VERSION ""

NS_ :

BS_:

BU_: ILC4 ILC3 ILC2 ILC1 C1 C0 ACU ECAS2 CCU TPMS ACC AEBS Door4 Door3 Door2 Door1 WWCU HVAC HVAC_HMI EPHS LDWS SCSM EVCC ECAS1 BMS SWS EBS VCU2 PCi_ECM DCU EPH VFC VCU1 Tachograph EPIC

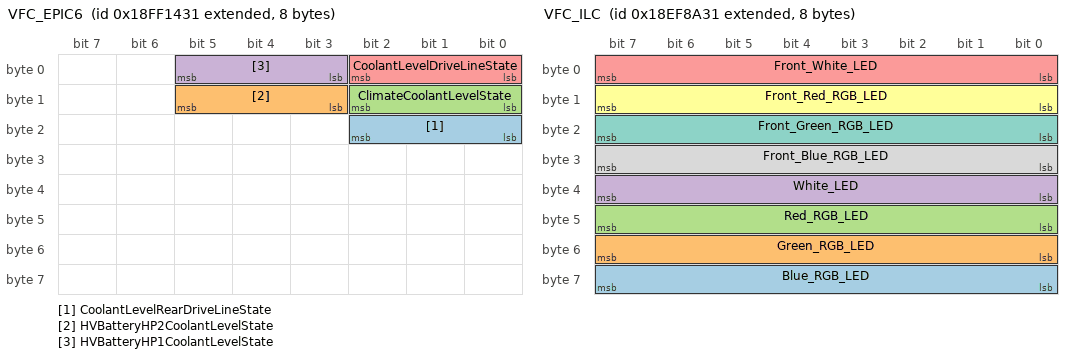
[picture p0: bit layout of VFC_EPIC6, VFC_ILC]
BO_ 2566853681 VFC_EPIC6: 8 VFC
 SG_ CoolantLevelRearDriveLineState : 16|3@1+ (1,0) [0|0] "" Vector__XXX
 SG_ HVBatteryHP2CoolantLevelState : 11|3@1+ (1,0) [0|0] "" Vector__XXX
 SG_ ClimateCoolantLevelState : 8|3@1+ (1,0) [0|0] "" Vector__XXX
 SG_ HVBatteryHP1CoolantLevelState : 3|3@1+ (1,0) [0|0] "" Vector__XXX
 SG_ CoolantLevelDriveLineState : 0|3@1+ (1,0) [0|0] "" Vector__XXX

BO_ 2147548812 DM1_ILC3_0000: 22 ILC3
 SG_ FailureModeIdentifier5 : 160|5@1+ (1,0) [0|0] "" Vector__XXX
 SG_ FailureModeIdentifier4 : 128|5@1+ (1,0) [0|0] "" Vector__XXX
 SG_ FailureModeIdentifier3 : 96|5@1+ (1,0) [0|0] "" Vector__XXX
 SG_ FailureModeIdentifier2 : 64|5@1+ (1,0) [0|0] "" Vector__XXX
 SG_ OccurenceCount5 : 168|7@1+ (1,0) [0|126] "" Vector__XXX
 SG_ OccurenceCount4 : 136|7@1+ (1,0) [0|126] "" Vector__XXX
 SG_ OccurenceCount3 : 104|7@1+ (1,0) [0|126] "" Vector__XXX
 SG_ OccurenceCount2 : 72|7@1+ (1,0) [0|126] "" Vector__XXX
 SG_ SPNConversionMethod5 : 175|1@1+ (1,0) [0|1] "" Vector__XXX
 SG_ SPNConversionMethod4 : 143|1@1+ (1,0) [0|1] "" Vector__XXX
 SG_ SPNConversionMethod3 : 111|1@1+ (1,0) [0|1] "" Vector__XXX
 SG_ SPNConversionMethod2 : 79|1@1+ (1,0) [0|1] "" Vector__XXX
 SG_ SPN5High : 165|3@1+ (1,0) [0|7] "" Vector__XXX
 SG_ SPN5 : 144|16@1+ (1,0) [0|65536] "" Vector__XXX
 SG_ SPN4High : 133|3@1+ (1,0) [0|7] "" Vector__XXX
 SG_ SPN4 : 112|16@1+ (1,0) [0|65536] "" Vector__XXX
 SG_ SPN3High : 101|3@1+ (1,0) [0|7] "" Vector__XXX
 SG_ SPN3 : 80|16@1+ (1,0) [0|65536] "" Vector__XXX
 SG_ SPN2High : 69|3@1+ (1,0) [0|7] "" Vector__XXX
 SG_ SPN2 : 48|16@1+ (1,0) [0|65536] "" Vector__XXX
 SG_ SPN1 : 16|16@1+ (1,0) [0|65536] "" Vector__XXX
 SG_ SPNConversionMethod1 : 47|1@1+ (1,0) [0|1] "" Vector__XXX
 SG_ OccurenceCount1 : 40|7@1+ (1,0) [0|126] "" Vector__XXX
 SG_ SPN1High : 37|3@1+ (1,0) [0|7] "" Vector__XXX
 SG_ FailureModeIdentifier1 : 32|5@1+ (1,0) [0|0] "" Vector__XXX
 SG_ FlashMalfuncIndicatorLamp : 14|2@1+ (1,0) [0|3] "" Vector__XXX
 SG_ FlashRedStopLamp : 12|2@1+ (1,0) [0|3] "" Vector__XXX
 SG_ FlashAmberWarningLamp : 10|2@1+ (1,0) [0|3] "" Vector__XXX
 SG_ FlashProtectLamp : 8|2@1+ (1,0) [0|3] "" Vector__XXX
 SG_ MalfunctionIndicatorLampStatus : 6|2@1+ (1,0) [0|3] "" Vector__XXX
 SG_ RedStopLampState : 4|2@1+ (1,0) [0|3] "" Vector__XXX
 SG_ AmberWarningLampStatus : 2|2@1+ (1,0) [0|3] "" Vector__XXX
 SG_ ProtectLampStatus : 0|2@1+ (1,0) [0|3] "" Vector__XXX

BO_ 2566834829 DM1_ILC4: 22 ILC4
 SG_ FailureModeIdentifier5 : 160|5@1+ (1,0) [0|0] "" Vector__XXX
 SG_ FailureModeIdentifier4 : 128|5@1+ (1,0) [0|0] "" Vector__XXX
 SG_ FailureModeIdentifier3 : 96|5@1+ (1,0) [0|0] "" Vector__XXX
 SG_ FailureModeIdentifier2 : 64|5@1+ (1,0) [0|0] "" Vector__XXX
 SG_ OccurenceCount5 : 168|7@1+ (1,0) [0|126] "" Vector__XXX
 SG_ OccurenceCount4 : 136|7@1+ (1,0) [0|126] "" Vector__XXX
 SG_ OccurenceCount3 : 104|7@1+ (1,0) [0|126] "" Vector__XXX
 SG_ OccurenceCount2 : 72|7@1+ (1,0) [0|126] "" Vector__XXX
 SG_ SPNConversionMethod5 : 175|1@1+ (1,0) [0|1] "" Vector__XXX
 SG_ SPNConversionMethod4 : 143|1@1+ (1,0) [0|1] "" Vector__XXX
 SG_ SPNConversionMethod3 : 111|1@1+ (1,0) [0|1] "" Vector__XXX
 SG_ SPNConversionMethod2 : 79|1@1+ (1,0) [0|1] "" Vector__XXX
 SG_ SPN5High : 165|3@1+ (1,0) [0|7] "" Vector__XXX
 SG_ SPN5 : 144|16@1+ (1,0) [0|65536] "" Vector__XXX
 SG_ SPN4High : 133|3@1+ (1,0) [0|7] "" Vector__XXX
 SG_ SPN4 : 112|16@1+ (1,0) [0|65536] "" Vector__XXX
 SG_ SPN3High : 101|3@1+ (1,0) [0|7] "" Vector__XXX
 SG_ SPN3 : 80|16@1+ (1,0) [0|65536] "" Vector__XXX
 SG_ SPN2High : 69|3@1+ (1,0) [0|7] "" Vector__XXX
 SG_ SPN2 : 48|16@1+ (1,0) [0|65536] "" Vector__XXX
 SG_ SPN1 : 16|16@1+ (1,0) [0|65536] "" Vector__XXX
 SG_ SPNConversionMethod1 : 47|1@1+ (1,0) [0|1] "" Vector__XXX
 SG_ OccurenceCount1 : 40|7@1+ (1,0) [0|126] "" Vector__XXX
 SG_ SPN1High : 37|3@1+ (1,0) [0|7] "" Vector__XXX
 SG_ FailureModeIdentifier1 : 32|5@1+ (1,0) [0|0] "" Vector__XXX
 SG_ FlashMalfuncIndicatorLamp : 14|2@1+ (1,0) [0|3] "" Vector__XXX
 SG_ FlashRedStopLamp : 12|2@1+ (1,0) [0|3] "" Vector__XXX
 SG_ FlashAmberWarningLamp : 10|2@1+ (1,0) [0|3] "" Vector__XXX
 SG_ FlashProtectLamp : 8|2@1+ (1,0) [0|3] "" Vector__XXX
 SG_ MalfunctionIndicatorLampStatus : 6|2@1+ (1,0) [0|3] "" Vector__XXX
 SG_ RedStopLampState : 4|2@1+ (1,0) [0|3] "" Vector__XXX
 SG_ AmberWarningLampStatus : 2|2@1+ (1,0) [0|3] "" Vector__XXX
 SG_ ProtectLampStatus : 0|2@1+ (1,0) [0|3] "" Vector__XXX

BO_ 2147483648 DM1_ILC3: 22 Vector__XXX
 SG_ FailureModeIdentifier5 : 160|5@1+ (1,0) [0|0] "" Vector__XXX
 SG_ FailureModeIdentifier4 : 128|5@1+ (1,0) [0|0] "" Vector__XXX
 SG_ FailureModeIdentifier3 : 96|5@1+ (1,0) [0|0] "" Vector__XXX
 SG_ FailureModeIdentifier2 : 64|5@1+ (1,0) [0|0] "" Vector__XXX
 SG_ OccurenceCount5 : 168|7@1+ (1,0) [0|126] "" Vector__XXX
 SG_ OccurenceCount4 : 136|7@1+ (1,0) [0|126] "" Vector__XXX
 SG_ OccurenceCount3 : 104|7@1+ (1,0) [0|126] "" Vector__XXX
 SG_ OccurenceCount2 : 72|7@1+ (1,0) [0|126] "" Vector__XXX
 SG_ SPNConversionMethod5 : 175|1@1+ (1,0) [0|1] "" Vector__XXX
 SG_ SPNConversionMethod4 : 143|1@1+ (1,0) [0|1] "" Vector__XXX
 SG_ SPNConversionMethod3 : 111|1@1+ (1,0) [0|1] "" Vector__XXX
 SG_ SPNConversionMethod2 : 79|1@1+ (1,0) [0|1] "" Vector__XXX
 SG_ SPN5High : 165|3@1+ (1,0) [0|7] "" Vector__XXX
 SG_ SPN5 : 144|16@1+ (1,0) [0|65536] "" Vector__XXX
 SG_ SPN4High : 133|3@1+ (1,0) [0|7] "" Vector__XXX
 SG_ SPN4 : 112|16@1+ (1,0) [0|65536] "" Vector__XXX
 SG_ SPN3High : 101|3@1+ (1,0) [0|7] "" Vector__XXX
 SG_ SPN3 : 80|16@1+ (1,0) [0|65536] "" Vector__XXX
 SG_ SPN2High : 69|3@1+ (1,0) [0|7] "" Vector__XXX
 SG_ SPN2 : 48|16@1+ (1,0) [0|65536] "" Vector__XXX
 SG_ SPN1 : 16|16@1+ (1,0) [0|65536] "" Vector__XXX
 SG_ SPNConversionMethod1 : 47|1@1+ (1,0) [0|1] "" Vector__XXX
 SG_ OccurenceCount1 : 40|7@1+ (1,0) [0|126] "" Vector__XXX
 SG_ SPN1High : 37|3@1+ (1,0) [0|7] "" Vector__XXX
 SG_ FailureModeIdentifier1 : 32|5@1+ (1,0) [0|0] "" Vector__XXX
 SG_ FlashMalfuncIndicatorLamp : 14|2@1+ (1,0) [0|3] "" Vector__XXX
 SG_ FlashRedStopLamp : 12|2@1+ (1,0) [0|3] "" Vector__XXX
 SG_ FlashAmberWarningLamp : 10|2@1+ (1,0) [0|3] "" Vector__XXX
 SG_ FlashProtectLamp : 8|2@1+ (1,0) [0|3] "" Vector__XXX
 SG_ MalfunctionIndicatorLampStatus : 6|2@1+ (1,0) [0|3] "" Vector__XXX
 SG_ RedStopLampState : 4|2@1+ (1,0) [0|3] "" Vector__XXX
 SG_ AmberWarningLampStatus : 2|2@1+ (1,0) [0|3] "" Vector__XXX
 SG_ ProtectLampStatus : 0|2@1+ (1,0) [0|3] "" Vector__XXX

BO_ 2566834827 DM1_ILC2: 22 ILC2
 SG_ FailureModeIdentifier5 : 160|5@1+ (1,0) [0|0] "" Vector__XXX
 SG_ FailureModeIdentifier4 : 128|5@1+ (1,0) [0|0] "" Vector__XXX
 SG_ FailureModeIdentifier3 : 96|5@1+ (1,0) [0|0] "" Vector__XXX
 SG_ FailureModeIdentifier2 : 64|5@1+ (1,0) [0|0] "" Vector__XXX
 SG_ OccurenceCount5 : 168|7@1+ (1,0) [0|126] "" Vector__XXX
 SG_ OccurenceCount4 : 136|7@1+ (1,0) [0|126] "" Vector__XXX
 SG_ OccurenceCount3 : 104|7@1+ (1,0) [0|126] "" Vector__XXX
 SG_ OccurenceCount2 : 72|7@1+ (1,0) [0|126] "" Vector__XXX
 SG_ SPNConversionMethod5 : 175|1@1+ (1,0) [0|1] "" Vector__XXX
 SG_ SPNConversionMethod4 : 143|1@1+ (1,0) [0|1] "" Vector__XXX
 SG_ SPNConversionMethod3 : 111|1@1+ (1,0) [0|1] "" Vector__XXX
 SG_ SPNConversionMethod2 : 79|1@1+ (1,0) [0|1] "" Vector__XXX
 SG_ SPN5High : 165|3@1+ (1,0) [0|7] "" Vector__XXX
 SG_ SPN5 : 144|16@1+ (1,0) [0|65536] "" Vector__XXX
 SG_ SPN4High : 133|3@1+ (1,0) [0|7] "" Vector__XXX
 SG_ SPN4 : 112|16@1+ (1,0) [0|65536] "" Vector__XXX
 SG_ SPN3High : 101|3@1+ (1,0) [0|7] "" Vector__XXX
 SG_ SPN3 : 80|16@1+ (1,0) [0|65536] "" Vector__XXX
 SG_ SPN2High : 69|3@1+ (1,0) [0|7] "" Vector__XXX
 SG_ SPN2 : 48|16@1+ (1,0) [0|65536] "" Vector__XXX
 SG_ SPN1 : 16|16@1+ (1,0) [0|65536] "" Vector__XXX
 SG_ SPNConversionMethod1 : 47|1@1+ (1,0) [0|1] "" Vector__XXX
 SG_ OccurenceCount1 : 40|7@1+ (1,0) [0|126] "" Vector__XXX
 SG_ SPN1High : 37|3@1+ (1,0) [0|7] "" Vector__XXX
 SG_ FailureModeIdentifier1 : 32|5@1+ (1,0) [0|0] "" Vector__XXX
 SG_ FlashMalfuncIndicatorLamp : 14|2@1+ (1,0) [0|3] "" Vector__XXX
 SG_ FlashRedStopLamp : 12|2@1+ (1,0) [0|3] "" Vector__XXX
 SG_ FlashAmberWarningLamp : 10|2@1+ (1,0) [0|3] "" Vector__XXX
 SG_ FlashProtectLamp : 8|2@1+ (1,0) [0|3] "" Vector__XXX
 SG_ MalfunctionIndicatorLampStatus : 6|2@1+ (1,0) [0|3] "" Vector__XXX
 SG_ RedStopLampState : 4|2@1+ (1,0) [0|3] "" Vector__XXX
 SG_ AmberWarningLampStatus : 2|2@1+ (1,0) [0|3] "" Vector__XXX
 SG_ ProtectLampStatus : 0|2@1+ (1,0) [0|3] "" Vector__XXX

BO_ 2566834826 DM1_ILC1: 22 ILC1
 SG_ FailureModeIdentifier5 : 160|5@1+ (1,0) [0|0] "" Vector__XXX
 SG_ FailureModeIdentifier4 : 128|5@1+ (1,0) [0|0] "" Vector__XXX
 SG_ FailureModeIdentifier3 : 96|5@1+ (1,0) [0|0] "" Vector__XXX
 SG_ FailureModeIdentifier2 : 64|5@1+ (1,0) [0|0] "" Vector__XXX
 SG_ OccurenceCount5 : 168|7@1+ (1,0) [0|126] "" Vector__XXX
 SG_ OccurenceCount4 : 136|7@1+ (1,0) [0|126] "" Vector__XXX
 SG_ OccurenceCount3 : 104|7@1+ (1,0) [0|126] "" Vector__XXX
 SG_ OccurenceCount2 : 72|7@1+ (1,0) [0|126] "" Vector__XXX
 SG_ SPNConversionMethod5 : 175|1@1+ (1,0) [0|1] "" Vector__XXX
 SG_ SPNConversionMethod4 : 143|1@1+ (1,0) [0|1] "" Vector__XXX
 SG_ SPNConversionMethod3 : 111|1@1+ (1,0) [0|1] "" Vector__XXX
 SG_ SPNConversionMethod2 : 79|1@1+ (1,0) [0|1] "" Vector__XXX
 SG_ SPN5High : 165|3@1+ (1,0) [0|7] "" Vector__XXX
 SG_ SPN5 : 144|16@1+ (1,0) [0|65536] "" Vector__XXX
 SG_ SPN4High : 133|3@1+ (1,0) [0|7] "" Vector__XXX
 SG_ SPN4 : 112|16@1+ (1,0) [0|65536] "" Vector__XXX
 SG_ SPN3High : 101|3@1+ (1,0) [0|7] "" Vector__XXX
 SG_ SPN3 : 80|16@1+ (1,0) [0|65536] "" Vector__XXX
 SG_ SPN2High : 69|3@1+ (1,0) [0|7] "" Vector__XXX
 SG_ SPN2 : 48|16@1+ (1,0) [0|65536] "" Vector__XXX
 SG_ SPN1 : 16|16@1+ (1,0) [0|65536] "" Vector__XXX
 SG_ SPNConversionMethod1 : 47|1@1+ (1,0) [0|1] "" Vector__XXX
 SG_ OccurenceCount1 : 40|7@1+ (1,0) [0|126] "" Vector__XXX
 SG_ SPN1High : 37|3@1+ (1,0) [0|7] "" Vector__XXX
 SG_ FailureModeIdentifier1 : 32|5@1+ (1,0) [0|0] "" Vector__XXX
 SG_ FlashMalfuncIndicatorLamp : 14|2@1+ (1,0) [0|3] "" Vector__XXX
 SG_ FlashRedStopLamp : 12|2@1+ (1,0) [0|3] "" Vector__XXX
 SG_ FlashAmberWarningLamp : 10|2@1+ (1,0) [0|3] "" Vector__XXX
 SG_ FlashProtectLamp : 8|2@1+ (1,0) [0|3] "" Vector__XXX
 SG_ MalfunctionIndicatorLampStatus : 6|2@1+ (1,0) [0|3] "" Vector__XXX
 SG_ RedStopLampState : 4|2@1+ (1,0) [0|3] "" Vector__XXX
 SG_ AmberWarningLampStatus : 2|2@1+ (1,0) [0|3] "" Vector__XXX
 SG_ ProtectLampStatus : 0|2@1+ (1,0) [0|3] "" Vector__XXX

BO_ 2565835313 VFC_ILC: 8 VFC
 SG_ Blue_RGB_LED : 56|8@1+ (0.4,0) [0|250] "%" Vector__XXX
 SG_ Green_RGB_LED : 48|8@1+ (0.4,0) [0|250] "%" Vector__XXX
 SG_ Red_RGB_LED : 40|8@1+ (0.4,0) [0|250] "%" Vector__XXX
 SG_ White_LED : 32|8@1+ (0.4,0) [0|250] "%" Vector__XXX
 SG_ Front_White_LED : 0|8@1+ (0.4,0) [0|250] "%" Vector__XXX
 SG_ Front_Red_RGB_LED : 8|8@1+ (0.4,0) [0|250] "%" Vector__XXX
 SG_ Front_Green_RGB_LED : 16|8@1+ (0.4,0) [0|250] "%" Vector__XXX
 SG_ Front_Blue_RGB_LED : 24|8@1+ (0.4,0) [0|250] "%" Vector__XXX

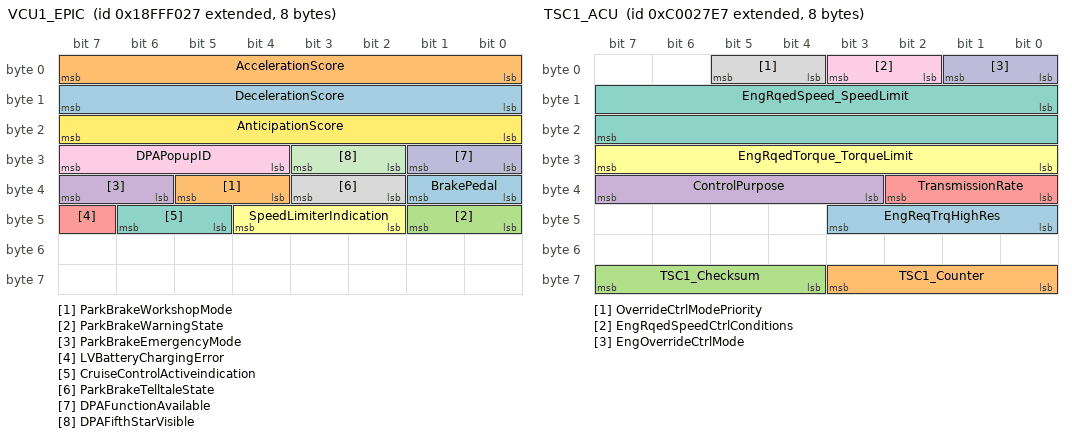
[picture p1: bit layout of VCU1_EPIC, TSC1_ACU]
BO_ 2566909991 VCU1_EPIC: 8 VCU1
 SG_ BrakePedal : 32|2@1+ (1,0) [0|0] "" Vector__XXX
 SG_ ParkBrakeWorkshopMode : 36|2@1+ (1,0) [0|0] "" Vector__XXX
 SG_ ParkBrakeWarningState : 40|2@1+ (1,0) [0|0] "" Vector__XXX
 SG_ ParkBrakeEmergencyMode : 38|2@1+ (1,0) [0|0] "" Vector__XXX
 SG_ LVBatteryChargingError : 47|1@1+ (1,0) [0|0] "" Vector__XXX
 SG_ SpeedLimiterIndication : 42|3@1+ (1,0) [0|0] "" Vector__XXX
 SG_ CruiseControlActiveindication : 45|2@1+ (1,0) [0|0] "" Vector__XXX
 SG_ ParkBrakeTelltaleState : 34|2@1+ (1,0) [0|0] "" Vector__XXX
 SG_ DPAPopupID : 28|4@1+ (1,0) [0|15] "PopupID" Vector__XXX
 SG_ DPAFunctionAvailable : 24|2@1+ (1,0) [0|3] "flag" Vector__XXX
 SG_ DPAFifthStarVisible : 26|2@1+ (1,0) [0|3] "flag" Vector__XXX
 SG_ AnticipationScore : 16|8@1+ (0.5,0) [0|250] "%" Vector__XXX
 SG_ DecelerationScore : 8|8@1+ (0.5,0) [0|250] "%" Vector__XXX
 SG_ AccelerationScore : 0|8@1+ (0.5,0) [0|250] "%" Vector__XXX

BO_ 2566834920 DM1_LDWS: 22 LDWS
 SG_ FailureModeIdentifier5 : 160|5@1+ (1,0) [0|0] "" Vector__XXX
 SG_ FailureModeIdentifier4 : 128|5@1+ (1,0) [0|0] "" Vector__XXX
 SG_ FailureModeIdentifier3 : 96|5@1+ (1,0) [0|0] "" Vector__XXX
 SG_ FailureModeIdentifier2 : 64|5@1+ (1,0) [0|0] "" Vector__XXX
 SG_ OccurenceCount5 : 168|7@1+ (1,0) [0|126] "" Vector__XXX
 SG_ OccurenceCount4 : 136|7@1+ (1,0) [0|126] "" Vector__XXX
 SG_ OccurenceCount3 : 104|7@1+ (1,0) [0|126] "" Vector__XXX
 SG_ OccurenceCount2 : 72|7@1+ (1,0) [0|126] "" Vector__XXX
 SG_ SPNConversionMethod5 : 175|1@1+ (1,0) [0|1] "" Vector__XXX
 SG_ SPNConversionMethod4 : 143|1@1+ (1,0) [0|1] "" Vector__XXX
 SG_ SPNConversionMethod3 : 111|1@1+ (1,0) [0|1] "" Vector__XXX
 SG_ SPNConversionMethod2 : 79|1@1+ (1,0) [0|1] "" Vector__XXX
 SG_ SPN5High : 165|3@1+ (1,0) [0|7] "" Vector__XXX
 SG_ SPN5 : 144|16@1+ (1,0) [0|65536] "" Vector__XXX
 SG_ SPN4High : 133|3@1+ (1,0) [0|7] "" Vector__XXX
 SG_ SPN4 : 112|16@1+ (1,0) [0|65536] "" Vector__XXX
 SG_ SPN3High : 101|3@1+ (1,0) [0|7] "" Vector__XXX
 SG_ SPN3 : 80|16@1+ (1,0) [0|65536] "" Vector__XXX
 SG_ SPN2High : 69|3@1+ (1,0) [0|7] "" Vector__XXX
 SG_ SPN2 : 48|16@1+ (1,0) [0|65536] "" Vector__XXX
 SG_ SPN1 : 16|16@1+ (1,0) [0|65536] "" Vector__XXX
 SG_ SPNConversionMethod1 : 47|1@1+ (1,0) [0|1] "" Vector__XXX
 SG_ OccurenceCount1 : 40|7@1+ (1,0) [0|126] "" Vector__XXX
 SG_ SPN1High : 37|3@1+ (1,0) [0|7] "" Vector__XXX
 SG_ FailureModeIdentifier1 : 32|5@1+ (1,0) [0|0] "" Vector__XXX
 SG_ FlashMalfuncIndicatorLamp : 14|2@1+ (1,0) [0|3] "" Vector__XXX
 SG_ FlashRedStopLamp : 12|2@1+ (1,0) [0|3] "" Vector__XXX
 SG_ FlashAmberWarningLamp : 10|2@1+ (1,0) [0|3] "" Vector__XXX
 SG_ FlashProtectLamp : 8|2@1+ (1,0) [0|3] "" Vector__XXX
 SG_ MalfunctionIndicatorLampStatus : 6|2@1+ (1,0) [0|3] "" Vector__XXX
 SG_ RedStopLampState : 4|2@1+ (1,0) [0|3] "" Vector__XXX
 SG_ AmberWarningLampStatus : 2|2@1+ (1,0) [0|3] "" Vector__XXX
 SG_ ProtectLampStatus : 0|2@1+ (1,0) [0|3] "" Vector__XXX

BO_ 2566834752 DM1_ECAS2: 22 ECAS2
 SG_ FailureModeIdentifier5 : 160|5@1+ (1,0) [0|0] "" Vector__XXX
 SG_ FailureModeIdentifier4 : 128|5@1+ (1,0) [0|0] "" Vector__XXX
 SG_ FailureModeIdentifier3 : 96|5@1+ (1,0) [0|0] "" Vector__XXX
 SG_ FailureModeIdentifier2 : 64|5@1+ (1,0) [0|0] "" Vector__XXX
 SG_ OccurenceCount5 : 168|7@1+ (1,0) [0|126] "" Vector__XXX
 SG_ OccurenceCount4 : 136|7@1+ (1,0) [0|126] "" Vector__XXX
 SG_ OccurenceCount3 : 104|7@1+ (1,0) [0|126] "" Vector__XXX
 SG_ OccurenceCount2 : 72|7@1+ (1,0) [0|126] "" Vector__XXX
 SG_ SPNConversionMethod5 : 175|1@1+ (1,0) [0|1] "" Vector__XXX
 SG_ SPNConversionMethod4 : 143|1@1+ (1,0) [0|1] "" Vector__XXX
 SG_ SPNConversionMethod3 : 111|1@1+ (1,0) [0|1] "" Vector__XXX
 SG_ SPNConversionMethod2 : 79|1@1+ (1,0) [0|1] "" Vector__XXX
 SG_ SPN5High : 165|3@1+ (1,0) [0|7] "" Vector__XXX
 SG_ SPN5 : 144|16@1+ (1,0) [0|65536] "" Vector__XXX
 SG_ SPN4High : 133|3@1+ (1,0) [0|7] "" Vector__XXX
 SG_ SPN4 : 112|16@1+ (1,0) [0|65536] "" Vector__XXX
 SG_ SPN3High : 101|3@1+ (1,0) [0|7] "" Vector__XXX
 SG_ SPN3 : 80|16@1+ (1,0) [0|65536] "" Vector__XXX
 SG_ SPN2High : 69|3@1+ (1,0) [0|7] "" Vector__XXX
 SG_ SPN2 : 48|16@1+ (1,0) [0|65536] "" Vector__XXX
 SG_ SPN1 : 16|16@1+ (1,0) [0|65536] "" Vector__XXX
 SG_ SPNConversionMethod1 : 47|1@1+ (1,0) [0|1] "" Vector__XXX
 SG_ OccurenceCount1 : 40|7@1+ (1,0) [0|126] "" Vector__XXX
 SG_ SPN1High : 37|3@1+ (1,0) [0|7] "" Vector__XXX
 SG_ FailureModeIdentifier1 : 32|5@1+ (1,0) [0|0] "" Vector__XXX
 SG_ FlashMalfuncIndicatorLamp : 14|2@1+ (1,0) [0|3] "" Vector__XXX
 SG_ FlashRedStopLamp : 12|2@1+ (1,0) [0|3] "" Vector__XXX
 SG_ FlashAmberWarningLamp : 10|2@1+ (1,0) [0|3] "" Vector__XXX
 SG_ FlashProtectLamp : 8|2@1+ (1,0) [0|3] "" Vector__XXX
 SG_ MalfunctionIndicatorLampStatus : 6|2@1+ (1,0) [0|3] "" Vector__XXX
 SG_ RedStopLampState : 4|2@1+ (1,0) [0|3] "" Vector__XXX
 SG_ AmberWarningLampStatus : 2|2@1+ (1,0) [0|3] "" Vector__XXX
 SG_ ProtectLampStatus : 0|2@1+ (1,0) [0|3] "" Vector__XXX

BO_ 2566834881 DM1_C1: 22 C1
 SG_ FailureModeIdentifier5 : 160|5@1+ (1,0) [0|0] "" Vector__XXX
 SG_ FailureModeIdentifier4 : 128|5@1+ (1,0) [0|0] "" Vector__XXX
 SG_ FailureModeIdentifier3 : 96|5@1+ (1,0) [0|0] "" Vector__XXX
 SG_ FailureModeIdentifier2 : 64|5@1+ (1,0) [0|0] "" Vector__XXX
 SG_ OccurenceCount5 : 168|7@1+ (1,0) [0|126] "" Vector__XXX
 SG_ OccurenceCount4 : 136|7@1+ (1,0) [0|126] "" Vector__XXX
 SG_ OccurenceCount3 : 104|7@1+ (1,0) [0|126] "" Vector__XXX
 SG_ OccurenceCount2 : 72|7@1+ (1,0) [0|126] "" Vector__XXX
 SG_ SPNConversionMethod5 : 175|1@1+ (1,0) [0|1] "" Vector__XXX
 SG_ SPNConversionMethod4 : 143|1@1+ (1,0) [0|1] "" Vector__XXX
 SG_ SPNConversionMethod3 : 111|1@1+ (1,0) [0|1] "" Vector__XXX
 SG_ SPNConversionMethod2 : 79|1@1+ (1,0) [0|1] "" Vector__XXX
 SG_ SPN5High : 165|3@1+ (1,0) [0|7] "" Vector__XXX
 SG_ SPN5 : 144|16@1+ (1,0) [0|65536] "" Vector__XXX
 SG_ SPN4High : 133|3@1+ (1,0) [0|7] "" Vector__XXX
 SG_ SPN4 : 112|16@1+ (1,0) [0|65536] "" Vector__XXX
 SG_ SPN3High : 101|3@1+ (1,0) [0|7] "" Vector__XXX
 SG_ SPN3 : 80|16@1+ (1,0) [0|65536] "" Vector__XXX
 SG_ SPN2High : 69|3@1+ (1,0) [0|7] "" Vector__XXX
 SG_ SPN2 : 48|16@1+ (1,0) [0|65536] "" Vector__XXX
 SG_ SPN1 : 16|16@1+ (1,0) [0|65536] "" Vector__XXX
 SG_ SPNConversionMethod1 : 47|1@1+ (1,0) [0|1] "" Vector__XXX
 SG_ OccurenceCount1 : 40|7@1+ (1,0) [0|126] "" Vector__XXX
 SG_ SPN1High : 37|3@1+ (1,0) [0|7] "" Vector__XXX
 SG_ FailureModeIdentifier1 : 32|5@1+ (1,0) [0|0] "" Vector__XXX
 SG_ FlashMalfuncIndicatorLamp : 14|2@1+ (1,0) [0|3] "" Vector__XXX
 SG_ FlashRedStopLamp : 12|2@1+ (1,0) [0|3] "" Vector__XXX
 SG_ FlashAmberWarningLamp : 10|2@1+ (1,0) [0|3] "" Vector__XXX
 SG_ FlashProtectLamp : 8|2@1+ (1,0) [0|3] "" Vector__XXX
 SG_ MalfunctionIndicatorLampStatus : 6|2@1+ (1,0) [0|3] "" Vector__XXX
 SG_ RedStopLampState : 4|2@1+ (1,0) [0|3] "" Vector__XXX
 SG_ AmberWarningLampStatus : 2|2@1+ (1,0) [0|3] "" Vector__XXX
 SG_ ProtectLampStatus : 0|2@1+ (1,0) [0|3] "" Vector__XXX

BO_ 2566834880 DM1_C0: 22 C0
 SG_ FailureModeIdentifier5 : 160|5@1+ (1,0) [0|0] "" Vector__XXX
 SG_ FailureModeIdentifier4 : 128|5@1+ (1,0) [0|0] "" Vector__XXX
 SG_ FailureModeIdentifier3 : 96|5@1+ (1,0) [0|0] "" Vector__XXX
 SG_ FailureModeIdentifier2 : 64|5@1+ (1,0) [0|0] "" Vector__XXX
 SG_ OccurenceCount5 : 168|7@1+ (1,0) [0|126] "" Vector__XXX
 SG_ OccurenceCount4 : 136|7@1+ (1,0) [0|126] "" Vector__XXX
 SG_ OccurenceCount3 : 104|7@1+ (1,0) [0|126] "" Vector__XXX
 SG_ OccurenceCount2 : 72|7@1+ (1,0) [0|126] "" Vector__XXX
 SG_ SPNConversionMethod5 : 175|1@1+ (1,0) [0|1] "" Vector__XXX
 SG_ SPNConversionMethod4 : 143|1@1+ (1,0) [0|1] "" Vector__XXX
 SG_ SPNConversionMethod3 : 111|1@1+ (1,0) [0|1] "" Vector__XXX
 SG_ SPNConversionMethod2 : 79|1@1+ (1,0) [0|1] "" Vector__XXX
 SG_ SPN5High : 165|3@1+ (1,0) [0|7] "" Vector__XXX
 SG_ SPN5 : 144|16@1+ (1,0) [0|65536] "" Vector__XXX
 SG_ SPN4High : 133|3@1+ (1,0) [0|7] "" Vector__XXX
 SG_ SPN4 : 112|16@1+ (1,0) [0|65536] "" Vector__XXX
 SG_ SPN3High : 101|3@1+ (1,0) [0|7] "" Vector__XXX
 SG_ SPN3 : 80|16@1+ (1,0) [0|65536] "" Vector__XXX
 SG_ SPN2High : 69|3@1+ (1,0) [0|7] "" Vector__XXX
 SG_ SPN2 : 48|16@1+ (1,0) [0|65536] "" Vector__XXX
 SG_ SPN1 : 16|16@1+ (1,0) [0|65536] "" Vector__XXX
 SG_ SPNConversionMethod1 : 47|1@1+ (1,0) [0|1] "" Vector__XXX
 SG_ OccurenceCount1 : 40|7@1+ (1,0) [0|126] "" Vector__XXX
 SG_ SPN1High : 37|3@1+ (1,0) [0|7] "" Vector__XXX
 SG_ FailureModeIdentifier1 : 32|5@1+ (1,0) [0|0] "" Vector__XXX
 SG_ FlashMalfuncIndicatorLamp : 14|2@1+ (1,0) [0|3] "" Vector__XXX
 SG_ FlashRedStopLamp : 12|2@1+ (1,0) [0|3] "" Vector__XXX
 SG_ FlashAmberWarningLamp : 10|2@1+ (1,0) [0|3] "" Vector__XXX
 SG_ FlashProtectLamp : 8|2@1+ (1,0) [0|3] "" Vector__XXX
 SG_ MalfunctionIndicatorLampStatus : 6|2@1+ (1,0) [0|3] "" Vector__XXX
 SG_ RedStopLampState : 4|2@1+ (1,0) [0|3] "" Vector__XXX
 SG_ AmberWarningLampStatus : 2|2@1+ (1,0) [0|3] "" Vector__XXX
 SG_ ProtectLampStatus : 0|2@1+ (1,0) [0|3] "" Vector__XXX

BO_ 2566834848 DM1_AEBS: 22 AEBS
 SG_ FailureModeIdentifier5 : 160|5@1+ (1,0) [0|0] "" Vector__XXX
 SG_ FailureModeIdentifier4 : 128|5@1+ (1,0) [0|0] "" Vector__XXX
 SG_ FailureModeIdentifier3 : 96|5@1+ (1,0) [0|0] "" Vector__XXX
 SG_ FailureModeIdentifier2 : 64|5@1+ (1,0) [0|0] "" Vector__XXX
 SG_ OccurenceCount5 : 168|7@1+ (1,0) [0|126] "" Vector__XXX
 SG_ OccurenceCount4 : 136|7@1+ (1,0) [0|126] "" Vector__XXX
 SG_ OccurenceCount3 : 104|7@1+ (1,0) [0|126] "" Vector__XXX
 SG_ OccurenceCount2 : 72|7@1+ (1,0) [0|126] "" Vector__XXX
 SG_ SPNConversionMethod5 : 175|1@1+ (1,0) [0|1] "" Vector__XXX
 SG_ SPNConversionMethod4 : 143|1@1+ (1,0) [0|1] "" Vector__XXX
 SG_ SPNConversionMethod3 : 111|1@1+ (1,0) [0|1] "" Vector__XXX
 SG_ SPNConversionMethod2 : 79|1@1+ (1,0) [0|1] "" Vector__XXX
 SG_ SPN5High : 165|3@1+ (1,0) [0|7] "" Vector__XXX
 SG_ SPN5 : 144|16@1+ (1,0) [0|65536] "" Vector__XXX
 SG_ SPN4High : 133|3@1+ (1,0) [0|7] "" Vector__XXX
 SG_ SPN4 : 112|16@1+ (1,0) [0|65536] "" Vector__XXX
 SG_ SPN3High : 101|3@1+ (1,0) [0|7] "" Vector__XXX
 SG_ SPN3 : 80|16@1+ (1,0) [0|65536] "" Vector__XXX
 SG_ SPN2High : 69|3@1+ (1,0) [0|7] "" Vector__XXX
 SG_ SPN2 : 48|16@1+ (1,0) [0|65536] "" Vector__XXX
 SG_ SPN1 : 16|16@1+ (1,0) [0|65536] "" Vector__XXX
 SG_ SPNConversionMethod1 : 47|1@1+ (1,0) [0|1] "" Vector__XXX
 SG_ OccurenceCount1 : 40|7@1+ (1,0) [0|126] "" Vector__XXX
 SG_ SPN1High : 37|3@1+ (1,0) [0|7] "" Vector__XXX
 SG_ FailureModeIdentifier1 : 32|5@1+ (1,0) [0|0] "" Vector__XXX
 SG_ FlashMalfuncIndicatorLamp : 14|2@1+ (1,0) [0|3] "" Vector__XXX
 SG_ FlashRedStopLamp : 12|2@1+ (1,0) [0|3] "" Vector__XXX
 SG_ FlashAmberWarningLamp : 10|2@1+ (1,0) [0|3] "" Vector__XXX
 SG_ FlashProtectLamp : 8|2@1+ (1,0) [0|3] "" Vector__XXX
 SG_ MalfunctionIndicatorLampStatus : 6|2@1+ (1,0) [0|3] "" Vector__XXX
 SG_ RedStopLampState : 4|2@1+ (1,0) [0|3] "" Vector__XXX
 SG_ AmberWarningLampStatus : 2|2@1+ (1,0) [0|3] "" Vector__XXX
 SG_ ProtectLampStatus : 0|2@1+ (1,0) [0|3] "" Vector__XXX

BO_ 2566826033 ACTL_CPP: 8 VFC
 SG_ ArticulationAngle : 0|8@1+ (1,-125) [-125|125] "Deg" Vector__XXX

BO_ 2566907697 PropB_ACUTx: 8 VFC
 SG_ ArticulationProtectionOverrule : 0|2@1+ (1,0) [0|0] "" Vector__XXX

BO_ 2348820455 TSC1_ACU: 8 ACU
 SG_ EngReqTrqHighRes : 40|4@1+ (0.125,0) [0|1.875] ""  VCU1
 SG_ TSC1_Counter : 56|4@1+ (1,0) [0|0] ""  VCU1
 SG_ TSC1_Checksum : 60|4@1+ (1,0) [0|0] ""  VCU1
 SG_ ControlPurpose : 35|5@1+ (1,0) [0|31] ""  VCU1
 SG_ TransmissionRate : 32|3@1+ (1,0) [0|7] ""  VCU1
 SG_ EngRqedTorque_TorqueLimit : 24|8@1+ (1,-125) [-125|125] "%"  VCU1
 SG_ EngRqedSpeed_SpeedLimit : 8|16@1+ (0.125,0) [0|8031.875] "rpm"  VCU1
 SG_ OverrideCtrlModePriority : 4|2@1+ (1,0) [0|3] ""  VCU1
 SG_ EngRqedSpeedCtrlConditions : 2|2@1+ (1,0) [0|3] ""  VCU1
 SG_ EngOverrideCtrlMode : 0|2@1+ (1,0) [0|3] ""  VCU1

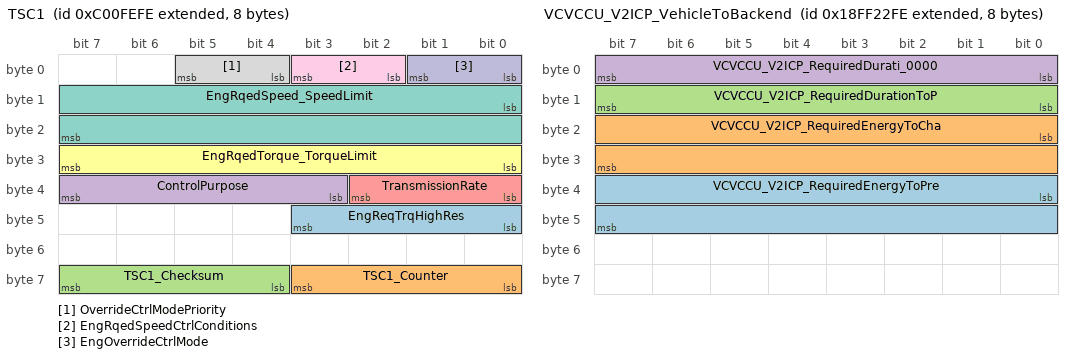
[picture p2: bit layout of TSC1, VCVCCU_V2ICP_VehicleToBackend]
BO_ 2348875518 TSC1: 8 Vector__XXX
 SG_ EngReqTrqHighRes : 40|4@1+ (0.125,0) [0|1.875] "" Vector__XXX
 SG_ TSC1_Counter : 56|4@1+ (1,0) [0|0] "" Vector__XXX
 SG_ TSC1_Checksum : 60|4@1+ (1,0) [0|0] "" Vector__XXX
 SG_ ControlPurpose : 35|5@1+ (1,0) [0|31] "" Vector__XXX
 SG_ TransmissionRate : 32|3@1+ (1,0) [0|7] "" Vector__XXX
 SG_ EngRqedTorque_TorqueLimit : 24|8@1+ (1,-125) [-125|125] "%" Vector__XXX
 SG_ EngRqedSpeed_SpeedLimit : 8|16@1+ (0.125,0) [0|8031.875] "rpm" Vector__XXX
 SG_ OverrideCtrlModePriority : 4|2@1+ (1,0) [0|3] "" Vector__XXX
 SG_ EngRqedSpeedCtrlConditions : 2|2@1+ (1,0) [0|3] "" Vector__XXX
 SG_ EngOverrideCtrlMode : 0|2@1+ (1,0) [0|3] "" Vector__XXX

BO_ 2566844711 CCVS_VCU1: 8 VCU1
 SG_ ParkBrakeReleaseInhibitRq : 6|2@1+ (1,0) [0|3] "" Vector__XXX
 SG_ EngShutdownOverrideSwitch : 62|2@1+ (1,0) [0|3] "" Vector__XXX
 SG_ EngTestModeSwitch : 60|2@1+ (1,0) [0|3] "" Vector__XXX
 SG_ EngIdleDecrementSwitch : 58|2@1+ (1,0) [0|3] "" Vector__XXX
 SG_ EngIdleIncrementSwitch : 56|2@1+ (1,0) [0|3] "" Vector__XXX
 SG_ CruiseCtrlStates : 53|3@1+ (1,0) [0|7] "" Vector__XXX
 SG_ PTOState : 48|5@1+ (1,0) [0|31] "" Vector__XXX
 SG_ CruiseCtrlSetSpeed : 40|8@1+ (1,0) [0|250] "km/h" Vector__XXX
 SG_ CruiseCtrlAccelerateSwitch : 38|2@1+ (1,0) [0|3] "" Vector__XXX
 SG_ CruiseCtrlResumeSwitch : 36|2@1+ (1,0) [0|3] "" Vector__XXX
 SG_ CruiseCtrlCoastSwitch : 34|2@1+ (1,0) [0|3] "" Vector__XXX
 SG_ CruiseCtrlSetSwitch : 32|2@1+ (1,0) [0|3] "" Vector__XXX
 SG_ ClutchSwitch : 30|2@1+ (1,0) [0|3] "" Vector__XXX
 SG_ BrakeSwitch : 28|2@1+ (1,0) [0|3] "" Vector__XXX
 SG_ CruiseCtrlEnableSwitch : 26|2@1+ (1,0) [0|3] "" Vector__XXX
 SG_ CruiseCtrlActive : 24|2@1+ (1,0) [0|3] "" Vector__XXX
 SG_ WheelBasedVehicleSpeed : 8|16@1+ (0.00390625,0) [0|250.996] "km/h" Vector__XXX
 SG_ CruiseCtrlPauseSwitch : 4|2@1+ (1,0) [0|3] "" Vector__XXX
 SG_ ParkingBrakeSwitch : 2|2@1+ (1,0) [0|3] "" Vector__XXX
 SG_ TwoSpeedAxleSwitch : 0|2@1+ (1,0) [0|3] "" Vector__XXX

BO_ 2566844926 CCVS: 8 Vector__XXX
 SG_ ParkBrakeReleaseInhibitRq : 6|2@1+ (1,0) [0|3] "" Vector__XXX
 SG_ EngShutdownOverrideSwitch : 62|2@1+ (1,0) [0|3] "" Vector__XXX
 SG_ EngTestModeSwitch : 60|2@1+ (1,0) [0|3] "" Vector__XXX
 SG_ EngIdleDecrementSwitch : 58|2@1+ (1,0) [0|3] "" Vector__XXX
 SG_ EngIdleIncrementSwitch : 56|2@1+ (1,0) [0|3] "" Vector__XXX
 SG_ CruiseCtrlStates : 53|3@1+ (1,0) [0|7] "" Vector__XXX
 SG_ PTOState : 48|5@1+ (1,0) [0|31] "" Vector__XXX
 SG_ CruiseCtrlSetSpeed : 40|8@1+ (1,0) [0|250] "km/h" Vector__XXX
 SG_ CruiseCtrlAccelerateSwitch : 38|2@1+ (1,0) [0|3] "" Vector__XXX
 SG_ CruiseCtrlResumeSwitch : 36|2@1+ (1,0) [0|3] "" Vector__XXX
 SG_ CruiseCtrlCoastSwitch : 34|2@1+ (1,0) [0|3] "" Vector__XXX
 SG_ CruiseCtrlSetSwitch : 32|2@1+ (1,0) [0|3] "" Vector__XXX
 SG_ ClutchSwitch : 30|2@1+ (1,0) [0|3] "" Vector__XXX
 SG_ BrakeSwitch : 28|2@1+ (1,0) [0|3] "" Vector__XXX
 SG_ CruiseCtrlEnableSwitch : 26|2@1+ (1,0) [0|3] "" Vector__XXX
 SG_ CruiseCtrlActive : 24|2@1+ (1,0) [0|3] "" Vector__XXX
 SG_ WheelBasedVehicleSpeed : 8|16@1+ (0.00390625,0) [0|250.996] "km/h" Vector__XXX
 SG_ CruiseCtrlPauseSwitch : 4|2@1+ (1,0) [0|3] "" Vector__XXX
 SG_ ParkingBrakeSwitch : 2|2@1+ (1,0) [0|3] "" Vector__XXX
 SG_ TwoSpeedAxleSwitch : 0|2@1+ (1,0) [0|3] "" Vector__XXX

BO_ 2566857470 VCVCCU_V2ICP_VehicleToBackend: 8 VFC
 SG_ VCVCCU_V2ICP_RequiredEnergyToPre : 32|16@1+ (1,0) [0|1000] "kWh" Vector__XXX
 SG_ VCVCCU_V2ICP_RequiredEnergyToCha : 16|16@1+ (1,0) [0|1000] "kWh" Vector__XXX
 SG_ VCVCCU_V2ICP_RequiredDurationToP : 8|8@1+ (1,0) [0|250] "min" Vector__XXX
 SG_ VCVCCU_V2ICP_RequiredDurati_0000 : 0|8@1+ (1,0) [0|250] "min" Vector__XXX

BO_ 2563788849 CL_EPH: 8 VFC
 SG_ Illumination : 0|8@1+ (0.4,0) [0|100] "%"  EPH

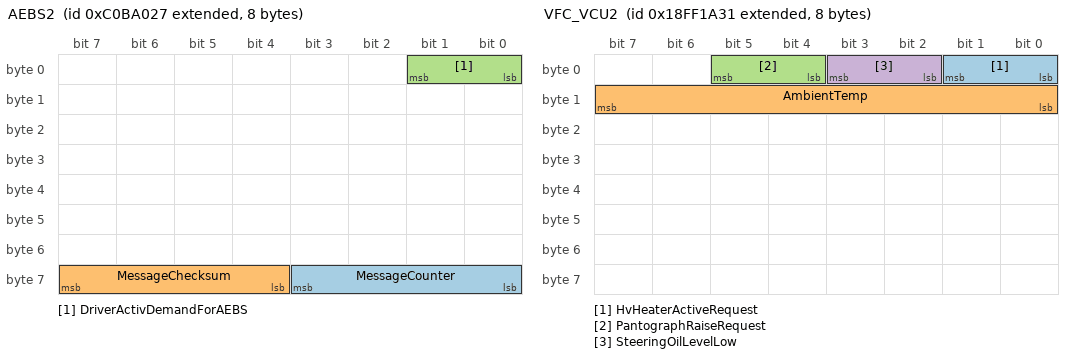
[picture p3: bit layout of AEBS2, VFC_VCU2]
BO_ 2349572135 AEBS2: 8 VFC
 SG_ MessageCounter : 56|4@1+ (1,0) [0|15] "" Vector__XXX
 SG_ MessageChecksum : 60|4@1+ (1,0) [0|15] "" Vector__XXX
 SG_ DriverActivDemandForAEBS : 0|2@1+ (1,0) [0|0] "" Vector__XXX

BO_ 2566855217 VFC_VCU2: 8 VFC
 SG_ HvHeaterActiveRequest : 0|2@1+ (1,0) [0|1] "" Vector__XXX
 SG_ AmbientTemp : 8|8@1+ (0.4,-40) [-40|215] "" Vector__XXX
 SG_ PantographRaiseRequest : 4|2@1+ (1,0) [0|1] "" Vector__XXX
 SG_ SteeringOilLevelLow : 2|2@1+ (1,0) [0|1] "" Vector__XXX

BO_ 2565475121 Req_EBC4: 8 VFC

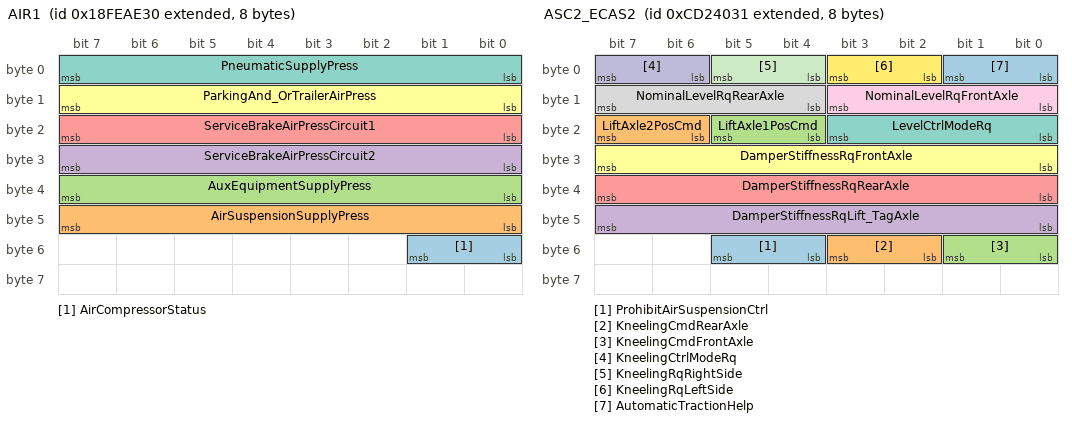
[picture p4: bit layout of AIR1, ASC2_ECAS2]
BO_ 2566827568 AIR1: 8 VFC
 SG_ AirCompressorStatus : 48|2@1+ (1,0) [0|3] "" Vector__XXX
 SG_ AirSuspensionSupplyPress : 40|8@1+ (8,0) [0|2000] "kPa" Vector__XXX
 SG_ AuxEquipmentSupplyPress : 32|8@1+ (8,0) [0|2000] "kPa" Vector__XXX
 SG_ ServiceBrakeAirPressCircuit2 : 24|8@1+ (8,0) [0|2000] "kPa" Vector__XXX
 SG_ ServiceBrakeAirPressCircuit1 : 16|8@1+ (8,0) [0|2000] "kPa" Vector__XXX
 SG_ ParkingAnd_OrTrailerAirPress : 8|8@1+ (8,0) [0|2000] "kPa" Vector__XXX
 SG_ PneumaticSupplyPress : 0|8@1+ (8,0) [0|2000] "kPa" Vector__XXX

BO_ 2362589233 ASC2_ECAS2: 8 VFC
 SG_ ProhibitAirSuspensionCtrl : 52|2@1+ (1,0) [0|3] ""  ECAS2
 SG_ KneelingCmdRearAxle : 50|2@1+ (1,0) [0|3] ""  ECAS2
 SG_ KneelingCmdFrontAxle : 48|2@1+ (1,0) [0|3] ""  ECAS2
 SG_ DamperStiffnessRqLift_TagAxle : 40|8@1+ (0.4,0) [0|100] "%"  ECAS2
 SG_ DamperStiffnessRqRearAxle : 32|8@1+ (0.4,0) [0|100] "%"  ECAS2
 SG_ DamperStiffnessRqFrontAxle : 24|8@1+ (0.4,0) [0|100] "%"  ECAS2
 SG_ LevelCtrlModeRq : 16|4@1+ (1,0) [0|15] ""  ECAS2
 SG_ NominalLevelRqRearAxle : 12|4@1+ (1,0) [0|15] ""  ECAS2
 SG_ NominalLevelRqFrontAxle : 8|4@1+ (1,0) [0|15] ""  ECAS2
 SG_ KneelingCtrlModeRq : 6|2@1+ (1,0) [0|3] ""  ECAS2
 SG_ KneelingRqRightSide : 4|2@1+ (1,0) [0|3] ""  ECAS2
 SG_ KneelingRqLeftSide : 2|2@1+ (1,0) [0|3] ""  ECAS2
 SG_ AutomaticTractionHelp : 0|2@1+ (1,0) [0|3] ""  ECAS2
 SG_ LiftAxle2PosCmd : 22|2@1+ (1,0) [0|3] ""  ECAS2
 SG_ LiftAxle1PosCmd : 20|2@1+ (1,0) [0|3] ""  ECAS2

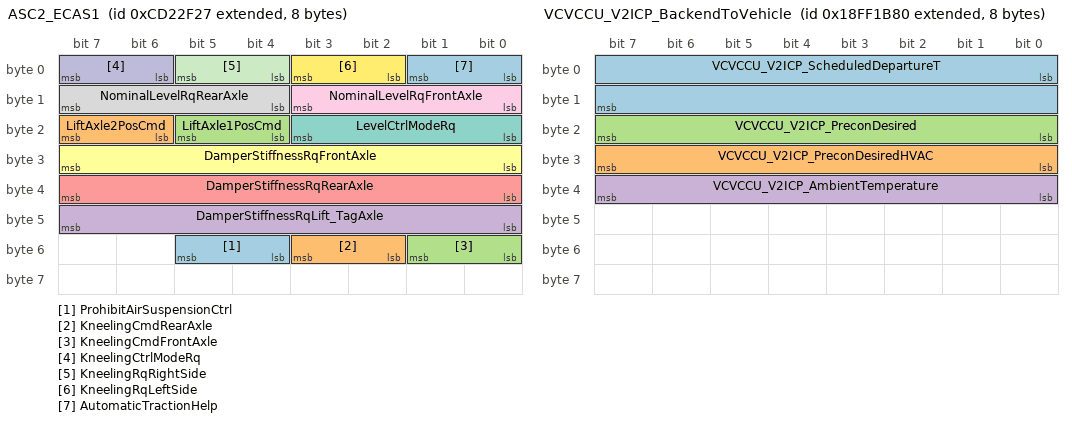
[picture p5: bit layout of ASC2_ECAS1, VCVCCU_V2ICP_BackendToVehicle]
BO_ 2362584871 ASC2_ECAS1: 8 VFC
 SG_ ProhibitAirSuspensionCtrl : 52|2@1+ (1,0) [0|3] ""  ECAS1
 SG_ KneelingCmdRearAxle : 50|2@1+ (1,0) [0|3] ""  ECAS1
 SG_ KneelingCmdFrontAxle : 48|2@1+ (1,0) [0|3] ""  ECAS1
 SG_ DamperStiffnessRqLift_TagAxle : 40|8@1+ (0.4,0) [0|100] "%"  ECAS1
 SG_ DamperStiffnessRqRearAxle : 32|8@1+ (0.4,0) [0|100] "%"  ECAS1
 SG_ DamperStiffnessRqFrontAxle : 24|8@1+ (0.4,0) [0|100] "%"  ECAS1
 SG_ LevelCtrlModeRq : 16|4@1+ (1,0) [0|15] ""  ECAS1
 SG_ NominalLevelRqRearAxle : 12|4@1+ (1,0) [0|15] ""  ECAS1
 SG_ NominalLevelRqFrontAxle : 8|4@1+ (1,0) [0|15] ""  ECAS1
 SG_ KneelingCtrlModeRq : 6|2@1+ (1,0) [0|3] ""  ECAS1
 SG_ KneelingRqRightSide : 4|2@1+ (1,0) [0|3] ""  ECAS1
 SG_ KneelingRqLeftSide : 2|2@1+ (1,0) [0|3] ""  ECAS1
 SG_ AutomaticTractionHelp : 0|2@1+ (1,0) [0|3] ""  ECAS1
 SG_ LiftAxle2PosCmd : 22|2@1+ (1,0) [0|3] ""  ECAS1
 SG_ LiftAxle1PosCmd : 20|2@1+ (1,0) [0|3] ""  ECAS1

BO_ 2566854961 VFC_VCU1: 8 VFC
 SG_ TractionHelpRequest : 42|2@1+ (1,0) [0|0] "" Vector__XXX
 SG_ AVBS_LIN_SwitchState : 44|2@1+ (1,0) [0|0] "" Vector__XXX
 SG_ CityModeSPeedLimit : 40|2@1+ (1,0) [0|0] "" Vector__XXX
 SG_ ParkBrakeRequest : 36|2@1+ (1,0) [0|0] "" Vector__XXX
 SG_ ParkBrakeInhibitRequest : 38|2@1+ (1,0) [0|0] "" Vector__XXX
 SG_ HaltBrakeOverruleRequest : 34|2@1+ (1,0) [0|0] "" Vector__XXX
 SG_ ArticulateEmergencyReleaseReq : 32|2@1+ (1,0) [0|0] "" Vector__XXX
 SG_ DriverLowVoltageOverrule : 22|2@1+ (1,0) [0|0] "" Vector__XXX
 SG_ WakeUpVFCDoor2Button : 1|1@1+ (1,0) [0|0] "" Vector__XXX
 SG_ WakeUpVFCPreHeaterClock : 9|1@1+ (1,0) [0|0] "" Vector__XXX
 SG_ WakeUpVFCCleaningButton : 2|1@1+ (1,0) [0|0] "" Vector__XXX
 SG_ WakeUpVFCDoor1Button : 0|1@1+ (1,0) [0|0] "" Vector__XXX
 SG_ CreepingDisableRequest : 30|2@1+ (1,0) [0|0] "" Vector__XXX
 SG_ VehicleMotionInhibit : 28|2@1+ (1,0) [0|0] "" Vector__XXX
 SG_ DriveLineDisengageReq : 26|2@1+ (1,0) [0|0] "" Vector__XXX
 SG_ ECASSpeedLimiterReq : 24|2@1+ (1,0) [0|0] "" Vector__XXX
 SG_ StartInhibitRequest : 20|2@1+ (1,0) [0|0] "" Vector__XXX
 SG_ StopStartActive : 18|2@1+ (1,0) [0|0] "" Vector__XXX
 SG_ PowerHoldVFC : 16|2@1+ (1,0) [0|0] "" Vector__XXX

BO_ 2566855552 VCVCCU_V2ICP_BackendToVehicle: 8 EVCC
 SG_ VCVCCU_V2ICP_ScheduledDepartureT : 0|16@1+ (5,0) [0|1440] "min" Vector__XXX
 SG_ VCVCCU_V2ICP_PreconDesiredHVAC : 24|8@1+ (1,0) [0|3] "" Vector__XXX
 SG_ VCVCCU_V2ICP_PreconDesired : 16|8@1+ (1,0) [0|255] "" Vector__XXX
 SG_ VCVCCU_V2ICP_AmbientTemperature : 32|8@1- (1,0) [-50|70] "°C" Vector__XXX

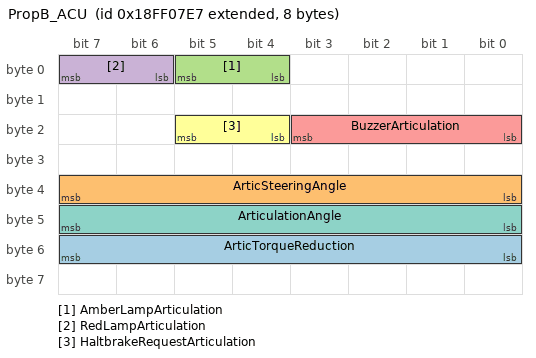
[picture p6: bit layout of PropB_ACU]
BO_ 2566850535 PropB_ACU: 8 ACU
 SG_ ArticTorqueReduction : 48|8@1+ (0.4,0) [0|100] "%" Vector__XXX
 SG_ ArticSteeringAngle : 32|8@1+ (0.5,-62.5) [-62.5|62.5] "Deg" Vector__XXX
 SG_ AmberLampArticulation : 4|2@1+ (1,0) [0|0] "" Vector__XXX
 SG_ RedLampArticulation : 6|2@1+ (1,0) [0|0] "" Vector__XXX
 SG_ BuzzerArticulation : 16|4@1+ (1,0) [0|0] "" Vector__XXX
 SG_ HaltbrakeRequestArticulation : 20|2@1+ (1,0) [0|0] "" Vector__XXX
 SG_ ArticulationAngle : 40|8@1+ (0.5,-62.5) [-62.5|62.5] "Deg" Vector__XXX

BO_ 2365479488 ASC1_ECAS2: 8 ECAS2
 SG_ SspensionCtrlRefusalInformation : 56|4@1+ (1,0) [0|15] "" Vector__XXX
 SG_ SuspensionRemoteCtrl2 : 50|2@1+ (1,0) [0|3] "" Vector__XXX
 SG_ SuspensionRemoteCtrl1 : 48|2@1+ (1,0) [0|3] "" Vector__XXX
 SG_ RearAxleInBumperRange : 42|2@1+ (1,0) [0|3] "" Vector__XXX
 SG_ FrontAxleInBumperRange : 40|2@1+ (1,0) [0|3] "" Vector__XXX
 SG_ DoorRelease : 36|2@1+ (1,0) [0|3] "" Vector__XXX
 SG_ VehicleMotionInhibit : 34|2@1+ (1,0) [0|3] "" Vector__XXX
 SG_ SecurityDevice : 32|2@1+ (1,0) [0|3] "" Vector__XXX
 SG_ LevelCtrlMode : 28|4@1+ (1,0) [0|15] "" Vector__XXX
 SG_ KneelingInformation : 24|4@1+ (1,0) [0|15] "" Vector__XXX
 SG_ LiftingCtrlModeRearAxle : 22|2@1+ (1,0) [0|3] "" Vector__XXX
 SG_ LiftingCtrlModeFrontAxle : 20|2@1+ (1,0) [0|3] "" Vector__XXX
 SG_ LoweringCtrlModeRearAxle : 18|2@1+ (1,0) [0|3] "" Vector__XXX
 SG_ LoweringCtrlModeFrontAxle : 16|2@1+ (1,0) [0|3] "" Vector__XXX
 SG_ AboveNominalLevelRearAxle : 14|2@1+ (1,0) [0|3] "" Vector__XXX
 SG_ AboveNominalLevelFrontAxle : 12|2@1+ (1,0) [0|3] "" Vector__XXX
 SG_ BelowNominalLevelRearAxle : 10|2@1+ (1,0) [0|3] "" Vector__XXX
 SG_ BelowNominalLevelFrontAxle : 8|2@1+ (1,0) [0|3] "" Vector__XXX
 SG_ NominalLevelRearAxle : 4|4@1+ (1,0) [0|15] "" Vector__XXX
 SG_ NominalLevelFrontAxle : 0|4@1+ (1,0) [0|15] "" Vector__XXX
 SG_ LiftAxle2Pos : 46|2@1+ (1,0) [0|3] "" Vector__XXX
 SG_ LiftAxle1Pos : 38|2@1+ (1,0) [0|3] "" Vector__XXX

BO_ 2565865967 EBC1_DCU: 8 DCU
 SG_ SrcAddrssOfCtrllngDvcFrBrkCntrl : 48|8@1+ (1,0) [0|255] "" Vector__XXX
 SG_ BrakePedalPos : 8|8@1+ (0.4,0) [0|100] "%" Vector__XXX
 SG_ TrctrMntdTrilerABSWarningSignal : 62|2@1+ (1,0) [0|3] "" Vector__XXX
 SG_ TrailerABSStatus : 60|2@1+ (1,0) [0|3] "" Vector__XXX
 SG_ HaltBrakeSwitch : 58|2@1+ (1,0) [0|3] "" Vector__XXX
 SG_ ATC_ASRInformationSignal : 46|2@1+ (1,0) [0|3] "" Vector__XXX
 SG_ ABS_EBSAmberWarningSignal : 44|2@1+ (1,0) [0|3] "" Vector__XXX
 SG_ EBSRedWarningSignal : 42|2@1+ (1,0) [0|3] "" Vector__XXX
 SG_ ABSFullyOperational : 40|2@1+ (1,0) [0|3] "" Vector__XXX
 SG_ EngRetarderSelection : 32|8@1+ (0.4,0) [0|100] "%" Vector__XXX
 SG_ RemoteAccelEnableSwitch : 30|2@1+ (1,0) [0|3] "" Vector__XXX
 SG_ EngAuxEngShutdownSwitch : 28|2@1+ (1,0) [0|3] "" Vector__XXX
 SG_ EngDerateSwitch : 26|2@1+ (1,0) [0|3] "" Vector__XXX
 SG_ AccelInterlockSwitch : 24|2@1+ (1,0) [0|3] "" Vector__XXX
 SG_ TractionCtrlOverrideSwitch : 22|2@1+ (1,0) [0|3] "" Vector__XXX
 SG_ ASRHillHolderSwitch : 20|2@1+ (1,0) [0|3] "" Vector__XXX
 SG_ ASROffroadSwitch : 18|2@1+ (1,0) [0|3] "" Vector__XXX
 SG_ ABSOffroadSwitch : 16|2@1+ (1,0) [0|3] "" Vector__XXX
 SG_ EBSBrakeSwitch : 6|2@1+ (1,0) [0|3] "" Vector__XXX
 SG_ AntiLockBrakingActive : 4|2@1+ (1,0) [0|3] "" Vector__XXX
 SG_ ASRBrakeCtrlActive : 2|2@1+ (1,0) [0|3] "" Vector__XXX
 SG_ ASREngCtrlActive : 0|2@1+ (1,0) [0|3] "" Vector__XXX

BO_ 2566874442 PropB_CCU_Req: 8 CCU
 SG_ GeofenceZeroEmission : 1|1@1+ (1,0) [0|0] "" Vector__XXX

CM_ BO_ 2147548812 "Active diagnostic trouble codes";
CM_ SG_ 2147548812 FailureModeIdentifier5 "The FMI defines the type of failure detected in the subsystem identified by an SPN.";
CM_ SG_ 2147548812 FailureModeIdentifier4 "The FMI defines the type of failure detected in the subsystem identified by an SPN.";
CM_ SG_ 2147548812 FailureModeIdentifier3 "The FMI defines the type of failure detected in the subsystem identified by an SPN.";
CM_ SG_ 2147548812 FailureModeIdentifier2 "The FMI defines the type of failure detected in the subsystem identified by an SPN.";
CM_ SG_ 2147548812 OccurenceCount5 "The 7 bit occurence count field contains the number of times a fault has gone from active to previously active.";
CM_ SG_ 2147548812 OccurenceCount4 "The 7 bit occurence count field contains the number of times a fault has gone from active to previously active.";
CM_ SG_ 2147548812 OccurenceCount3 "The 7 bit occurence count field contains the number of times a fault has gone from active to previously active.";
CM_ SG_ 2147548812 OccurenceCount2 "The 7 bit occurence count field contains the number of times a fault has gone from active to previously active.";
CM_ SG_ 2147548812 SPN5High "SPN #5 (Conversion Version 4)";
CM_ SG_ 2147548812 SPN5 "SPN #5 (Conversion Version 4)";
CM_ SG_ 2147548812 SPN4High "SPN #4 (Conversion Version 4)";
CM_ SG_ 2147548812 SPN4 "SPN #4 (Conversion Version 4)";
CM_ SG_ 2147548812 SPN3High "SPN #3 (Conversion Version 4)";
CM_ SG_ 2147548812 SPN3 "SPN #3 (Conversion Version 4)";
CM_ SG_ 2147548812 SPN2High "SPN #2 (Conversion Version 4)";
CM_ SG_ 2147548812 SPN2 "SPN #2 (Conversion Version 4)";
CM_ SG_ 2147548812 SPN1 "SPN #1 (Conversion Version 4)";
CM_ SG_ 2147548812 OccurenceCount1 "The 7 bit occurence count field contains the number of times a fault has gone from active to previously active.";
CM_ SG_ 2147548812 SPN1High "SPN #1 (Conversion Version 4)";
CM_ SG_ 2147548812 FailureModeIdentifier1 "The FMI defines the type of failure detected in the subsystem identified by an SPN.";
CM_ SG_ 2147548812 FlashMalfuncIndicatorLamp "This parameter provides the capability to flash the MIL (SPN 3038).";
CM_ SG_ 2147548812 FlashRedStopLamp "This parameter provides the capability to flash the RSL (SPN 3039).";
CM_ SG_ 2147548812 FlashAmberWarningLamp "This parameter provides the capability to flash the AWL (SPN 3040). ";
CM_ SG_ 2147548812 FlashProtectLamp "This parameter provides the capability to flash the engine protect lamp (SPN 3041).";
CM_ SG_ 2147548812 MalfunctionIndicatorLampStatus "A lamp used to relay only emissions-related trouble code information.";
CM_ SG_ 2147548812 RedStopLampState "This lamp is uesed to relay trouble code information that is of a severe enought condition that it warrants stopping the vehicle.";
CM_ SG_ 2147548812 AmberWarningLampStatus "This lamp is used to relay trouble code information that is reporting a problem with the vehicle system but the vehicle need
not be immediately stopped.";
CM_ SG_ 2147548812 ProtectLampStatus "This lamp is used to relay trouble code informatio that is reporting a problem with a vehicle system that is most
probably not electronic subsystem related.";
CM_ BO_ 2566834829 "Active diagnostic trouble codes";
CM_ SG_ 2566834829 FailureModeIdentifier5 "The FMI defines the type of failure detected in the subsystem identified by an SPN.";
CM_ SG_ 2566834829 FailureModeIdentifier4 "The FMI defines the type of failure detected in the subsystem identified by an SPN.";
CM_ SG_ 2566834829 FailureModeIdentifier3 "The FMI defines the type of failure detected in the subsystem identified by an SPN.";
CM_ SG_ 2566834829 FailureModeIdentifier2 "The FMI defines the type of failure detected in the subsystem identified by an SPN.";
CM_ SG_ 2566834829 OccurenceCount5 "The 7 bit occurence count field contains the number of times a fault has gone from active to previously active.";
CM_ SG_ 2566834829 OccurenceCount4 "The 7 bit occurence count field contains the number of times a fault has gone from active to previously active.";
CM_ SG_ 2566834829 OccurenceCount3 "The 7 bit occurence count field contains the number of times a fault has gone from active to previously active.";
CM_ SG_ 2566834829 OccurenceCount2 "The 7 bit occurence count field contains the number of times a fault has gone from active to previously active.";
CM_ SG_ 2566834829 SPN5High "SPN #5 (Conversion Version 4)";
CM_ SG_ 2566834829 SPN5 "SPN #5 (Conversion Version 4)";
CM_ SG_ 2566834829 SPN4High "SPN #4 (Conversion Version 4)";
CM_ SG_ 2566834829 SPN4 "SPN #4 (Conversion Version 4)";
CM_ SG_ 2566834829 SPN3High "SPN #3 (Conversion Version 4)";
CM_ SG_ 2566834829 SPN3 "SPN #3 (Conversion Version 4)";
CM_ SG_ 2566834829 SPN2High "SPN #2 (Conversion Version 4)";
CM_ SG_ 2566834829 SPN2 "SPN #2 (Conversion Version 4)";
CM_ SG_ 2566834829 SPN1 "SPN #1 (Conversion Version 4)";
CM_ SG_ 2566834829 OccurenceCount1 "The 7 bit occurence count field contains the number of times a fault has gone from active to previously active.";
CM_ SG_ 2566834829 SPN1High "SPN #1 (Conversion Version 4)";
CM_ SG_ 2566834829 FailureModeIdentifier1 "The FMI defines the type of failure detected in the subsystem identified by an SPN.";
CM_ SG_ 2566834829 FlashMalfuncIndicatorLamp "This parameter provides the capability to flash the MIL (SPN 3038).";
CM_ SG_ 2566834829 FlashRedStopLamp "This parameter provides the capability to flash the RSL (SPN 3039).";
CM_ SG_ 2566834829 FlashAmberWarningLamp "This parameter provides the capability to flash the AWL (SPN 3040). ";
CM_ SG_ 2566834829 FlashProtectLamp "This parameter provides the capability to flash the engine protect lamp (SPN 3041).";
CM_ SG_ 2566834829 MalfunctionIndicatorLampStatus "A lamp used to relay only emissions-related trouble code information.";
CM_ SG_ 2566834829 RedStopLampState "This lamp is uesed to relay trouble code information that is of a severe enought condition that it warrants stopping the vehicle.";
CM_ SG_ 2566834829 AmberWarningLampStatus "This lamp is used to relay trouble code information that is reporting a problem with the vehicle system but the vehicle need
not be immediately stopped.";
CM_ SG_ 2566834829 ProtectLampStatus "This lamp is used to relay trouble code informatio that is reporting a problem with a vehicle system that is most
probably not electronic subsystem related.";
CM_ BO_ 2147483648 "Active diagnostic trouble codes";
CM_ SG_ 2147483648 FailureModeIdentifier5 "The FMI defines the type of failure detected in the subsystem identified by an SPN.";
CM_ SG_ 2147483648 FailureModeIdentifier4 "The FMI defines the type of failure detected in the subsystem identified by an SPN.";
CM_ SG_ 2147483648 FailureModeIdentifier3 "The FMI defines the type of failure detected in the subsystem identified by an SPN.";
CM_ SG_ 2147483648 FailureModeIdentifier2 "The FMI defines the type of failure detected in the subsystem identified by an SPN.";
CM_ SG_ 2147483648 OccurenceCount5 "The 7 bit occurence count field contains the number of times a fault has gone from active to previously active.";
CM_ SG_ 2147483648 OccurenceCount4 "The 7 bit occurence count field contains the number of times a fault has gone from active to previously active.";
CM_ SG_ 2147483648 OccurenceCount3 "The 7 bit occurence count field contains the number of times a fault has gone from active to previously active.";
CM_ SG_ 2147483648 OccurenceCount2 "The 7 bit occurence count field contains the number of times a fault has gone from active to previously active.";
CM_ SG_ 2147483648 SPN5High "SPN #5 (Conversion Version 4)";
CM_ SG_ 2147483648 SPN5 "SPN #5 (Conversion Version 4)";
CM_ SG_ 2147483648 SPN4High "SPN #4 (Conversion Version 4)";
CM_ SG_ 2147483648 SPN4 "SPN #4 (Conversion Version 4)";
CM_ SG_ 2147483648 SPN3High "SPN #3 (Conversion Version 4)";
CM_ SG_ 2147483648 SPN3 "SPN #3 (Conversion Version 4)";
CM_ SG_ 2147483648 SPN2High "SPN #2 (Conversion Version 4)";
CM_ SG_ 2147483648 SPN2 "SPN #2 (Conversion Version 4)";
CM_ SG_ 2147483648 SPN1 "SPN #1 (Conversion Version 4)";
CM_ SG_ 2147483648 OccurenceCount1 "The 7 bit occurence count field contains the number of times a fault has gone from active to previously active.";
CM_ SG_ 2147483648 SPN1High "SPN #1 (Conversion Version 4)";
CM_ SG_ 2147483648 FailureModeIdentifier1 "The FMI defines the type of failure detected in the subsystem identified by an SPN.";
CM_ SG_ 2147483648 FlashMalfuncIndicatorLamp "This parameter provides the capability to flash the MIL (SPN 3038).";
CM_ SG_ 2147483648 FlashRedStopLamp "This parameter provides the capability to flash the RSL (SPN 3039).";
CM_ SG_ 2147483648 FlashAmberWarningLamp "This parameter provides the capability to flash the AWL (SPN 3040). ";
CM_ SG_ 2147483648 FlashProtectLamp "This parameter provides the capability to flash the engine protect lamp (SPN 3041).";
CM_ SG_ 2147483648 MalfunctionIndicatorLampStatus "A lamp used to relay only emissions-related trouble code information.";
CM_ SG_ 2147483648 RedStopLampState "This lamp is uesed to relay trouble code information that is of a severe enought condition that it warrants stopping the vehicle.";
CM_ SG_ 2147483648 AmberWarningLampStatus "This lamp is used to relay trouble code information that is reporting a problem with the vehicle system but the vehicle need
not be immediately stopped.";
CM_ SG_ 2147483648 ProtectLampStatus "This lamp is used to relay trouble code informatio that is reporting a problem with a vehicle system that is most
probably not electronic subsystem related.";
CM_ BO_ 2566834827 "Active diagnostic trouble codes";
CM_ SG_ 2566834827 FailureModeIdentifier5 "The FMI defines the type of failure detected in the subsystem identified by an SPN.";
CM_ SG_ 2566834827 FailureModeIdentifier4 "The FMI defines the type of failure detected in the subsystem identified by an SPN.";
CM_ SG_ 2566834827 FailureModeIdentifier3 "The FMI defines the type of failure detected in the subsystem identified by an SPN.";
CM_ SG_ 2566834827 FailureModeIdentifier2 "The FMI defines the type of failure detected in the subsystem identified by an SPN.";
CM_ SG_ 2566834827 OccurenceCount5 "The 7 bit occurence count field contains the number of times a fault has gone from active to previously active.";
CM_ SG_ 2566834827 OccurenceCount4 "The 7 bit occurence count field contains the number of times a fault has gone from active to previously active.";
CM_ SG_ 2566834827 OccurenceCount3 "The 7 bit occurence count field contains the number of times a fault has gone from active to previously active.";
CM_ SG_ 2566834827 OccurenceCount2 "The 7 bit occurence count field contains the number of times a fault has gone from active to previously active.";
CM_ SG_ 2566834827 SPN5High "SPN #5 (Conversion Version 4)";
CM_ SG_ 2566834827 SPN5 "SPN #5 (Conversion Version 4)";
CM_ SG_ 2566834827 SPN4High "SPN #4 (Conversion Version 4)";
CM_ SG_ 2566834827 SPN4 "SPN #4 (Conversion Version 4)";
CM_ SG_ 2566834827 SPN3High "SPN #3 (Conversion Version 4)";
CM_ SG_ 2566834827 SPN3 "SPN #3 (Conversion Version 4)";
CM_ SG_ 2566834827 SPN2High "SPN #2 (Conversion Version 4)";
CM_ SG_ 2566834827 SPN2 "SPN #2 (Conversion Version 4)";
CM_ SG_ 2566834827 SPN1 "SPN #1 (Conversion Version 4)";
CM_ SG_ 2566834827 OccurenceCount1 "The 7 bit occurence count field contains the number of times a fault has gone from active to previously active.";
CM_ SG_ 2566834827 SPN1High "SPN #1 (Conversion Version 4)";
CM_ SG_ 2566834827 FailureModeIdentifier1 "The FMI defines the type of failure detected in the subsystem identified by an SPN.";
CM_ SG_ 2566834827 FlashMalfuncIndicatorLamp "This parameter provides the capability to flash the MIL (SPN 3038).";
CM_ SG_ 2566834827 FlashRedStopLamp "This parameter provides the capability to flash the RSL (SPN 3039).";
CM_ SG_ 2566834827 FlashAmberWarningLamp "This parameter provides the capability to flash the AWL (SPN 3040). ";
CM_ SG_ 2566834827 FlashProtectLamp "This parameter provides the capability to flash the engine protect lamp (SPN 3041).";
CM_ SG_ 2566834827 MalfunctionIndicatorLampStatus "A lamp used to relay only emissions-related trouble code information.";
CM_ SG_ 2566834827 RedStopLampState "This lamp is uesed to relay trouble code information that is of a severe enought condition that it warrants stopping the vehicle.";
CM_ SG_ 2566834827 AmberWarningLampStatus "This lamp is used to relay trouble code information that is reporting a problem with the vehicle system but the vehicle need
not be immediately stopped.";
CM_ SG_ 2566834827 ProtectLampStatus "This lamp is used to relay trouble code informatio that is reporting a problem with a vehicle system that is most
probably not electronic subsystem related.";
CM_ BO_ 2566834826 "Active diagnostic trouble codes";
CM_ SG_ 2566834826 FailureModeIdentifier5 "The FMI defines the type of failure detected in the subsystem identified by an SPN.";
CM_ SG_ 2566834826 FailureModeIdentifier4 "The FMI defines the type of failure detected in the subsystem identified by an SPN.";
CM_ SG_ 2566834826 FailureModeIdentifier3 "The FMI defines the type of failure detected in the subsystem identified by an SPN.";
CM_ SG_ 2566834826 FailureModeIdentifier2 "The FMI defines the type of failure detected in the subsystem identified by an SPN.";
CM_ SG_ 2566834826 OccurenceCount5 "The 7 bit occurence count field contains the number of times a fault has gone from active to previously active.";
CM_ SG_ 2566834826 OccurenceCount4 "The 7 bit occurence count field contains the number of times a fault has gone from active to previously active.";
CM_ SG_ 2566834826 OccurenceCount3 "The 7 bit occurence count field contains the number of times a fault has gone from active to previously active.";
CM_ SG_ 2566834826 OccurenceCount2 "The 7 bit occurence count field contains the number of times a fault has gone from active to previously active.";
CM_ SG_ 2566834826 SPN5High "SPN #5 (Conversion Version 4)";
CM_ SG_ 2566834826 SPN5 "SPN #5 (Conversion Version 4)";
CM_ SG_ 2566834826 SPN4High "SPN #4 (Conversion Version 4)";
CM_ SG_ 2566834826 SPN4 "SPN #4 (Conversion Version 4)";
CM_ SG_ 2566834826 SPN3High "SPN #3 (Conversion Version 4)";
CM_ SG_ 2566834826 SPN3 "SPN #3 (Conversion Version 4)";
CM_ SG_ 2566834826 SPN2High "SPN #2 (Conversion Version 4)";
CM_ SG_ 2566834826 SPN2 "SPN #2 (Conversion Version 4)";
CM_ SG_ 2566834826 SPN1 "SPN #1 (Conversion Version 4)";
CM_ SG_ 2566834826 OccurenceCount1 "The 7 bit occurence count field contains the number of times a fault has gone from active to previously active.";
CM_ SG_ 2566834826 SPN1High "SPN #1 (Conversion Version 4)";
CM_ SG_ 2566834826 FailureModeIdentifier1 "The FMI defines the type of failure detected in the subsystem identified by an SPN.";
CM_ SG_ 2566834826 FlashMalfuncIndicatorLamp "This parameter provides the capability to flash the MIL (SPN 3038).";
CM_ SG_ 2566834826 FlashRedStopLamp "This parameter provides the capability to flash the RSL (SPN 3039).";
CM_ SG_ 2566834826 FlashAmberWarningLamp "This parameter provides the capability to flash the AWL (SPN 3040). ";
CM_ SG_ 2566834826 FlashProtectLamp "This parameter provides the capability to flash the engine protect lamp (SPN 3041).";
CM_ SG_ 2566834826 MalfunctionIndicatorLampStatus "A lamp used to relay only emissions-related trouble code information.";
CM_ SG_ 2566834826 RedStopLampState "This lamp is uesed to relay trouble code information that is of a severe enought condition that it warrants stopping the vehicle.";
CM_ SG_ 2566834826 AmberWarningLampStatus "This lamp is used to relay trouble code information that is reporting a problem with the vehicle system but the vehicle need
not be immediately stopped.";
CM_ SG_ 2566834826 ProtectLampStatus "This lamp is used to relay trouble code informatio that is reporting a problem with a vehicle system that is most
probably not electronic subsystem related.";
CM_ BO_ 2566834920 "Active diagnostic trouble codes";
CM_ SG_ 2566834920 FailureModeIdentifier5 "The FMI defines the type of failure detected in the subsystem identified by an SPN.";
CM_ SG_ 2566834920 FailureModeIdentifier4 "The FMI defines the type of failure detected in the subsystem identified by an SPN.";
CM_ SG_ 2566834920 FailureModeIdentifier3 "The FMI defines the type of failure detected in the subsystem identified by an SPN.";
CM_ SG_ 2566834920 FailureModeIdentifier2 "The FMI defines the type of failure detected in the subsystem identified by an SPN.";
CM_ SG_ 2566834920 OccurenceCount5 "The 7 bit occurence count field contains the number of times a fault has gone from active to previously active.";
CM_ SG_ 2566834920 OccurenceCount4 "The 7 bit occurence count field contains the number of times a fault has gone from active to previously active.";
CM_ SG_ 2566834920 OccurenceCount3 "The 7 bit occurence count field contains the number of times a fault has gone from active to previously active.";
CM_ SG_ 2566834920 OccurenceCount2 "The 7 bit occurence count field contains the number of times a fault has gone from active to previously active.";
CM_ SG_ 2566834920 SPN5High "SPN #5 (Conversion Version 4)";
CM_ SG_ 2566834920 SPN5 "SPN #5 (Conversion Version 4)";
CM_ SG_ 2566834920 SPN4High "SPN #4 (Conversion Version 4)";
CM_ SG_ 2566834920 SPN4 "SPN #4 (Conversion Version 4)";
CM_ SG_ 2566834920 SPN3High "SPN #3 (Conversion Version 4)";
CM_ SG_ 2566834920 SPN3 "SPN #3 (Conversion Version 4)";
CM_ SG_ 2566834920 SPN2High "SPN #2 (Conversion Version 4)";
CM_ SG_ 2566834920 SPN2 "SPN #2 (Conversion Version 4)";
CM_ SG_ 2566834920 SPN1 "SPN #1 (Conversion Version 4)";
CM_ SG_ 2566834920 OccurenceCount1 "The 7 bit occurence count field contains the number of times a fault has gone from active to previously active.";
CM_ SG_ 2566834920 SPN1High "SPN #1 (Conversion Version 4)";
CM_ SG_ 2566834920 FailureModeIdentifier1 "The FMI defines the type of failure detected in the subsystem identified by an SPN.";
CM_ SG_ 2566834920 FlashMalfuncIndicatorLamp "This parameter provides the capability to flash the MIL (SPN 3038).";
CM_ SG_ 2566834920 FlashRedStopLamp "This parameter provides the capability to flash the RSL (SPN 3039).";
CM_ SG_ 2566834920 FlashAmberWarningLamp "This parameter provides the capability to flash the AWL (SPN 3040). ";
CM_ SG_ 2566834920 FlashProtectLamp "This parameter provides the capability to flash the engine protect lamp (SPN 3041).";
CM_ SG_ 2566834920 MalfunctionIndicatorLampStatus "A lamp used to relay only emissions-related trouble code information.";
CM_ SG_ 2566834920 RedStopLampState "This lamp is uesed to relay trouble code information that is of a severe enought condition that it warrants stopping the vehicle.";
CM_ SG_ 2566834920 AmberWarningLampStatus "This lamp is used to relay trouble code information that is reporting a problem with the vehicle system but the vehicle need
not be immediately stopped.";
CM_ SG_ 2566834920 ProtectLampStatus "This lamp is used to relay trouble code informatio that is reporting a problem with a vehicle system that is most
probably not electronic subsystem related.";
CM_ BO_ 2566834752 "Active diagnostic trouble codes";
CM_ SG_ 2566834752 FailureModeIdentifier5 "The FMI defines the type of failure detected in the subsystem identified by an SPN.";
CM_ SG_ 2566834752 FailureModeIdentifier4 "The FMI defines the type of failure detected in the subsystem identified by an SPN.";
CM_ SG_ 2566834752 FailureModeIdentifier3 "The FMI defines the type of failure detected in the subsystem identified by an SPN.";
CM_ SG_ 2566834752 FailureModeIdentifier2 "The FMI defines the type of failure detected in the subsystem identified by an SPN.";
CM_ SG_ 2566834752 OccurenceCount5 "The 7 bit occurence count field contains the number of times a fault has gone from active to previously active.";
CM_ SG_ 2566834752 OccurenceCount4 "The 7 bit occurence count field contains the number of times a fault has gone from active to previously active.";
CM_ SG_ 2566834752 OccurenceCount3 "The 7 bit occurence count field contains the number of times a fault has gone from active to previously active.";
CM_ SG_ 2566834752 OccurenceCount2 "The 7 bit occurence count field contains the number of times a fault has gone from active to previously active.";
CM_ SG_ 2566834752 SPN5High "SPN #5 (Conversion Version 4)";
CM_ SG_ 2566834752 SPN5 "SPN #5 (Conversion Version 4)";
CM_ SG_ 2566834752 SPN4High "SPN #4 (Conversion Version 4)";
CM_ SG_ 2566834752 SPN4 "SPN #4 (Conversion Version 4)";
CM_ SG_ 2566834752 SPN3High "SPN #3 (Conversion Version 4)";
CM_ SG_ 2566834752 SPN3 "SPN #3 (Conversion Version 4)";
CM_ SG_ 2566834752 SPN2High "SPN #2 (Conversion Version 4)";
CM_ SG_ 2566834752 SPN2 "SPN #2 (Conversion Version 4)";
CM_ SG_ 2566834752 SPN1 "SPN #1 (Conversion Version 4)";
CM_ SG_ 2566834752 OccurenceCount1 "The 7 bit occurence count field contains the number of times a fault has gone from active to previously active.";
CM_ SG_ 2566834752 SPN1High "SPN #1 (Conversion Version 4)";
CM_ SG_ 2566834752 FailureModeIdentifier1 "The FMI defines the type of failure detected in the subsystem identified by an SPN.";
CM_ SG_ 2566834752 FlashMalfuncIndicatorLamp "This parameter provides the capability to flash the MIL (SPN 3038).";
CM_ SG_ 2566834752 FlashRedStopLamp "This parameter provides the capability to flash the RSL (SPN 3039).";
CM_ SG_ 2566834752 FlashAmberWarningLamp "This parameter provides the capability to flash the AWL (SPN 3040). ";
CM_ SG_ 2566834752 FlashProtectLamp "This parameter provides the capability to flash the engine protect lamp (SPN 3041).";
CM_ SG_ 2566834752 MalfunctionIndicatorLampStatus "A lamp used to relay only emissions-related trouble code information.";
CM_ SG_ 2566834752 RedStopLampState "This lamp is uesed to relay trouble code information that is of a severe enought condition that it warrants stopping the vehicle.";
CM_ SG_ 2566834752 AmberWarningLampStatus "This lamp is used to relay trouble code information that is reporting a problem with the vehicle system but the vehicle need
not be immediately stopped.";
CM_ SG_ 2566834752 ProtectLampStatus "This lamp is used to relay trouble code informatio that is reporting a problem with a vehicle system that is most
probably not electronic subsystem related.";
CM_ BO_ 2566834881 "Active diagnostic trouble codes";
CM_ SG_ 2566834881 FailureModeIdentifier5 "The FMI defines the type of failure detected in the subsystem identified by an SPN.";
CM_ SG_ 2566834881 FailureModeIdentifier4 "The FMI defines the type of failure detected in the subsystem identified by an SPN.";
CM_ SG_ 2566834881 FailureModeIdentifier3 "The FMI defines the type of failure detected in the subsystem identified by an SPN.";
CM_ SG_ 2566834881 FailureModeIdentifier2 "The FMI defines the type of failure detected in the subsystem identified by an SPN.";
CM_ SG_ 2566834881 OccurenceCount5 "The 7 bit occurence count field contains the number of times a fault has gone from active to previously active.";
CM_ SG_ 2566834881 OccurenceCount4 "The 7 bit occurence count field contains the number of times a fault has gone from active to previously active.";
CM_ SG_ 2566834881 OccurenceCount3 "The 7 bit occurence count field contains the number of times a fault has gone from active to previously active.";
CM_ SG_ 2566834881 OccurenceCount2 "The 7 bit occurence count field contains the number of times a fault has gone from active to previously active.";
CM_ SG_ 2566834881 SPN5High "SPN #5 (Conversion Version 4)";
CM_ SG_ 2566834881 SPN5 "SPN #5 (Conversion Version 4)";
CM_ SG_ 2566834881 SPN4High "SPN #4 (Conversion Version 4)";
CM_ SG_ 2566834881 SPN4 "SPN #4 (Conversion Version 4)";
CM_ SG_ 2566834881 SPN3High "SPN #3 (Conversion Version 4)";
CM_ SG_ 2566834881 SPN3 "SPN #3 (Conversion Version 4)";
CM_ SG_ 2566834881 SPN2High "SPN #2 (Conversion Version 4)";
CM_ SG_ 2566834881 SPN2 "SPN #2 (Conversion Version 4)";
CM_ SG_ 2566834881 SPN1 "SPN #1 (Conversion Version 4)";
CM_ SG_ 2566834881 OccurenceCount1 "The 7 bit occurence count field contains the number of times a fault has gone from active to previously active.";
CM_ SG_ 2566834881 SPN1High "SPN #1 (Conversion Version 4)";
CM_ SG_ 2566834881 FailureModeIdentifier1 "The FMI defines the type of failure detected in the subsystem identified by an SPN.";
CM_ SG_ 2566834881 FlashMalfuncIndicatorLamp "This parameter provides the capability to flash the MIL (SPN 3038).";
CM_ SG_ 2566834881 FlashRedStopLamp "This parameter provides the capability to flash the RSL (SPN 3039).";
CM_ SG_ 2566834881 FlashAmberWarningLamp "This parameter provides the capability to flash the AWL (SPN 3040). ";
CM_ SG_ 2566834881 FlashProtectLamp "This parameter provides the capability to flash the engine protect lamp (SPN 3041).";
CM_ SG_ 2566834881 MalfunctionIndicatorLampStatus "A lamp used to relay only emissions-related trouble code information.";
CM_ SG_ 2566834881 RedStopLampState "This lamp is uesed to relay trouble code information that is of a severe enought condition that it warrants stopping the vehicle.";
CM_ SG_ 2566834881 AmberWarningLampStatus "This lamp is used to relay trouble code information that is reporting a problem with the vehicle system but the vehicle need
not be immediately stopped.";
CM_ SG_ 2566834881 ProtectLampStatus "This lamp is used to relay trouble code informatio that is reporting a problem with a vehicle system that is most
probably not electronic subsystem related.";
CM_ BO_ 2566834880 "Active diagnostic trouble codes";
CM_ SG_ 2566834880 FailureModeIdentifier5 "The FMI defines the type of failure detected in the subsystem identified by an SPN.";
CM_ SG_ 2566834880 FailureModeIdentifier4 "The FMI defines the type of failure detected in the subsystem identified by an SPN.";
CM_ SG_ 2566834880 FailureModeIdentifier3 "The FMI defines the type of failure detected in the subsystem identified by an SPN.";
CM_ SG_ 2566834880 FailureModeIdentifier2 "The FMI defines the type of failure detected in the subsystem identified by an SPN.";
CM_ SG_ 2566834880 OccurenceCount5 "The 7 bit occurence count field contains the number of times a fault has gone from active to previously active.";
CM_ SG_ 2566834880 OccurenceCount4 "The 7 bit occurence count field contains the number of times a fault has gone from active to previously active.";
CM_ SG_ 2566834880 OccurenceCount3 "The 7 bit occurence count field contains the number of times a fault has gone from active to previously active.";
CM_ SG_ 2566834880 OccurenceCount2 "The 7 bit occurence count field contains the number of times a fault has gone from active to previously active.";
CM_ SG_ 2566834880 SPN5High "SPN #5 (Conversion Version 4)";
CM_ SG_ 2566834880 SPN5 "SPN #5 (Conversion Version 4)";
CM_ SG_ 2566834880 SPN4High "SPN #4 (Conversion Version 4)";
CM_ SG_ 2566834880 SPN4 "SPN #4 (Conversion Version 4)";
CM_ SG_ 2566834880 SPN3High "SPN #3 (Conversion Version 4)";
CM_ SG_ 2566834880 SPN3 "SPN #3 (Conversion Version 4)";
CM_ SG_ 2566834880 SPN2High "SPN #2 (Conversion Version 4)";
CM_ SG_ 2566834880 SPN2 "SPN #2 (Conversion Version 4)";
CM_ SG_ 2566834880 SPN1 "SPN #1 (Conversion Version 4)";
CM_ SG_ 2566834880 OccurenceCount1 "The 7 bit occurence count field contains the number of times a fault has gone from active to previously active.";
CM_ SG_ 2566834880 SPN1High "SPN #1 (Conversion Version 4)";
CM_ SG_ 2566834880 FailureModeIdentifier1 "The FMI defines the type of failure detected in the subsystem identified by an SPN.";
CM_ SG_ 2566834880 FlashMalfuncIndicatorLamp "This parameter provides the capability to flash the MIL (SPN 3038).";
CM_ SG_ 2566834880 FlashRedStopLamp "This parameter provides the capability to flash the RSL (SPN 3039).";
CM_ SG_ 2566834880 FlashAmberWarningLamp "This parameter provides the capability to flash the AWL (SPN 3040). ";
CM_ SG_ 2566834880 FlashProtectLamp "This parameter provides the capability to flash the engine protect lamp (SPN 3041).";
CM_ SG_ 2566834880 MalfunctionIndicatorLampStatus "A lamp used to relay only emissions-related trouble code information.";
CM_ SG_ 2566834880 RedStopLampState "This lamp is uesed to relay trouble code information that is of a severe enought condition that it warrants stopping the vehicle.";
CM_ SG_ 2566834880 AmberWarningLampStatus "This lamp is used to relay trouble code information that is reporting a problem with the vehicle system but the vehicle need
not be immediately stopped.";
CM_ SG_ 2566834880 ProtectLampStatus "This lamp is used to relay trouble code informatio that is reporting a problem with a vehicle system that is most
probably not electronic subsystem related.";
CM_ BO_ 2566834848 "Active diagnostic trouble codes";
CM_ SG_ 2566834848 FailureModeIdentifier5 "The FMI defines the type of failure detected in the subsystem identified by an SPN.";
CM_ SG_ 2566834848 FailureModeIdentifier4 "The FMI defines the type of failure detected in the subsystem identified by an SPN.";
CM_ SG_ 2566834848 FailureModeIdentifier3 "The FMI defines the type of failure detected in the subsystem identified by an SPN.";
CM_ SG_ 2566834848 FailureModeIdentifier2 "The FMI defines the type of failure detected in the subsystem identified by an SPN.";
CM_ SG_ 2566834848 OccurenceCount5 "The 7 bit occurence count field contains the number of times a fault has gone from active to previously active.";
CM_ SG_ 2566834848 OccurenceCount4 "The 7 bit occurence count field contains the number of times a fault has gone from active to previously active.";
CM_ SG_ 2566834848 OccurenceCount3 "The 7 bit occurence count field contains the number of times a fault has gone from active to previously active.";
CM_ SG_ 2566834848 OccurenceCount2 "The 7 bit occurence count field contains the number of times a fault has gone from active to previously active.";
CM_ SG_ 2566834848 SPN5High "SPN #5 (Conversion Version 4)";
CM_ SG_ 2566834848 SPN5 "SPN #5 (Conversion Version 4)";
CM_ SG_ 2566834848 SPN4High "SPN #4 (Conversion Version 4)";
CM_ SG_ 2566834848 SPN4 "SPN #4 (Conversion Version 4)";
CM_ SG_ 2566834848 SPN3High "SPN #3 (Conversion Version 4)";
CM_ SG_ 2566834848 SPN3 "SPN #3 (Conversion Version 4)";
CM_ SG_ 2566834848 SPN2High "SPN #2 (Conversion Version 4)";
CM_ SG_ 2566834848 SPN2 "SPN #2 (Conversion Version 4)";
CM_ SG_ 2566834848 SPN1 "SPN #1 (Conversion Version 4)";
CM_ SG_ 2566834848 OccurenceCount1 "The 7 bit occurence count field contains the number of times a fault has gone from active to previously active.";
CM_ SG_ 2566834848 SPN1High "SPN #1 (Conversion Version 4)";
CM_ SG_ 2566834848 FailureModeIdentifier1 "The FMI defines the type of failure detected in the subsystem identified by an SPN.";
CM_ SG_ 2566834848 FlashMalfuncIndicatorLamp "This parameter provides the capability to flash the MIL (SPN 3038).";
CM_ SG_ 2566834848 FlashRedStopLamp "This parameter provides the capability to flash the RSL (SPN 3039).";
CM_ SG_ 2566834848 FlashAmberWarningLamp "This parameter provides the capability to flash the AWL (SPN 3040). ";
CM_ SG_ 2566834848 FlashProtectLamp "This parameter provides the capability to flash the engine protect lamp (SPN 3041).";
CM_ SG_ 2566834848 MalfunctionIndicatorLampStatus "A lamp used to relay only emissions-related trouble code information.";
CM_ SG_ 2566834848 RedStopLampState "This lamp is uesed to relay trouble code information that is of a severe enought condition that it warrants stopping the vehicle.";
CM_ SG_ 2566834848 AmberWarningLampStatus "This lamp is used to relay trouble code information that is reporting a problem with the vehicle system but the vehicle need
not be immediately stopped.";
CM_ SG_ 2566834848 ProtectLampStatus "This lamp is used to relay trouble code informatio that is reporting a problem with a vehicle system that is most
probably not electronic subsystem related.";
CM_ BO_ 2348820455 "Torque/Speed Control 1";
CM_ SG_ 2348820455 ControlPurpose "State signal which indicates which control mode the sending device is using to generate the TSC1 command.";
CM_ SG_ 2348820455 TransmissionRate "This parameter indicates the transmission rate at which the sending device will transmit the TSC1 message.";
CM_ SG_ 2348820455 EngRqedTorque_TorqueLimit "Parameter provided to the engine or retarder in the torque/speed control message for controlling or limiting the output torque.";
CM_ SG_ 2348820455 EngRqedSpeed_SpeedLimit "Parameter provided to the engine from external sources in the torque/speed control message.";
CM_ SG_ 2348820455 EngRqedSpeedCtrlConditions "This mode tells the engine control system the governor characteristics that are desired during speed control.";
CM_ BO_ 2348875518 "Torque/Speed Control 1";
CM_ SG_ 2348875518 ControlPurpose "State signal which indicates which control mode the sending device is using to generate the TSC1 command.";
CM_ SG_ 2348875518 TransmissionRate "This parameter indicates the transmission rate at which the sending device will transmit the TSC1 message.";
CM_ SG_ 2348875518 EngRqedTorque_TorqueLimit "Parameter provided to the engine or retarder in the torque/speed control message for controlling or limiting the output torque.";
CM_ SG_ 2348875518 EngRqedSpeed_SpeedLimit "Parameter provided to the engine from external sources in the torque/speed control message.";
CM_ SG_ 2348875518 EngRqedSpeedCtrlConditions "This mode tells the engine control system the governor characteristics that are desired during speed control.";
CM_ BO_ 2566844711 "Cruise Control/Vehicle Speed";
CM_ SG_ 2566844711 EngShutdownOverrideSwitch "Switch signal which indicates the position of the engine shutdown override switch.";
CM_ SG_ 2566844711 EngTestModeSwitch "Switch signal which indicates the position of the engine test mode switch.";
CM_ SG_ 2566844711 EngIdleDecrementSwitch "Switch signal which indicates the position of the idle decrement switch.";
CM_ SG_ 2566844711 EngIdleIncrementSwitch "Switch signal which indicates the position of the idle increment switch.";
CM_ SG_ 2566844711 CruiseCtrlStates "This parameter is used to indicate the current state, or mode, of operation by the cruise control device.";
CM_ SG_ 2566844711 PTOState "This parameter is used to indicate the current state or mode of operation by the power takeoff (PTO) device.";
CM_ SG_ 2566844711 CruiseCtrlSetSpeed "Value of set (chosen) velocity of velocity control system.";
CM_ SG_ 2566844711 CruiseCtrlAccelerateSwitch "Switch signal of the cruise control activator which indicates that the activator is in the position “accelerate.";
CM_ SG_ 2566844711 CruiseCtrlResumeSwitch "Switch signal of the cruise control activator which indicates that the activator is in the position “resume.";
CM_ SG_ 2566844711 CruiseCtrlCoastSwitch "Switch signal of the cruise control activator which indicates that the activator is in the position “coast (decelerate).";
CM_ SG_ 2566844711 CruiseCtrlSetSwitch "Switch signal of the cruise control activator which indicates that the activator is in the position “set.";
CM_ SG_ 2566844711 ClutchSwitch "Switch signal which indicates that the clutch pedal is being pressed.";
CM_ SG_ 2566844711 BrakeSwitch "Switch signal which indicates that the driver operated brake foot pedal is being pressed.";
CM_ SG_ 2566844711 CruiseCtrlEnableSwitch "Switch signal which indicates that it is possible to manage the cruise control function.";
CM_ SG_ 2566844711 CruiseCtrlActive "Cruise control is switched on.";
CM_ SG_ 2566844711 WheelBasedVehicleSpeed "Speed of the vehicle as calculated from wheel or tailshaft speed.";
CM_ SG_ 2566844711 CruiseCtrlPauseSwitch "Switch signal which indicates the position of the Cruise Control Pause Switch used on Remote Cruise Control applications.";
CM_ SG_ 2566844711 ParkingBrakeSwitch "Switch signal which indicates when the parking brake is set.";
CM_ SG_ 2566844711 TwoSpeedAxleSwitch "Switch signal which indicates the current axle range.";
CM_ BO_ 2566844926 "Cruise Control/Vehicle Speed";
CM_ SG_ 2566844926 EngShutdownOverrideSwitch "Switch signal which indicates the position of the engine shutdown override switch.";
CM_ SG_ 2566844926 EngTestModeSwitch "Switch signal which indicates the position of the engine test mode switch.";
CM_ SG_ 2566844926 EngIdleDecrementSwitch "Switch signal which indicates the position of the idle decrement switch.";
CM_ SG_ 2566844926 EngIdleIncrementSwitch "Switch signal which indicates the position of the idle increment switch.";
CM_ SG_ 2566844926 CruiseCtrlStates "This parameter is used to indicate the current state, or mode, of operation by the cruise control device.";
CM_ SG_ 2566844926 PTOState "This parameter is used to indicate the current state or mode of operation by the power takeoff (PTO) device.";
CM_ SG_ 2566844926 CruiseCtrlSetSpeed "Value of set (chosen) velocity of velocity control system.";
CM_ SG_ 2566844926 CruiseCtrlAccelerateSwitch "Switch signal of the cruise control activator which indicates that the activator is in the position “accelerate.";
CM_ SG_ 2566844926 CruiseCtrlResumeSwitch "Switch signal of the cruise control activator which indicates that the activator is in the position “resume.";
CM_ SG_ 2566844926 CruiseCtrlCoastSwitch "Switch signal of the cruise control activator which indicates that the activator is in the position “coast (decelerate).";
CM_ SG_ 2566844926 CruiseCtrlSetSwitch "Switch signal of the cruise control activator which indicates that the activator is in the position “set.";
CM_ SG_ 2566844926 ClutchSwitch "Switch signal which indicates that the clutch pedal is being pressed.";
CM_ SG_ 2566844926 BrakeSwitch "Switch signal which indicates that the driver operated brake foot pedal is being pressed.";
CM_ SG_ 2566844926 CruiseCtrlEnableSwitch "Switch signal which indicates that it is possible to manage the cruise control function.";
CM_ SG_ 2566844926 CruiseCtrlActive "Cruise control is switched on.";
CM_ SG_ 2566844926 WheelBasedVehicleSpeed "Speed of the vehicle as calculated from wheel or tailshaft speed.";
CM_ SG_ 2566844926 CruiseCtrlPauseSwitch "Switch signal which indicates the position of the Cruise Control Pause Switch used on Remote Cruise Control applications.";
CM_ SG_ 2566844926 ParkingBrakeSwitch "Switch signal which indicates when the parking brake is set.";
CM_ SG_ 2566844926 TwoSpeedAxleSwitch "Switch signal which indicates the current axle range.";
CM_ SG_ 2566857470 VCVCCU_V2ICP_RequiredEnergyToPre "VDV261 parameter prec_eamount";
CM_ SG_ 2566857470 VCVCCU_V2ICP_RequiredEnergyToCha "VDV261 parameter bat_eamount";
CM_ SG_ 2566857470 VCVCCU_V2ICP_RequiredDurationToP "VDV261 parameter prec_reqtime";
CM_ SG_ 2566857470 VCVCCU_V2ICP_RequiredDurati_0000 "VDV261 parameter bat_reqtime";
CM_ BO_ 2349572135 "Advanced Emergency Braking System 1";
CM_ BO_ 2566827568 "Air Supply Pressure";
CM_ SG_ 2566827568 AirCompressorStatus "Indicates whether the air compressor is actively compressing air.";
CM_ SG_ 2566827568 AirSuspensionSupplyPress "The pneumatic pressure in the circuit for the electronically controlled air suspension system.";
CM_ SG_ 2566827568 AuxEquipmentSupplyPress "The pneumatic pressure in the auxiliary circuit.";
CM_ SG_ 2566827568 ServiceBrakeAirPressCircuit2 "The pneumatic pressure in the service brake circuit or reservoir #2.";
CM_ SG_ 2566827568 ServiceBrakeAirPressCircuit1 "The pneumatic pressure in the service brake circuit or reservoir #1.";
CM_ SG_ 2566827568 ParkingAnd_OrTrailerAirPress "The pneumatic pressure in the circuit or reservoir for the parking brake and/or the trailer supply.";
CM_ SG_ 2566827568 PneumaticSupplyPress "The pneumatic pressure in the main reservoir, sometimes referred to as the wet tank.";
CM_ BO_ 2362589233 "Air Suspension Control 2";
CM_ SG_ 2362589233 ProhibitAirSuspensionCtrl "This parameter contains an external request to prohibit all air suspension control.";
CM_ SG_ 2362589233 KneelingCmdRearAxle "Command signal to activate the kneeling functionality at the rear axle of the vehicle.";
CM_ SG_ 2362589233 DamperStiffnessRqRearAxle "Demand value for the shock absorber control at the rear axle.";
CM_ SG_ 2362589233 DamperStiffnessRqFrontAxle "Demand value for the shock absorber control at the front axle.";
CM_ SG_ 2362589233 NominalLevelRqRearAxle "Command signal to activate a level of the rear axle programmed and/or memorised in the ECU.";
CM_ SG_ 2362589233 LiftAxle2PosCmd "Signal to command the position / load condition of lift / tag axle #2.";
CM_ SG_ 2362589233 LiftAxle1PosCmd "Signal to command the position/load condition of lift/tag axle #1.";
CM_ BO_ 2362584871 "Air Suspension Control 2";
CM_ SG_ 2362584871 ProhibitAirSuspensionCtrl "This parameter contains an external request to prohibit all air suspension control.";
CM_ SG_ 2362584871 KneelingCmdRearAxle "Command signal to activate the kneeling functionality at the rear axle of the vehicle.";
CM_ SG_ 2362584871 DamperStiffnessRqRearAxle "Demand value for the shock absorber control at the rear axle.";
CM_ SG_ 2362584871 DamperStiffnessRqFrontAxle "Demand value for the shock absorber control at the front axle.";
CM_ SG_ 2362584871 NominalLevelRqRearAxle "Command signal to activate a level of the rear axle programmed and/or memorised in the ECU.";
CM_ SG_ 2362584871 LiftAxle2PosCmd "Signal to command the position / load condition of lift / tag axle #2.";
CM_ SG_ 2362584871 LiftAxle1PosCmd "Signal to command the position/load condition of lift/tag axle #1.";
CM_ SG_ 2566855552 VCVCCU_V2ICP_ScheduledDepartureT "VDV261 parameter Driveoff";
CM_ SG_ 2566855552 VCVCCU_V2ICP_PreconDesiredHVAC "VDV261 parameter prec_hvac";
CM_ SG_ 2566855552 VCVCCU_V2ICP_PreconDesired "VDV261 parameter prec_dsrd";
CM_ SG_ 2566855552 VCVCCU_V2ICP_AmbientTemperature "VDV261 parameter Ambienttemp";
CM_ BO_ 2365479488 "Air Suspension Control 1";
CM_ SG_ 2365479488 SspensionCtrlRefusalInformation "Signal which indicates that the air suspension control cannot perform a request due to the operating conditions.";
CM_ SG_ 2365479488 SuspensionRemoteCtrl2 "Signal which indicates that the suspension system is controlled by remote control #2.";
CM_ SG_ 2365479488 SuspensionRemoteCtrl1 "Signal which indicates that the suspension system is controlled by remote control #1.";
CM_ SG_ 2365479488 RearAxleInBumperRange "Signal which indicates that the vehicle height at the rear axle (SPNs 1723 and 1724) is within the bumper range.";
CM_ SG_ 2365479488 FrontAxleInBumperRange "Signal which indicates that the vehicle height at the front axle (SPNs 1721 and 1722) is within the bumper range.";
CM_ SG_ 2365479488 DoorRelease "Signal which indicates that the doors may be opened.";
CM_ SG_ 2365479488 VehicleMotionInhibit "Signal which indicates whether vehicle motion is inhibited.";
CM_ SG_ 2365479488 SecurityDevice "The signal which indicates the status of the security device.";
CM_ SG_ 2365479488 AboveNominalLevelRearAxle "Signal which indicates whether the actual height of the rear axle is above the nominal (desired) level of the rear axle.";
CM_ SG_ 2365479488 AboveNominalLevelFrontAxle "Signal which indicates whether the actual height of the front axle is above the nominal (desired) level of the front axle.";
CM_ SG_ 2365479488 BelowNominalLevelRearAxle "Signal which indicates whether the actual height of the rear axle is below the nominal (desired) level for the rear axle.";
CM_ SG_ 2365479488 BelowNominalLevelFrontAxle "Signal which indicates whether the actual height of the front axle is below the nominal (desired) level for the front axle.";
CM_ SG_ 2365479488 NominalLevelRearAxle "Signal which indicates the nominal (desired) height of the rear axle to be controlled by the suspension system.";
CM_ SG_ 2365479488 NominalLevelFrontAxle "Signal which indicates the nominal (desired) height of the front axle to be controlled by the suspension system.";
CM_ SG_ 2365479488 LiftAxle2Pos "Signal which indicates the position / load condition of lift axle / tag axle #2.";
CM_ SG_ 2365479488 LiftAxle1Pos "Signal which indicates the position / load condition of lift axle / tag axle #1.";
CM_ BO_ 2565865967 "Electronic Brake Controller 1";
CM_ SG_ 2565865967 SrcAddrssOfCtrllngDvcFrBrkCntrl "The source address of the SAE J1939 device currently controlling the brake system.";
CM_ SG_ 2565865967 BrakePedalPos "Ratio of brake pedal position to maximum pedal position.";
CM_ SG_ 2565865967 TrctrMntdTrilerABSWarningSignal "This parameter commands the tractor-mounted trailer ABS optical warning signal.";
CM_ SG_ 2565865967 TrailerABSStatus "State signal which indicates that ABS in the trailer is actively controlling the brakes.";
CM_ SG_ 2565865967 HaltBrakeSwitch "Switch signal which indicates the position of the halt brake switch.";
CM_ SG_ 2565865967 ATC_ASRInformationSignal "This parameter commands the ATC/ASR driver information signal, for example a dash lamp.";
CM_ SG_ 2565865967 RemoteAccelEnableSwitch "Switch signal which indicates that the remote accelerator has been enabled and controls the engine.";
CM_ SG_ 2565865967 EngAuxEngShutdownSwitch "Switch signal which requests that all engine fueling stop.";
CM_ SG_ 2565865967 EngDerateSwitch "Switch signal used to activate the torque limiting feature of the engine.";
CM_ SG_ 2565865967 AccelInterlockSwitch "Switch signal used to disable the accelerator and remote accelerator inputs, causing the engine to return to idle.";
CM_ SG_ 2565865967 TractionCtrlOverrideSwitch "Switch signal which indicates the position of the traction control override switch.";
CM_ SG_ 2565865967 ASRHillHolderSwitch "Switch signal which indicates the position of the ASR “hill holder” switch.";
CM_ SG_ 2565865967 ASROffroadSwitch "Switch signal which indicates the position of the ASR off-road switch.";
CM_ SG_ 2565865967 ABSOffroadSwitch "Switch signal which indicates the position of the ABS off-road switch.";
CM_ SG_ 2565865967 EBSBrakeSwitch "Switch signal which indicates that the brake pedal is being pressed.";
CM_ SG_ 2565865967 AntiLockBrakingActive "State signal which indicates that the ABS is active.";
CM_ SG_ 2565865967 ASRBrakeCtrlActive "State signal which indicates that ASR brake control is active.";
CM_ SG_ 2565865967 ASREngCtrlActive "State signal which indicates that ASR engine control has been commanded to be active.";
BA_DEF_  "DatabaseVersion" STRING ;
BA_DEF_ BO_  "SingleFrame" INT 0 1;
BA_DEF_ SG_  "SigType" ENUM  "Default","Range","RangeSigned","ASCII","Discrete","Control","ReferencePGN","DTC","StringDelimiter","StringLength","StringLengthControl","MessageCounter","MessageChecksum";
BA_DEF_ SG_  "GenSigEVName" STRING ;
BA_DEF_ SG_  "GenSigILSupport" ENUM  "No","Yes";
BA_DEF_ SG_  "GenSigSendType" ENUM  "Cyclic","OnWrite","OnWriteWithRepetition","OnChange","OnChangeWithRepetition","IfActive","IfActiveWithRepetition","NoSigSendType";
BA_DEF_ SG_  "GenSigStartValue" INT 0 10000;
BA_DEF_ BO_  "GenMsgILSupport" ENUM  "No","Yes";
BA_DEF_ BU_  "NmJ1939Function" INT 0 255;
BA_DEF_ BU_  "NmStationAddress" INT 0 255;
BA_DEF_ BO_  "GenMsgSendType" ENUM  "cyclic","NotUsed","IfActive","NotUsed","NotUsed","NotUsed","NotUsed","NotUsed","noMsgSendType";
BA_DEF_ BO_  "GenMsgRequestable" INT 0 1;
BA_DEF_ BO_  "GenMsgCycleTime" INT 0 3600000;
BA_DEF_ SG_  "SPN" INT 0 524287;
BA_DEF_  "DBName" STRING ;
BA_DEF_  "BusType" STRING ;
BA_DEF_  "ProtocolType" STRING ;
BA_DEF_ BO_  "VFrameFormat" ENUM  "StandardCAN","ExtendedCAN","reserved","J1939PG";
BA_DEF_DEF_  "DatabaseVersion" "";
BA_DEF_DEF_  "SingleFrame" 1;
BA_DEF_DEF_  "SigType" "Default";
BA_DEF_DEF_  "GenSigEVName" "Env@Nodename_@Signame";
BA_DEF_DEF_  "GenSigILSupport" "Yes";
BA_DEF_DEF_  "GenSigSendType" "NoSigSendType";
BA_DEF_DEF_  "GenSigStartValue" 0;
BA_DEF_DEF_  "GenMsgILSupport" "Yes";
BA_DEF_DEF_  "NmJ1939Function" 0;
BA_DEF_DEF_  "NmStationAddress" 254;
BA_DEF_DEF_  "GenMsgSendType" "noMsgSendType";
BA_DEF_DEF_  "GenMsgRequestable" 1;
BA_DEF_DEF_  "GenMsgCycleTime" 0;
BA_DEF_DEF_  "SPN" 0;
BA_DEF_DEF_  "DBName" "VFC_EPIC";
BA_DEF_DEF_  "BusType" "CAN";
BA_DEF_DEF_  "ProtocolType" "";
BA_DEF_DEF_  "VFrameFormat" "J1939PG";
BA_ "DatabaseVersion" "6.0";
BA_ "ProtocolType" "J1939";
BA_ "NmStationAddress" BU_ ILC4 141;
BA_ "NmStationAddress" BU_ ILC3 140;
BA_ "NmStationAddress" BU_ ILC2 139;
BA_ "NmStationAddress" BU_ ILC1 138;
BA_ "NmStationAddress" BU_ C1 193;
BA_ "NmStationAddress" BU_ C0 192;
BA_ "NmStationAddress" BU_ ACU 231;
BA_ "NmStationAddress" BU_ ECAS2 64;
BA_ "NmStationAddress" BU_ CCU 74;
BA_ "NmStationAddress" BU_ TPMS 51;
BA_ "NmStationAddress" BU_ ACC 42;
BA_ "NmStationAddress" BU_ AEBS 160;
BA_ "NmStationAddress" BU_ Door4 212;
BA_ "NmStationAddress" BU_ Door3 211;
BA_ "NmStationAddress" BU_ Door2 210;
BA_ "NmStationAddress" BU_ Door1 209;
BA_ "NmStationAddress" BU_ WWCU 253;
BA_ "NmStationAddress" BU_ HVAC 25;
BA_ "NmStationAddress" BU_ HVAC_HMI 58;
BA_ "NmStationAddress" BU_ EPHS 10;
BA_ "NmStationAddress" BU_ LDWS 232;
BA_ "NmStationAddress" BU_ SCSM 140;
BA_ "NmStationAddress" BU_ EVCC 128;
BA_ "NmStationAddress" BU_ ECAS1 47;
BA_ "NmStationAddress" BU_ BMS 243;
BA_ "NmStationAddress" BU_ SWS 77;
BA_ "NmStationAddress" BU_ EBS 11;
BA_ "NmStationAddress" BU_ VCU2 72;
BA_ "NmStationAddress" BU_ PCi_ECM 0;
BA_ "NmStationAddress" BU_ DCU 239;
BA_ "NmStationAddress" BU_ EPH 80;
BA_ "NmStationAddress" BU_ VFC 49;
BA_ "NmStationAddress" BU_ VCU1 39;
BA_ "NmStationAddress" BU_ Tachograph 238;
BA_ "NmStationAddress" BU_ EPIC 23;
BA_ "NmJ1939Function" BU_ EPIC 19;
BA_ "GenMsgCycleTime" BO_ 2566853681 100;
BA_ "GenMsgSendType" BO_ 2566853681 0;
BA_ "GenMsgSendType" BO_ 2565835313 0;
BA_ "GenMsgCycleTime" BO_ 2565835313 100;
BA_ "GenMsgSendType" BO_ 2566909991 0;
BA_ "GenMsgCycleTime" BO_ 2566909991 100;
BA_ "GenMsgSendType" BO_ 2566826033 0;
BA_ "GenMsgCycleTime" BO_ 2566826033 500;
BA_ "GenMsgCycleTime" BO_ 2566907697 100;
BA_ "GenMsgSendType" BO_ 2566907697 0;
BA_ "GenMsgCycleTime" BO_ 2348820455 10;
BA_ "GenMsgSendType" BO_ 2348820455 0;
BA_ "GenMsgCycleTime" BO_ 2348875518 10;
BA_ "GenMsgSendType" BO_ 2348875518 0;
BA_ "GenMsgSendType" BO_ 2566844711 0;
BA_ "GenMsgCycleTime" BO_ 2566844711 100;
BA_ "GenMsgCycleTime" BO_ 2566844926 100;
BA_ "GenMsgSendType" BO_ 2566844926 0;
BA_ "GenMsgRequestable" BO_ 2566857470 0;
BA_ "GenMsgSendType" BO_ 2566857470 0;
BA_ "GenMsgCycleTime" BO_ 2566857470 1000;
BA_ "GenMsgCycleTime" BO_ 2563788849 100;
BA_ "GenMsgSendType" BO_ 2563788849 0;
BA_ "GenMsgSendType" BO_ 2349572135 0;
BA_ "GenMsgCycleTime" BO_ 2349572135 50;
BA_ "GenMsgSendType" BO_ 2566855217 0;
BA_ "GenMsgCycleTime" BO_ 2566855217 100;
BA_ "GenMsgCycleTime" BO_ 2565475121 1000;
BA_ "GenMsgSendType" BO_ 2565475121 0;
BA_ "GenMsgSendType" BO_ 2566827568 0;
BA_ "GenMsgCycleTime" BO_ 2566827568 1000;
BA_ "GenMsgSendType" BO_ 2362589233 0;
BA_ "GenMsgCycleTime" BO_ 2362589233 100;
BA_ "GenMsgCycleTime" BO_ 2362584871 100;
BA_ "GenMsgSendType" BO_ 2362584871 0;
BA_ "GenMsgSendType" BO_ 2566854961 0;
BA_ "GenMsgCycleTime" BO_ 2566854961 100;
BA_ "GenMsgSendType" BO_ 2566855552 0;
BA_ "GenMsgRequestable" BO_ 2566855552 0;
BA_ "GenMsgCycleTime" BO_ 2566855552 1000;
BA_ "GenMsgCycleTime" BO_ 2566850535 100;
BA_ "GenMsgSendType" BO_ 2566850535 0;
BA_ "GenMsgCycleTime" BO_ 2365479488 100;
BA_ "GenMsgSendType" BO_ 2365479488 0;
BA_ "GenMsgCycleTime" BO_ 2565865967 100;
BA_ "GenMsgSendType" BO_ 2565865967 0;
BA_ "GenMsgCycleTime" BO_ 2566874442 1000;
BA_ "GenMsgSendType" BO_ 2566874442 0;
BA_ "SPN" SG_ 2147548812 FailureModeIdentifier5 1215;
BA_ "SPN" SG_ 2147548812 FailureModeIdentifier4 1215;
BA_ "SPN" SG_ 2147548812 FailureModeIdentifier3 1215;
BA_ "SPN" SG_ 2147548812 FailureModeIdentifier2 1215;
BA_ "SPN" SG_ 2147548812 OccurenceCount5 1216;
BA_ "SPN" SG_ 2147548812 OccurenceCount4 1216;
BA_ "SPN" SG_ 2147548812 OccurenceCount3 1216;
BA_ "SPN" SG_ 2147548812 OccurenceCount2 1216;
BA_ "SPN" SG_ 2147548812 SPNConversionMethod5 1706;
BA_ "SPN" SG_ 2147548812 SPNConversionMethod4 1706;
BA_ "SPN" SG_ 2147548812 SPNConversionMethod3 1706;
BA_ "SPN" SG_ 2147548812 SPNConversionMethod2 1706;
BA_ "SPN" SG_ 2147548812 SPN5High 1214;
BA_ "SPN" SG_ 2147548812 SPN5 1214;
BA_ "SPN" SG_ 2147548812 SPN4High 1214;
BA_ "SPN" SG_ 2147548812 SPN4 1214;
BA_ "SPN" SG_ 2147548812 SPN3High 1214;
BA_ "SPN" SG_ 2147548812 SPN3 1214;
BA_ "SPN" SG_ 2147548812 SPN2High 1214;
BA_ "SPN" SG_ 2147548812 SPN2 1214;
BA_ "SPN" SG_ 2147548812 SPN1 1214;
BA_ "SPN" SG_ 2147548812 SPNConversionMethod1 1706;
BA_ "SPN" SG_ 2147548812 OccurenceCount1 1216;
BA_ "SPN" SG_ 2147548812 SPN1High 1214;
BA_ "SPN" SG_ 2147548812 FailureModeIdentifier1 1215;
BA_ "SPN" SG_ 2147548812 FlashMalfuncIndicatorLamp 3038;
BA_ "SPN" SG_ 2147548812 FlashRedStopLamp 3039;
BA_ "SPN" SG_ 2147548812 FlashAmberWarningLamp 3040;
BA_ "SPN" SG_ 2147548812 FlashProtectLamp 3041;
BA_ "SPN" SG_ 2147548812 MalfunctionIndicatorLampStatus 1213;
BA_ "SPN" SG_ 2147548812 RedStopLampState 623;
BA_ "SPN" SG_ 2147548812 AmberWarningLampStatus 624;
BA_ "SPN" SG_ 2147548812 ProtectLampStatus 987;
BA_ "SPN" SG_ 2566834829 FailureModeIdentifier5 1215;
BA_ "SPN" SG_ 2566834829 FailureModeIdentifier4 1215;
BA_ "SPN" SG_ 2566834829 FailureModeIdentifier3 1215;
BA_ "SPN" SG_ 2566834829 FailureModeIdentifier2 1215;
BA_ "SPN" SG_ 2566834829 OccurenceCount5 1216;
BA_ "SPN" SG_ 2566834829 OccurenceCount4 1216;
BA_ "SPN" SG_ 2566834829 OccurenceCount3 1216;
BA_ "SPN" SG_ 2566834829 OccurenceCount2 1216;
BA_ "SPN" SG_ 2566834829 SPNConversionMethod5 1706;
BA_ "SPN" SG_ 2566834829 SPNConversionMethod4 1706;
BA_ "SPN" SG_ 2566834829 SPNConversionMethod3 1706;
BA_ "SPN" SG_ 2566834829 SPNConversionMethod2 1706;
BA_ "SPN" SG_ 2566834829 SPN5High 1214;
BA_ "SPN" SG_ 2566834829 SPN5 1214;
BA_ "SPN" SG_ 2566834829 SPN4High 1214;
BA_ "SPN" SG_ 2566834829 SPN4 1214;
BA_ "SPN" SG_ 2566834829 SPN3High 1214;
BA_ "SPN" SG_ 2566834829 SPN3 1214;
BA_ "SPN" SG_ 2566834829 SPN2High 1214;
BA_ "SPN" SG_ 2566834829 SPN2 1214;
BA_ "SPN" SG_ 2566834829 SPN1 1214;
BA_ "SPN" SG_ 2566834829 SPNConversionMethod1 1706;
BA_ "SPN" SG_ 2566834829 OccurenceCount1 1216;
BA_ "SPN" SG_ 2566834829 SPN1High 1214;
BA_ "SPN" SG_ 2566834829 FailureModeIdentifier1 1215;
BA_ "SPN" SG_ 2566834829 FlashMalfuncIndicatorLamp 3038;
BA_ "SPN" SG_ 2566834829 FlashRedStopLamp 3039;
BA_ "SPN" SG_ 2566834829 FlashAmberWarningLamp 3040;
BA_ "SPN" SG_ 2566834829 FlashProtectLamp 3041;
BA_ "SPN" SG_ 2566834829 MalfunctionIndicatorLampStatus 1213;
BA_ "SPN" SG_ 2566834829 RedStopLampState 623;
BA_ "SPN" SG_ 2566834829 AmberWarningLampStatus 624;
BA_ "SPN" SG_ 2566834829 ProtectLampStatus 987;
BA_ "SPN" SG_ 2147483648 FailureModeIdentifier5 1215;
BA_ "SPN" SG_ 2147483648 FailureModeIdentifier4 1215;
BA_ "SPN" SG_ 2147483648 FailureModeIdentifier3 1215;
BA_ "SPN" SG_ 2147483648 FailureModeIdentifier2 1215;
BA_ "SPN" SG_ 2147483648 OccurenceCount5 1216;
BA_ "SPN" SG_ 2147483648 OccurenceCount4 1216;
BA_ "SPN" SG_ 2147483648 OccurenceCount3 1216;
BA_ "SPN" SG_ 2147483648 OccurenceCount2 1216;
BA_ "SPN" SG_ 2147483648 SPNConversionMethod5 1706;
BA_ "SPN" SG_ 2147483648 SPNConversionMethod4 1706;
BA_ "SPN" SG_ 2147483648 SPNConversionMethod3 1706;
BA_ "SPN" SG_ 2147483648 SPNConversionMethod2 1706;
BA_ "SPN" SG_ 2147483648 SPN5High 1214;
BA_ "SPN" SG_ 2147483648 SPN5 1214;
BA_ "SPN" SG_ 2147483648 SPN4High 1214;
BA_ "SPN" SG_ 2147483648 SPN4 1214;
BA_ "SPN" SG_ 2147483648 SPN3High 1214;
BA_ "SPN" SG_ 2147483648 SPN3 1214;
BA_ "SPN" SG_ 2147483648 SPN2High 1214;
BA_ "SPN" SG_ 2147483648 SPN2 1214;
BA_ "SPN" SG_ 2147483648 SPN1 1214;
BA_ "SPN" SG_ 2147483648 SPNConversionMethod1 1706;
BA_ "SPN" SG_ 2147483648 OccurenceCount1 1216;
BA_ "SPN" SG_ 2147483648 SPN1High 1214;
BA_ "SPN" SG_ 2147483648 FailureModeIdentifier1 1215;
BA_ "SPN" SG_ 2147483648 FlashMalfuncIndicatorLamp 3038;
BA_ "SPN" SG_ 2147483648 FlashRedStopLamp 3039;
BA_ "SPN" SG_ 2147483648 FlashAmberWarningLamp 3040;
BA_ "SPN" SG_ 2147483648 FlashProtectLamp 3041;
BA_ "SPN" SG_ 2147483648 MalfunctionIndicatorLampStatus 1213;
BA_ "SPN" SG_ 2147483648 RedStopLampState 623;
BA_ "SPN" SG_ 2147483648 AmberWarningLampStatus 624;
BA_ "SPN" SG_ 2147483648 ProtectLampStatus 987;
BA_ "SPN" SG_ 2566834827 FailureModeIdentifier5 1215;
BA_ "SPN" SG_ 2566834827 FailureModeIdentifier4 1215;
BA_ "SPN" SG_ 2566834827 FailureModeIdentifier3 1215;
BA_ "SPN" SG_ 2566834827 FailureModeIdentifier2 1215;
BA_ "SPN" SG_ 2566834827 OccurenceCount5 1216;
BA_ "SPN" SG_ 2566834827 OccurenceCount4 1216;
BA_ "SPN" SG_ 2566834827 OccurenceCount3 1216;
BA_ "SPN" SG_ 2566834827 OccurenceCount2 1216;
BA_ "SPN" SG_ 2566834827 SPNConversionMethod5 1706;
BA_ "SPN" SG_ 2566834827 SPNConversionMethod4 1706;
BA_ "SPN" SG_ 2566834827 SPNConversionMethod3 1706;
BA_ "SPN" SG_ 2566834827 SPNConversionMethod2 1706;
BA_ "SPN" SG_ 2566834827 SPN5High 1214;
BA_ "SPN" SG_ 2566834827 SPN5 1214;
BA_ "SPN" SG_ 2566834827 SPN4High 1214;
BA_ "SPN" SG_ 2566834827 SPN4 1214;
BA_ "SPN" SG_ 2566834827 SPN3High 1214;
BA_ "SPN" SG_ 2566834827 SPN3 1214;
BA_ "SPN" SG_ 2566834827 SPN2High 1214;
BA_ "SPN" SG_ 2566834827 SPN2 1214;
BA_ "SPN" SG_ 2566834827 SPN1 1214;
BA_ "SPN" SG_ 2566834827 SPNConversionMethod1 1706;
BA_ "SPN" SG_ 2566834827 OccurenceCount1 1216;
BA_ "SPN" SG_ 2566834827 SPN1High 1214;
BA_ "SPN" SG_ 2566834827 FailureModeIdentifier1 1215;
BA_ "SPN" SG_ 2566834827 FlashMalfuncIndicatorLamp 3038;
BA_ "SPN" SG_ 2566834827 FlashRedStopLamp 3039;
BA_ "SPN" SG_ 2566834827 FlashAmberWarningLamp 3040;
BA_ "SPN" SG_ 2566834827 FlashProtectLamp 3041;
BA_ "SPN" SG_ 2566834827 MalfunctionIndicatorLampStatus 1213;
BA_ "SPN" SG_ 2566834827 RedStopLampState 623;
BA_ "SPN" SG_ 2566834827 AmberWarningLampStatus 624;
BA_ "SPN" SG_ 2566834827 ProtectLampStatus 987;
BA_ "SPN" SG_ 2566834826 FailureModeIdentifier5 1215;
BA_ "SPN" SG_ 2566834826 FailureModeIdentifier4 1215;
BA_ "SPN" SG_ 2566834826 FailureModeIdentifier3 1215;
BA_ "SPN" SG_ 2566834826 FailureModeIdentifier2 1215;
BA_ "SPN" SG_ 2566834826 OccurenceCount5 1216;
BA_ "SPN" SG_ 2566834826 OccurenceCount4 1216;
BA_ "SPN" SG_ 2566834826 OccurenceCount3 1216;
BA_ "SPN" SG_ 2566834826 OccurenceCount2 1216;
BA_ "SPN" SG_ 2566834826 SPNConversionMethod5 1706;
BA_ "SPN" SG_ 2566834826 SPNConversionMethod4 1706;
BA_ "SPN" SG_ 2566834826 SPNConversionMethod3 1706;
BA_ "SPN" SG_ 2566834826 SPNConversionMethod2 1706;
BA_ "SPN" SG_ 2566834826 SPN5High 1214;
BA_ "SPN" SG_ 2566834826 SPN5 1214;
BA_ "SPN" SG_ 2566834826 SPN4High 1214;
BA_ "SPN" SG_ 2566834826 SPN4 1214;
BA_ "SPN" SG_ 2566834826 SPN3High 1214;
BA_ "SPN" SG_ 2566834826 SPN3 1214;
BA_ "SPN" SG_ 2566834826 SPN2High 1214;
BA_ "SPN" SG_ 2566834826 SPN2 1214;
BA_ "SPN" SG_ 2566834826 SPN1 1214;
BA_ "SPN" SG_ 2566834826 SPNConversionMethod1 1706;
BA_ "SPN" SG_ 2566834826 OccurenceCount1 1216;
BA_ "SPN" SG_ 2566834826 SPN1High 1214;
BA_ "SPN" SG_ 2566834826 FailureModeIdentifier1 1215;
BA_ "SPN" SG_ 2566834826 FlashMalfuncIndicatorLamp 3038;
BA_ "SPN" SG_ 2566834826 FlashRedStopLamp 3039;
BA_ "SPN" SG_ 2566834826 FlashAmberWarningLamp 3040;
BA_ "SPN" SG_ 2566834826 FlashProtectLamp 3041;
BA_ "SPN" SG_ 2566834826 MalfunctionIndicatorLampStatus 1213;
BA_ "SPN" SG_ 2566834826 RedStopLampState 623;
BA_ "SPN" SG_ 2566834826 AmberWarningLampStatus 624;
BA_ "SPN" SG_ 2566834826 ProtectLampStatus 987;
BA_ "SPN" SG_ 2566834920 FailureModeIdentifier5 1215;
BA_ "SPN" SG_ 2566834920 FailureModeIdentifier4 1215;
BA_ "SPN" SG_ 2566834920 FailureModeIdentifier3 1215;
BA_ "SPN" SG_ 2566834920 FailureModeIdentifier2 1215;
BA_ "SPN" SG_ 2566834920 OccurenceCount5 1216;
BA_ "SPN" SG_ 2566834920 OccurenceCount4 1216;
BA_ "SPN" SG_ 2566834920 OccurenceCount3 1216;
BA_ "SPN" SG_ 2566834920 OccurenceCount2 1216;
BA_ "SPN" SG_ 2566834920 SPNConversionMethod5 1706;
BA_ "SPN" SG_ 2566834920 SPNConversionMethod4 1706;
BA_ "SPN" SG_ 2566834920 SPNConversionMethod3 1706;
BA_ "SPN" SG_ 2566834920 SPNConversionMethod2 1706;
BA_ "SPN" SG_ 2566834920 SPN5High 1214;
BA_ "SPN" SG_ 2566834920 SPN5 1214;
BA_ "SPN" SG_ 2566834920 SPN4High 1214;
BA_ "SPN" SG_ 2566834920 SPN4 1214;
BA_ "SPN" SG_ 2566834920 SPN3High 1214;
BA_ "SPN" SG_ 2566834920 SPN3 1214;
BA_ "SPN" SG_ 2566834920 SPN2High 1214;
BA_ "SPN" SG_ 2566834920 SPN2 1214;
BA_ "SPN" SG_ 2566834920 SPN1 1214;
BA_ "SPN" SG_ 2566834920 SPNConversionMethod1 1706;
BA_ "SPN" SG_ 2566834920 OccurenceCount1 1216;
BA_ "SPN" SG_ 2566834920 SPN1High 1214;
BA_ "SPN" SG_ 2566834920 FailureModeIdentifier1 1215;
BA_ "SPN" SG_ 2566834920 FlashMalfuncIndicatorLamp 3038;
BA_ "SPN" SG_ 2566834920 FlashRedStopLamp 3039;
BA_ "SPN" SG_ 2566834920 FlashAmberWarningLamp 3040;
BA_ "SPN" SG_ 2566834920 FlashProtectLamp 3041;
BA_ "SPN" SG_ 2566834920 MalfunctionIndicatorLampStatus 1213;
BA_ "SPN" SG_ 2566834920 RedStopLampState 623;
BA_ "SPN" SG_ 2566834920 AmberWarningLampStatus 624;
BA_ "SPN" SG_ 2566834920 ProtectLampStatus 987;
BA_ "SPN" SG_ 2566834752 FailureModeIdentifier5 1215;
BA_ "SPN" SG_ 2566834752 FailureModeIdentifier4 1215;
BA_ "SPN" SG_ 2566834752 FailureModeIdentifier3 1215;
BA_ "SPN" SG_ 2566834752 FailureModeIdentifier2 1215;
BA_ "SPN" SG_ 2566834752 OccurenceCount5 1216;
BA_ "SPN" SG_ 2566834752 OccurenceCount4 1216;
BA_ "SPN" SG_ 2566834752 OccurenceCount3 1216;
BA_ "SPN" SG_ 2566834752 OccurenceCount2 1216;
BA_ "SPN" SG_ 2566834752 SPNConversionMethod5 1706;
BA_ "SPN" SG_ 2566834752 SPNConversionMethod4 1706;
BA_ "SPN" SG_ 2566834752 SPNConversionMethod3 1706;
BA_ "SPN" SG_ 2566834752 SPNConversionMethod2 1706;
BA_ "SPN" SG_ 2566834752 SPN5High 1214;
BA_ "SPN" SG_ 2566834752 SPN5 1214;
BA_ "SPN" SG_ 2566834752 SPN4High 1214;
BA_ "SPN" SG_ 2566834752 SPN4 1214;
BA_ "SPN" SG_ 2566834752 SPN3High 1214;
BA_ "SPN" SG_ 2566834752 SPN3 1214;
BA_ "SPN" SG_ 2566834752 SPN2High 1214;
BA_ "SPN" SG_ 2566834752 SPN2 1214;
BA_ "SPN" SG_ 2566834752 SPN1 1214;
BA_ "SPN" SG_ 2566834752 SPNConversionMethod1 1706;
BA_ "SPN" SG_ 2566834752 OccurenceCount1 1216;
BA_ "SPN" SG_ 2566834752 SPN1High 1214;
BA_ "SPN" SG_ 2566834752 FailureModeIdentifier1 1215;
BA_ "SPN" SG_ 2566834752 FlashMalfuncIndicatorLamp 3038;
BA_ "SPN" SG_ 2566834752 FlashRedStopLamp 3039;
BA_ "SPN" SG_ 2566834752 FlashAmberWarningLamp 3040;
BA_ "SPN" SG_ 2566834752 FlashProtectLamp 3041;
BA_ "SPN" SG_ 2566834752 MalfunctionIndicatorLampStatus 1213;
BA_ "SPN" SG_ 2566834752 RedStopLampState 623;
BA_ "SPN" SG_ 2566834752 AmberWarningLampStatus 624;
BA_ "SPN" SG_ 2566834752 ProtectLampStatus 987;
BA_ "SPN" SG_ 2566834881 FailureModeIdentifier5 1215;
BA_ "SPN" SG_ 2566834881 FailureModeIdentifier4 1215;
BA_ "SPN" SG_ 2566834881 FailureModeIdentifier3 1215;
BA_ "SPN" SG_ 2566834881 FailureModeIdentifier2 1215;
BA_ "SPN" SG_ 2566834881 OccurenceCount5 1216;
BA_ "SPN" SG_ 2566834881 OccurenceCount4 1216;
BA_ "SPN" SG_ 2566834881 OccurenceCount3 1216;
BA_ "SPN" SG_ 2566834881 OccurenceCount2 1216;
BA_ "SPN" SG_ 2566834881 SPNConversionMethod5 1706;
BA_ "SPN" SG_ 2566834881 SPNConversionMethod4 1706;
BA_ "SPN" SG_ 2566834881 SPNConversionMethod3 1706;
BA_ "SPN" SG_ 2566834881 SPNConversionMethod2 1706;
BA_ "SPN" SG_ 2566834881 SPN5High 1214;
BA_ "SPN" SG_ 2566834881 SPN5 1214;
BA_ "SPN" SG_ 2566834881 SPN4High 1214;
BA_ "SPN" SG_ 2566834881 SPN4 1214;
BA_ "SPN" SG_ 2566834881 SPN3High 1214;
BA_ "SPN" SG_ 2566834881 SPN3 1214;
BA_ "SPN" SG_ 2566834881 SPN2High 1214;
BA_ "SPN" SG_ 2566834881 SPN2 1214;
BA_ "SPN" SG_ 2566834881 SPN1 1214;
BA_ "SPN" SG_ 2566834881 SPNConversionMethod1 1706;
BA_ "SPN" SG_ 2566834881 OccurenceCount1 1216;
BA_ "SPN" SG_ 2566834881 SPN1High 1214;
BA_ "SPN" SG_ 2566834881 FailureModeIdentifier1 1215;
BA_ "SPN" SG_ 2566834881 FlashMalfuncIndicatorLamp 3038;
BA_ "SPN" SG_ 2566834881 FlashRedStopLamp 3039;
BA_ "SPN" SG_ 2566834881 FlashAmberWarningLamp 3040;
BA_ "SPN" SG_ 2566834881 FlashProtectLamp 3041;
BA_ "SPN" SG_ 2566834881 MalfunctionIndicatorLampStatus 1213;
BA_ "SPN" SG_ 2566834881 RedStopLampState 623;
BA_ "SPN" SG_ 2566834881 AmberWarningLampStatus 624;
BA_ "SPN" SG_ 2566834881 ProtectLampStatus 987;
BA_ "SPN" SG_ 2566834880 FailureModeIdentifier5 1215;
BA_ "SPN" SG_ 2566834880 FailureModeIdentifier4 1215;
BA_ "SPN" SG_ 2566834880 FailureModeIdentifier3 1215;
BA_ "SPN" SG_ 2566834880 FailureModeIdentifier2 1215;
BA_ "SPN" SG_ 2566834880 OccurenceCount5 1216;
BA_ "SPN" SG_ 2566834880 OccurenceCount4 1216;
BA_ "SPN" SG_ 2566834880 OccurenceCount3 1216;
BA_ "SPN" SG_ 2566834880 OccurenceCount2 1216;
BA_ "SPN" SG_ 2566834880 SPNConversionMethod5 1706;
BA_ "SPN" SG_ 2566834880 SPNConversionMethod4 1706;
BA_ "SPN" SG_ 2566834880 SPNConversionMethod3 1706;
BA_ "SPN" SG_ 2566834880 SPNConversionMethod2 1706;
BA_ "SPN" SG_ 2566834880 SPN5High 1214;
BA_ "SPN" SG_ 2566834880 SPN5 1214;
BA_ "SPN" SG_ 2566834880 SPN4High 1214;
BA_ "SPN" SG_ 2566834880 SPN4 1214;
BA_ "SPN" SG_ 2566834880 SPN3High 1214;
BA_ "SPN" SG_ 2566834880 SPN3 1214;
BA_ "SPN" SG_ 2566834880 SPN2High 1214;
BA_ "SPN" SG_ 2566834880 SPN2 1214;
BA_ "SPN" SG_ 2566834880 SPN1 1214;
BA_ "SPN" SG_ 2566834880 SPNConversionMethod1 1706;
BA_ "SPN" SG_ 2566834880 OccurenceCount1 1216;
BA_ "SPN" SG_ 2566834880 SPN1High 1214;
BA_ "SPN" SG_ 2566834880 FailureModeIdentifier1 1215;
BA_ "SPN" SG_ 2566834880 FlashMalfuncIndicatorLamp 3038;
BA_ "SPN" SG_ 2566834880 FlashRedStopLamp 3039;
BA_ "SPN" SG_ 2566834880 FlashAmberWarningLamp 3040;
BA_ "SPN" SG_ 2566834880 FlashProtectLamp 3041;
BA_ "SPN" SG_ 2566834880 MalfunctionIndicatorLampStatus 1213;
BA_ "SPN" SG_ 2566834880 RedStopLampState 623;
BA_ "SPN" SG_ 2566834880 AmberWarningLampStatus 624;
BA_ "SPN" SG_ 2566834880 ProtectLampStatus 987;
BA_ "SPN" SG_ 2566834848 FailureModeIdentifier5 1215;
BA_ "SPN" SG_ 2566834848 FailureModeIdentifier4 1215;
BA_ "SPN" SG_ 2566834848 FailureModeIdentifier3 1215;
BA_ "SPN" SG_ 2566834848 FailureModeIdentifier2 1215;
BA_ "SPN" SG_ 2566834848 OccurenceCount5 1216;
BA_ "SPN" SG_ 2566834848 OccurenceCount4 1216;
BA_ "SPN" SG_ 2566834848 OccurenceCount3 1216;
BA_ "SPN" SG_ 2566834848 OccurenceCount2 1216;
BA_ "SPN" SG_ 2566834848 SPNConversionMethod5 1706;
BA_ "SPN" SG_ 2566834848 SPNConversionMethod4 1706;
BA_ "SPN" SG_ 2566834848 SPNConversionMethod3 1706;
BA_ "SPN" SG_ 2566834848 SPNConversionMethod2 1706;
BA_ "SPN" SG_ 2566834848 SPN5High 1214;
BA_ "SPN" SG_ 2566834848 SPN5 1214;
BA_ "SPN" SG_ 2566834848 SPN4High 1214;
BA_ "SPN" SG_ 2566834848 SPN4 1214;
BA_ "SPN" SG_ 2566834848 SPN3High 1214;
BA_ "SPN" SG_ 2566834848 SPN3 1214;
BA_ "SPN" SG_ 2566834848 SPN2High 1214;
BA_ "SPN" SG_ 2566834848 SPN2 1214;
BA_ "SPN" SG_ 2566834848 SPN1 1214;
BA_ "SPN" SG_ 2566834848 SPNConversionMethod1 1706;
BA_ "SPN" SG_ 2566834848 OccurenceCount1 1216;
BA_ "SPN" SG_ 2566834848 SPN1High 1214;
BA_ "SPN" SG_ 2566834848 FailureModeIdentifier1 1215;
BA_ "SPN" SG_ 2566834848 FlashMalfuncIndicatorLamp 3038;
BA_ "SPN" SG_ 2566834848 FlashRedStopLamp 3039;
BA_ "SPN" SG_ 2566834848 FlashAmberWarningLamp 3040;
BA_ "SPN" SG_ 2566834848 FlashProtectLamp 3041;
BA_ "SPN" SG_ 2566834848 MalfunctionIndicatorLampStatus 1213;
BA_ "SPN" SG_ 2566834848 RedStopLampState 623;
BA_ "SPN" SG_ 2566834848 AmberWarningLampStatus 624;
BA_ "SPN" SG_ 2566834848 ProtectLampStatus 987;
BA_ "GenSigStartValue" SG_ 2566826033 ArticulationAngle 125;
BA_ "SPN" SG_ 2348820455 ControlPurpose 3350;
BA_ "SPN" SG_ 2348820455 TransmissionRate 3349;
BA_ "SPN" SG_ 2348820455 EngRqedTorque_TorqueLimit 518;
BA_ "SPN" SG_ 2348820455 EngRqedSpeed_SpeedLimit 898;
BA_ "SPN" SG_ 2348820455 OverrideCtrlModePriority 897;
BA_ "SPN" SG_ 2348820455 EngRqedSpeedCtrlConditions 696;
BA_ "SPN" SG_ 2348820455 EngOverrideCtrlMode 695;
BA_ "SPN" SG_ 2348875518 ControlPurpose 3350;
BA_ "SPN" SG_ 2348875518 TransmissionRate 3349;
BA_ "SPN" SG_ 2348875518 EngRqedTorque_TorqueLimit 518;
BA_ "SPN" SG_ 2348875518 EngRqedSpeed_SpeedLimit 898;
BA_ "SPN" SG_ 2348875518 OverrideCtrlModePriority 897;
BA_ "SPN" SG_ 2348875518 EngRqedSpeedCtrlConditions 696;
BA_ "SPN" SG_ 2348875518 EngOverrideCtrlMode 695;
BA_ "SPN" SG_ 2566844711 ParkBrakeReleaseInhibitRq 3807;
BA_ "SPN" SG_ 2566844711 EngShutdownOverrideSwitch 1237;
BA_ "SPN" SG_ 2566844711 EngTestModeSwitch 966;
BA_ "SPN" SG_ 2566844711 EngIdleDecrementSwitch 967;
BA_ "SPN" SG_ 2566844711 EngIdleIncrementSwitch 968;
BA_ "SPN" SG_ 2566844711 CruiseCtrlStates 527;
BA_ "SPN" SG_ 2566844711 PTOState 976;
BA_ "SPN" SG_ 2566844711 CruiseCtrlSetSpeed 86;
BA_ "SPN" SG_ 2566844711 CruiseCtrlAccelerateSwitch 602;
BA_ "SPN" SG_ 2566844711 CruiseCtrlResumeSwitch 601;
BA_ "SPN" SG_ 2566844711 CruiseCtrlCoastSwitch 600;
BA_ "SPN" SG_ 2566844711 CruiseCtrlSetSwitch 599;
BA_ "SPN" SG_ 2566844711 ClutchSwitch 598;
BA_ "SPN" SG_ 2566844711 BrakeSwitch 597;
BA_ "SPN" SG_ 2566844711 CruiseCtrlEnableSwitch 596;
BA_ "SPN" SG_ 2566844711 CruiseCtrlActive 595;
BA_ "SPN" SG_ 2566844711 WheelBasedVehicleSpeed 84;
BA_ "SPN" SG_ 2566844711 CruiseCtrlPauseSwitch 1633;
BA_ "SPN" SG_ 2566844711 ParkingBrakeSwitch 70;
BA_ "SPN" SG_ 2566844711 TwoSpeedAxleSwitch 69;
BA_ "SPN" SG_ 2566844926 ParkBrakeReleaseInhibitRq 3807;
BA_ "SPN" SG_ 2566844926 EngShutdownOverrideSwitch 1237;
BA_ "SPN" SG_ 2566844926 EngTestModeSwitch 966;
BA_ "SPN" SG_ 2566844926 EngIdleDecrementSwitch 967;
BA_ "SPN" SG_ 2566844926 EngIdleIncrementSwitch 968;
BA_ "SPN" SG_ 2566844926 CruiseCtrlStates 527;
BA_ "SPN" SG_ 2566844926 PTOState 976;
BA_ "SPN" SG_ 2566844926 CruiseCtrlSetSpeed 86;
BA_ "SPN" SG_ 2566844926 CruiseCtrlAccelerateSwitch 602;
BA_ "SPN" SG_ 2566844926 CruiseCtrlResumeSwitch 601;
BA_ "SPN" SG_ 2566844926 CruiseCtrlCoastSwitch 600;
BA_ "SPN" SG_ 2566844926 CruiseCtrlSetSwitch 599;
BA_ "SPN" SG_ 2566844926 ClutchSwitch 598;
BA_ "SPN" SG_ 2566844926 BrakeSwitch 597;
BA_ "SPN" SG_ 2566844926 CruiseCtrlEnableSwitch 596;
BA_ "SPN" SG_ 2566844926 CruiseCtrlActive 595;
BA_ "SPN" SG_ 2566844926 WheelBasedVehicleSpeed 84;
BA_ "SPN" SG_ 2566844926 CruiseCtrlPauseSwitch 1633;
BA_ "SPN" SG_ 2566844926 ParkingBrakeSwitch 70;
BA_ "SPN" SG_ 2566844926 TwoSpeedAxleSwitch 69;
BA_ "GenSigStartValue" SG_ 2566857470 VCVCCU_V2ICP_RequiredDurationToP 255;
BA_ "GenSigStartValue" SG_ 2566857470 VCVCCU_V2ICP_RequiredDurati_0000 255;
BA_ "SPN" SG_ 2563788849 Illumination 1487;
BA_ "SPN" SG_ 2349572135 MessageCounter 3689;
BA_ "SPN" SG_ 2349572135 MessageChecksum 3690;
BA_ "GenSigStartValue" SG_ 2566855217 AmbientTemp 100;
BA_ "SPN" SG_ 2566827568 AirCompressorStatus 1351;
BA_ "SPN" SG_ 2566827568 AirSuspensionSupplyPress 1090;
BA_ "SPN" SG_ 2566827568 AuxEquipmentSupplyPress 1089;
BA_ "SPN" SG_ 2566827568 ServiceBrakeAirPressCircuit2 1088;
BA_ "SPN" SG_ 2566827568 ServiceBrakeAirPressCircuit1 1087;
BA_ "SPN" SG_ 2566827568 ParkingAnd_OrTrailerAirPress 1086;
BA_ "SPN" SG_ 2566827568 PneumaticSupplyPress 46;
BA_ "SPN" SG_ 2362589233 ProhibitAirSuspensionCtrl 3215;
BA_ "SPN" SG_ 2362589233 KneelingCmdRearAxle 1829;
BA_ "SPN" SG_ 2362589233 KneelingCmdFrontAxle 1830;
BA_ "SPN" SG_ 2362589233 DamperStiffnessRqLift_TagAxle 1720;
BA_ "SPN" SG_ 2362589233 DamperStiffnessRqRearAxle 1719;
BA_ "SPN" SG_ 2362589233 DamperStiffnessRqFrontAxle 1718;
BA_ "SPN" SG_ 2362589233 LevelCtrlModeRq 1753;
BA_ "SPN" SG_ 2362589233 NominalLevelRqRearAxle 1750;
BA_ "SPN" SG_ 2362589233 NominalLevelRqFrontAxle 1751;
BA_ "SPN" SG_ 2362589233 KneelingCtrlModeRq 1747;
BA_ "SPN" SG_ 2362589233 KneelingRqRightSide 1748;
BA_ "SPN" SG_ 2362589233 KneelingRqLeftSide 1749;
BA_ "SPN" SG_ 2362589233 AutomaticTractionHelp 2984;
BA_ "SPN" SG_ 2362589233 LiftAxle2PosCmd 1828;
BA_ "SPN" SG_ 2362589233 LiftAxle1PosCmd 1752;
BA_ "SPN" SG_ 2362584871 ProhibitAirSuspensionCtrl 3215;
BA_ "SPN" SG_ 2362584871 KneelingCmdRearAxle 1829;
BA_ "SPN" SG_ 2362584871 KneelingCmdFrontAxle 1830;
BA_ "SPN" SG_ 2362584871 DamperStiffnessRqLift_TagAxle 1720;
BA_ "SPN" SG_ 2362584871 DamperStiffnessRqRearAxle 1719;
BA_ "SPN" SG_ 2362584871 DamperStiffnessRqFrontAxle 1718;
BA_ "SPN" SG_ 2362584871 LevelCtrlModeRq 1753;
BA_ "SPN" SG_ 2362584871 NominalLevelRqRearAxle 1750;
BA_ "SPN" SG_ 2362584871 NominalLevelRqFrontAxle 1751;
BA_ "SPN" SG_ 2362584871 KneelingCtrlModeRq 1747;
BA_ "SPN" SG_ 2362584871 KneelingRqRightSide 1748;
BA_ "SPN" SG_ 2362584871 KneelingRqLeftSide 1749;
BA_ "SPN" SG_ 2362584871 AutomaticTractionHelp 2984;
BA_ "SPN" SG_ 2362584871 LiftAxle2PosCmd 1828;
BA_ "SPN" SG_ 2362584871 LiftAxle1PosCmd 1752;
BA_ "GenSigStartValue" SG_ 2566855552 VCVCCU_V2ICP_PreconDesiredHVAC 3;
BA_ "GenSigStartValue" SG_ 2566855552 VCVCCU_V2ICP_PreconDesired 255;
BA_ "GenSigStartValue" SG_ 2566855552 VCVCCU_V2ICP_AmbientTemperature 127;
BA_ "GenSigStartValue" SG_ 2566850535 ArticSteeringAngle 125;
BA_ "GenSigStartValue" SG_ 2566850535 ArticulationAngle 125;
BA_ "SPN" SG_ 2365479488 SspensionCtrlRefusalInformation 1827;
BA_ "SPN" SG_ 2365479488 SuspensionRemoteCtrl2 1825;
BA_ "SPN" SG_ 2365479488 SuspensionRemoteCtrl1 1826;
BA_ "SPN" SG_ 2365479488 RearAxleInBumperRange 1823;
BA_ "SPN" SG_ 2365479488 FrontAxleInBumperRange 1824;
BA_ "SPN" SG_ 2365479488 DoorRelease 1744;
BA_ "SPN" SG_ 2365479488 VehicleMotionInhibit 1745;
BA_ "SPN" SG_ 2365479488 SecurityDevice 1746;
BA_ "SPN" SG_ 2365479488 LevelCtrlMode 1741;
BA_ "SPN" SG_ 2365479488 KneelingInformation 1742;
BA_ "SPN" SG_ 2365479488 LiftingCtrlModeRearAxle 1756;
BA_ "SPN" SG_ 2365479488 LiftingCtrlModeFrontAxle 1739;
BA_ "SPN" SG_ 2365479488 LoweringCtrlModeRearAxle 1755;
BA_ "SPN" SG_ 2365479488 LoweringCtrlModeFrontAxle 1740;
BA_ "SPN" SG_ 2365479488 AboveNominalLevelRearAxle 1736;
BA_ "SPN" SG_ 2365479488 AboveNominalLevelFrontAxle 1737;
BA_ "SPN" SG_ 2365479488 BelowNominalLevelRearAxle 1754;
BA_ "SPN" SG_ 2365479488 BelowNominalLevelFrontAxle 1738;
BA_ "SPN" SG_ 2365479488 NominalLevelRearAxle 1733;
BA_ "SPN" SG_ 2365479488 NominalLevelFrontAxle 1734;
BA_ "SPN" SG_ 2365479488 LiftAxle2Pos 1822;
BA_ "SPN" SG_ 2365479488 LiftAxle1Pos 1743;
BA_ "SPN" SG_ 2565865967 SrcAddrssOfCtrllngDvcFrBrkCntrl 1481;
BA_ "SPN" SG_ 2565865967 BrakePedalPos 521;
BA_ "SPN" SG_ 2565865967 TrctrMntdTrilerABSWarningSignal 1792;
BA_ "SPN" SG_ 2565865967 TrailerABSStatus 1836;
BA_ "SPN" SG_ 2565865967 HaltBrakeSwitch 2911;
BA_ "SPN" SG_ 2565865967 ATC_ASRInformationSignal 1793;
BA_ "SPN" SG_ 2565865967 ABS_EBSAmberWarningSignal 1438;
BA_ "SPN" SG_ 2565865967 EBSRedWarningSignal 1439;
BA_ "SPN" SG_ 2565865967 ABSFullyOperational 1243;
BA_ "SPN" SG_ 2565865967 EngRetarderSelection 973;
BA_ "SPN" SG_ 2565865967 RemoteAccelEnableSwitch 969;
BA_ "SPN" SG_ 2565865967 EngAuxEngShutdownSwitch 970;
BA_ "SPN" SG_ 2565865967 EngDerateSwitch 971;
BA_ "SPN" SG_ 2565865967 AccelInterlockSwitch 972;
BA_ "SPN" SG_ 2565865967 TractionCtrlOverrideSwitch 1238;
BA_ "SPN" SG_ 2565865967 ASRHillHolderSwitch 577;
BA_ "SPN" SG_ 2565865967 ASROffroadSwitch 576;
BA_ "SPN" SG_ 2565865967 ABSOffroadSwitch 575;
BA_ "SPN" SG_ 2565865967 EBSBrakeSwitch 1121;
BA_ "SPN" SG_ 2565865967 AntiLockBrakingActive 563;
BA_ "SPN" SG_ 2565865967 ASRBrakeCtrlActive 562;
BA_ "SPN" SG_ 2565865967 ASREngCtrlActive 561;
VAL_ 2566853681 CoolantLevelRearDriveLineState 5 "Not Available" 4 "Error" 3 "Red" 2 "Orange" 1 "Green" 0 "Not Active" ;
VAL_ 2566853681 HVBatteryHP2CoolantLevelState 5 "Not Available" 4 "Error" 3 "Red" 2 "Orange" 1 "Green" 0 "Not Active" ;
VAL_ 2566853681 ClimateCoolantLevelState 5 "Not Available" 4 "Error" 3 "Red" 2 "Orange" 1 "Green" 0 "Not Active" ;
VAL_ 2566853681 HVBatteryHP1CoolantLevelState 5 "Not Available" 4 "Error" 3 "Red" 2 "Orange" 1 "Green" 0 "Not Active" ;
VAL_ 2566853681 CoolantLevelDriveLineState 5 "Not Available" 4 "Error" 3 "Red" 2 "Orange" 1 "Green" 0 "Not Active" ;
VAL_ 2147548812 FailureModeIdentifier5 31 "Not available" 19 "Received network data in error" 18 "Below normal (moderatels severe)" 17 "Below normal (least severe)" 16 "Above normal (moderately severe)" 15 "Above normal (least severe)" 14 "Special intstructions" 13 "Out of calibration" 12 "Bad intelligent device" 11 "Root cause not known" 10 "Abnormal rate of change" 9 "Abnormal update rate" 8 "Abnormal frequency" 7 "Mechanical system not responding" 6 "Current above normal" 5 "Current below normal" 4 "Voltage below normal" 3 "Voltage above normal" 2 "Data erratic" 1 "Below normal (most severe)" 0 "Above normal (most severe)" ;
VAL_ 2147548812 FailureModeIdentifier4 31 "Not available" 19 "Received network data in error" 18 "Below normal (moderatels severe)" 17 "Below normal (least severe)" 16 "Above normal (moderately severe)" 15 "Above normal (least severe)" 14 "Special intstructions" 13 "Out of calibration" 12 "Bad intelligent device" 11 "Root cause not known" 10 "Abnormal rate of change" 9 "Abnormal update rate" 8 "Abnormal frequency" 7 "Mechanical system not responding" 6 "Current above normal" 5 "Current below normal" 4 "Voltage below normal" 3 "Voltage above normal" 2 "Data erratic" 1 "Below normal (most severe)" 0 "Above normal (most severe)" ;
VAL_ 2147548812 FailureModeIdentifier3 31 "Not available" 19 "Received network data in error" 18 "Below normal (moderatels severe)" 17 "Below normal (least severe)" 16 "Above normal (moderately severe)" 15 "Above normal (least severe)" 14 "Special intstructions" 13 "Out of calibration" 12 "Bad intelligent device" 11 "Root cause not known" 10 "Abnormal rate of change" 9 "Abnormal update rate" 8 "Abnormal frequency" 7 "Mechanical system not responding" 6 "Current above normal" 5 "Current below normal" 4 "Voltage below normal" 3 "Voltage above normal" 2 "Data erratic" 1 "Below normal (most severe)" 0 "Above normal (most severe)" ;
VAL_ 2147548812 FailureModeIdentifier2 31 "Not available" 19 "Received network data in error" 18 "Below normal (moderatels severe)" 17 "Below normal (least severe)" 16 "Above normal (moderately severe)" 15 "Above normal (least severe)" 14 "Special intstructions" 13 "Out of calibration" 12 "Bad intelligent device" 11 "Root cause not known" 10 "Abnormal rate of change" 9 "Abnormal update rate" 8 "Abnormal frequency" 7 "Mechanical system not responding" 6 "Current above normal" 5 "Current below normal" 4 "Voltage below normal" 3 "Voltage above normal" 2 "Data erratic" 1 "Below normal (most severe)" 0 "Above normal (most severe)" ;
VAL_ 2147548812 FailureModeIdentifier1 31 "Not available" 19 "Received network data in error" 18 "Below normal (moderatels severe)" 17 "Below normal (least severe)" 16 "Above normal (moderately severe)" 15 "Above normal (least severe)" 14 "Special intstructions" 13 "Out of calibration" 12 "Bad intelligent device" 11 "Root cause not known" 10 "Abnormal rate of change" 9 "Abnormal update rate" 8 "Abnormal frequency" 7 "Mechanical system not responding" 6 "Current above normal" 5 "Current below normal" 4 "Voltage below normal" 3 "Voltage above normal" 2 "Data erratic" 1 "Below normal (most severe)" 0 "Above normal (most severe)" ;
VAL_ 2147548812 FlashMalfuncIndicatorLamp 3 "Unavailable / Do Not Flash" 2 "Reserved" 1 "Fast Flash" 0 "Slow Flash" ;
VAL_ 2147548812 FlashRedStopLamp 3 "Unavailable / Do Not Flash" 2 "Reserved" 1 "Fast Flash" 0 "Slow Flash" ;
VAL_ 2147548812 FlashAmberWarningLamp 3 "Unavailable / Do Not Flash" 2 "Reserved" 1 "Fast Flash" 0 "Slow Flash" ;
VAL_ 2147548812 FlashProtectLamp 3 "Unavailable / Do Not Flash" 2 "Reserved" 1 "Fast Flash" 0 "Slow Flash" ;
VAL_ 2147548812 MalfunctionIndicatorLampStatus 3 "Not available" 2 "Reserved" 1 "Lamp on" 0 "Lamp off" ;
VAL_ 2147548812 RedStopLampState 3 "Not available" 2 "Reserved" 1 "Lamp on" 0 "Lamp off" ;
VAL_ 2147548812 AmberWarningLampStatus 3 "Not available" 2 "Reserved" 1 "Lamp on" 0 "Lamp off" ;
VAL_ 2147548812 ProtectLampStatus 3 "Not available" 2 "Reserved" 1 "Lamp on" 0 "Lamp off" ;
VAL_ 2566834829 FailureModeIdentifier5 31 "Not available" 19 "Received network data in error" 18 "Below normal (moderatels severe)" 17 "Below normal (least severe)" 16 "Above normal (moderately severe)" 15 "Above normal (least severe)" 14 "Special intstructions" 13 "Out of calibration" 12 "Bad intelligent device" 11 "Root cause not known" 10 "Abnormal rate of change" 9 "Abnormal update rate" 8 "Abnormal frequency" 7 "Mechanical system not responding" 6 "Current above normal" 5 "Current below normal" 4 "Voltage below normal" 3 "Voltage above normal" 2 "Data erratic" 1 "Below normal (most severe)" 0 "Above normal (most severe)" ;
VAL_ 2566834829 FailureModeIdentifier4 31 "Not available" 19 "Received network data in error" 18 "Below normal (moderatels severe)" 17 "Below normal (least severe)" 16 "Above normal (moderately severe)" 15 "Above normal (least severe)" 14 "Special intstructions" 13 "Out of calibration" 12 "Bad intelligent device" 11 "Root cause not known" 10 "Abnormal rate of change" 9 "Abnormal update rate" 8 "Abnormal frequency" 7 "Mechanical system not responding" 6 "Current above normal" 5 "Current below normal" 4 "Voltage below normal" 3 "Voltage above normal" 2 "Data erratic" 1 "Below normal (most severe)" 0 "Above normal (most severe)" ;
VAL_ 2566834829 FailureModeIdentifier3 31 "Not available" 19 "Received network data in error" 18 "Below normal (moderatels severe)" 17 "Below normal (least severe)" 16 "Above normal (moderately severe)" 15 "Above normal (least severe)" 14 "Special intstructions" 13 "Out of calibration" 12 "Bad intelligent device" 11 "Root cause not known" 10 "Abnormal rate of change" 9 "Abnormal update rate" 8 "Abnormal frequency" 7 "Mechanical system not responding" 6 "Current above normal" 5 "Current below normal" 4 "Voltage below normal" 3 "Voltage above normal" 2 "Data erratic" 1 "Below normal (most severe)" 0 "Above normal (most severe)" ;
VAL_ 2566834829 FailureModeIdentifier2 31 "Not available" 19 "Received network data in error" 18 "Below normal (moderatels severe)" 17 "Below normal (least severe)" 16 "Above normal (moderately severe)" 15 "Above normal (least severe)" 14 "Special intstructions" 13 "Out of calibration" 12 "Bad intelligent device" 11 "Root cause not known" 10 "Abnormal rate of change" 9 "Abnormal update rate" 8 "Abnormal frequency" 7 "Mechanical system not responding" 6 "Current above normal" 5 "Current below normal" 4 "Voltage below normal" 3 "Voltage above normal" 2 "Data erratic" 1 "Below normal (most severe)" 0 "Above normal (most severe)" ;
VAL_ 2566834829 FailureModeIdentifier1 31 "Not available" 19 "Received network data in error" 18 "Below normal (moderatels severe)" 17 "Below normal (least severe)" 16 "Above normal (moderately severe)" 15 "Above normal (least severe)" 14 "Special intstructions" 13 "Out of calibration" 12 "Bad intelligent device" 11 "Root cause not known" 10 "Abnormal rate of change" 9 "Abnormal update rate" 8 "Abnormal frequency" 7 "Mechanical system not responding" 6 "Current above normal" 5 "Current below normal" 4 "Voltage below normal" 3 "Voltage above normal" 2 "Data erratic" 1 "Below normal (most severe)" 0 "Above normal (most severe)" ;
VAL_ 2566834829 FlashMalfuncIndicatorLamp 3 "Unavailable / Do Not Flash" 2 "Reserved" 1 "Fast Flash" 0 "Slow Flash" ;
VAL_ 2566834829 FlashRedStopLamp 3 "Unavailable / Do Not Flash" 2 "Reserved" 1 "Fast Flash" 0 "Slow Flash" ;
VAL_ 2566834829 FlashAmberWarningLamp 3 "Unavailable / Do Not Flash" 2 "Reserved" 1 "Fast Flash" 0 "Slow Flash" ;
VAL_ 2566834829 FlashProtectLamp 3 "Unavailable / Do Not Flash" 2 "Reserved" 1 "Fast Flash" 0 "Slow Flash" ;
VAL_ 2566834829 MalfunctionIndicatorLampStatus 3 "Not available" 2 "Reserved" 1 "Lamp on" 0 "Lamp off" ;
VAL_ 2566834829 RedStopLampState 3 "Not available" 2 "Reserved" 1 "Lamp on" 0 "Lamp off" ;
VAL_ 2566834829 AmberWarningLampStatus 3 "Not available" 2 "Reserved" 1 "Lamp on" 0 "Lamp off" ;
VAL_ 2566834829 ProtectLampStatus 3 "Not available" 2 "Reserved" 1 "Lamp on" 0 "Lamp off" ;
VAL_ 2147483648 FailureModeIdentifier5 31 "Not available" 19 "Received network data in error" 18 "Below normal (moderatels severe)" 17 "Below normal (least severe)" 16 "Above normal (moderately severe)" 15 "Above normal (least severe)" 14 "Special intstructions" 13 "Out of calibration" 12 "Bad intelligent device" 11 "Root cause not known" 10 "Abnormal rate of change" 9 "Abnormal update rate" 8 "Abnormal frequency" 7 "Mechanical system not responding" 6 "Current above normal" 5 "Current below normal" 4 "Voltage below normal" 3 "Voltage above normal" 2 "Data erratic" 1 "Below normal (most severe)" 0 "Above normal (most severe)" ;
VAL_ 2147483648 FailureModeIdentifier4 31 "Not available" 19 "Received network data in error" 18 "Below normal (moderatels severe)" 17 "Below normal (least severe)" 16 "Above normal (moderately severe)" 15 "Above normal (least severe)" 14 "Special intstructions" 13 "Out of calibration" 12 "Bad intelligent device" 11 "Root cause not known" 10 "Abnormal rate of change" 9 "Abnormal update rate" 8 "Abnormal frequency" 7 "Mechanical system not responding" 6 "Current above normal" 5 "Current below normal" 4 "Voltage below normal" 3 "Voltage above normal" 2 "Data erratic" 1 "Below normal (most severe)" 0 "Above normal (most severe)" ;
VAL_ 2147483648 FailureModeIdentifier3 31 "Not available" 19 "Received network data in error" 18 "Below normal (moderatels severe)" 17 "Below normal (least severe)" 16 "Above normal (moderately severe)" 15 "Above normal (least severe)" 14 "Special intstructions" 13 "Out of calibration" 12 "Bad intelligent device" 11 "Root cause not known" 10 "Abnormal rate of change" 9 "Abnormal update rate" 8 "Abnormal frequency" 7 "Mechanical system not responding" 6 "Current above normal" 5 "Current below normal" 4 "Voltage below normal" 3 "Voltage above normal" 2 "Data erratic" 1 "Below normal (most severe)" 0 "Above normal (most severe)" ;
VAL_ 2147483648 FailureModeIdentifier2 31 "Not available" 19 "Received network data in error" 18 "Below normal (moderatels severe)" 17 "Below normal (least severe)" 16 "Above normal (moderately severe)" 15 "Above normal (least severe)" 14 "Special intstructions" 13 "Out of calibration" 12 "Bad intelligent device" 11 "Root cause not known" 10 "Abnormal rate of change" 9 "Abnormal update rate" 8 "Abnormal frequency" 7 "Mechanical system not responding" 6 "Current above normal" 5 "Current below normal" 4 "Voltage below normal" 3 "Voltage above normal" 2 "Data erratic" 1 "Below normal (most severe)" 0 "Above normal (most severe)" ;
VAL_ 2147483648 FailureModeIdentifier1 31 "Not available" 19 "Received network data in error" 18 "Below normal (moderatels severe)" 17 "Below normal (least severe)" 16 "Above normal (moderately severe)" 15 "Above normal (least severe)" 14 "Special intstructions" 13 "Out of calibration" 12 "Bad intelligent device" 11 "Root cause not known" 10 "Abnormal rate of change" 9 "Abnormal update rate" 8 "Abnormal frequency" 7 "Mechanical system not responding" 6 "Current above normal" 5 "Current below normal" 4 "Voltage below normal" 3 "Voltage above normal" 2 "Data erratic" 1 "Below normal (most severe)" 0 "Above normal (most severe)" ;
VAL_ 2147483648 FlashMalfuncIndicatorLamp 3 "Unavailable / Do Not Flash" 2 "Reserved" 1 "Fast Flash" 0 "Slow Flash" ;
VAL_ 2147483648 FlashRedStopLamp 3 "Unavailable / Do Not Flash" 2 "Reserved" 1 "Fast Flash" 0 "Slow Flash" ;
VAL_ 2147483648 FlashAmberWarningLamp 3 "Unavailable / Do Not Flash" 2 "Reserved" 1 "Fast Flash" 0 "Slow Flash" ;
VAL_ 2147483648 FlashProtectLamp 3 "Unavailable / Do Not Flash" 2 "Reserved" 1 "Fast Flash" 0 "Slow Flash" ;
VAL_ 2147483648 MalfunctionIndicatorLampStatus 3 "Not available" 2 "Reserved" 1 "Lamp on" 0 "Lamp off" ;
VAL_ 2147483648 RedStopLampState 3 "Not available" 2 "Reserved" 1 "Lamp on" 0 "Lamp off" ;
VAL_ 2147483648 AmberWarningLampStatus 3 "Not available" 2 "Reserved" 1 "Lamp on" 0 "Lamp off" ;
VAL_ 2147483648 ProtectLampStatus 3 "Not available" 2 "Reserved" 1 "Lamp on" 0 "Lamp off" ;
VAL_ 2566834827 FailureModeIdentifier5 31 "Not available" 19 "Received network data in error" 18 "Below normal (moderatels severe)" 17 "Below normal (least severe)" 16 "Above normal (moderately severe)" 15 "Above normal (least severe)" 14 "Special intstructions" 13 "Out of calibration" 12 "Bad intelligent device" 11 "Root cause not known" 10 "Abnormal rate of change" 9 "Abnormal update rate" 8 "Abnormal frequency" 7 "Mechanical system not responding" 6 "Current above normal" 5 "Current below normal" 4 "Voltage below normal" 3 "Voltage above normal" 2 "Data erratic" 1 "Below normal (most severe)" 0 "Above normal (most severe)" ;
VAL_ 2566834827 FailureModeIdentifier4 31 "Not available" 19 "Received network data in error" 18 "Below normal (moderatels severe)" 17 "Below normal (least severe)" 16 "Above normal (moderately severe)" 15 "Above normal (least severe)" 14 "Special intstructions" 13 "Out of calibration" 12 "Bad intelligent device" 11 "Root cause not known" 10 "Abnormal rate of change" 9 "Abnormal update rate" 8 "Abnormal frequency" 7 "Mechanical system not responding" 6 "Current above normal" 5 "Current below normal" 4 "Voltage below normal" 3 "Voltage above normal" 2 "Data erratic" 1 "Below normal (most severe)" 0 "Above normal (most severe)" ;
VAL_ 2566834827 FailureModeIdentifier3 31 "Not available" 19 "Received network data in error" 18 "Below normal (moderatels severe)" 17 "Below normal (least severe)" 16 "Above normal (moderately severe)" 15 "Above normal (least severe)" 14 "Special intstructions" 13 "Out of calibration" 12 "Bad intelligent device" 11 "Root cause not known" 10 "Abnormal rate of change" 9 "Abnormal update rate" 8 "Abnormal frequency" 7 "Mechanical system not responding" 6 "Current above normal" 5 "Current below normal" 4 "Voltage below normal" 3 "Voltage above normal" 2 "Data erratic" 1 "Below normal (most severe)" 0 "Above normal (most severe)" ;
VAL_ 2566834827 FailureModeIdentifier2 31 "Not available" 19 "Received network data in error" 18 "Below normal (moderatels severe)" 17 "Below normal (least severe)" 16 "Above normal (moderately severe)" 15 "Above normal (least severe)" 14 "Special intstructions" 13 "Out of calibration" 12 "Bad intelligent device" 11 "Root cause not known" 10 "Abnormal rate of change" 9 "Abnormal update rate" 8 "Abnormal frequency" 7 "Mechanical system not responding" 6 "Current above normal" 5 "Current below normal" 4 "Voltage below normal" 3 "Voltage above normal" 2 "Data erratic" 1 "Below normal (most severe)" 0 "Above normal (most severe)" ;
VAL_ 2566834827 FailureModeIdentifier1 31 "Not available" 19 "Received network data in error" 18 "Below normal (moderatels severe)" 17 "Below normal (least severe)" 16 "Above normal (moderately severe)" 15 "Above normal (least severe)" 14 "Special intstructions" 13 "Out of calibration" 12 "Bad intelligent device" 11 "Root cause not known" 10 "Abnormal rate of change" 9 "Abnormal update rate" 8 "Abnormal frequency" 7 "Mechanical system not responding" 6 "Current above normal" 5 "Current below normal" 4 "Voltage below normal" 3 "Voltage above normal" 2 "Data erratic" 1 "Below normal (most severe)" 0 "Above normal (most severe)" ;
VAL_ 2566834827 FlashMalfuncIndicatorLamp 3 "Unavailable / Do Not Flash" 2 "Reserved" 1 "Fast Flash" 0 "Slow Flash" ;
VAL_ 2566834827 FlashRedStopLamp 3 "Unavailable / Do Not Flash" 2 "Reserved" 1 "Fast Flash" 0 "Slow Flash" ;
VAL_ 2566834827 FlashAmberWarningLamp 3 "Unavailable / Do Not Flash" 2 "Reserved" 1 "Fast Flash" 0 "Slow Flash" ;
VAL_ 2566834827 FlashProtectLamp 3 "Unavailable / Do Not Flash" 2 "Reserved" 1 "Fast Flash" 0 "Slow Flash" ;
VAL_ 2566834827 MalfunctionIndicatorLampStatus 3 "Not available" 2 "Reserved" 1 "Lamp on" 0 "Lamp off" ;
VAL_ 2566834827 RedStopLampState 3 "Not available" 2 "Reserved" 1 "Lamp on" 0 "Lamp off" ;
VAL_ 2566834827 AmberWarningLampStatus 3 "Not available" 2 "Reserved" 1 "Lamp on" 0 "Lamp off" ;
VAL_ 2566834827 ProtectLampStatus 3 "Not available" 2 "Reserved" 1 "Lamp on" 0 "Lamp off" ;
VAL_ 2566834826 FailureModeIdentifier5 31 "Not available" 19 "Received network data in error" 18 "Below normal (moderatels severe)" 17 "Below normal (least severe)" 16 "Above normal (moderately severe)" 15 "Above normal (least severe)" 14 "Special intstructions" 13 "Out of calibration" 12 "Bad intelligent device" 11 "Root cause not known" 10 "Abnormal rate of change" 9 "Abnormal update rate" 8 "Abnormal frequency" 7 "Mechanical system not responding" 6 "Current above normal" 5 "Current below normal" 4 "Voltage below normal" 3 "Voltage above normal" 2 "Data erratic" 1 "Below normal (most severe)" 0 "Above normal (most severe)" ;
VAL_ 2566834826 FailureModeIdentifier4 31 "Not available" 19 "Received network data in error" 18 "Below normal (moderatels severe)" 17 "Below normal (least severe)" 16 "Above normal (moderately severe)" 15 "Above normal (least severe)" 14 "Special intstructions" 13 "Out of calibration" 12 "Bad intelligent device" 11 "Root cause not known" 10 "Abnormal rate of change" 9 "Abnormal update rate" 8 "Abnormal frequency" 7 "Mechanical system not responding" 6 "Current above normal" 5 "Current below normal" 4 "Voltage below normal" 3 "Voltage above normal" 2 "Data erratic" 1 "Below normal (most severe)" 0 "Above normal (most severe)" ;
VAL_ 2566834826 FailureModeIdentifier3 31 "Not available" 19 "Received network data in error" 18 "Below normal (moderatels severe)" 17 "Below normal (least severe)" 16 "Above normal (moderately severe)" 15 "Above normal (least severe)" 14 "Special intstructions" 13 "Out of calibration" 12 "Bad intelligent device" 11 "Root cause not known" 10 "Abnormal rate of change" 9 "Abnormal update rate" 8 "Abnormal frequency" 7 "Mechanical system not responding" 6 "Current above normal" 5 "Current below normal" 4 "Voltage below normal" 3 "Voltage above normal" 2 "Data erratic" 1 "Below normal (most severe)" 0 "Above normal (most severe)" ;
VAL_ 2566834826 FailureModeIdentifier2 31 "Not available" 19 "Received network data in error" 18 "Below normal (moderatels severe)" 17 "Below normal (least severe)" 16 "Above normal (moderately severe)" 15 "Above normal (least severe)" 14 "Special intstructions" 13 "Out of calibration" 12 "Bad intelligent device" 11 "Root cause not known" 10 "Abnormal rate of change" 9 "Abnormal update rate" 8 "Abnormal frequency" 7 "Mechanical system not responding" 6 "Current above normal" 5 "Current below normal" 4 "Voltage below normal" 3 "Voltage above normal" 2 "Data erratic" 1 "Below normal (most severe)" 0 "Above normal (most severe)" ;
VAL_ 2566834826 FailureModeIdentifier1 31 "Not available" 19 "Received network data in error" 18 "Below normal (moderatels severe)" 17 "Below normal (least severe)" 16 "Above normal (moderately severe)" 15 "Above normal (least severe)" 14 "Special intstructions" 13 "Out of calibration" 12 "Bad intelligent device" 11 "Root cause not known" 10 "Abnormal rate of change" 9 "Abnormal update rate" 8 "Abnormal frequency" 7 "Mechanical system not responding" 6 "Current above normal" 5 "Current below normal" 4 "Voltage below normal" 3 "Voltage above normal" 2 "Data erratic" 1 "Below normal (most severe)" 0 "Above normal (most severe)" ;
VAL_ 2566834826 FlashMalfuncIndicatorLamp 3 "Unavailable / Do Not Flash" 2 "Reserved" 1 "Fast Flash" 0 "Slow Flash" ;
VAL_ 2566834826 FlashRedStopLamp 3 "Unavailable / Do Not Flash" 2 "Reserved" 1 "Fast Flash" 0 "Slow Flash" ;
VAL_ 2566834826 FlashAmberWarningLamp 3 "Unavailable / Do Not Flash" 2 "Reserved" 1 "Fast Flash" 0 "Slow Flash" ;
VAL_ 2566834826 FlashProtectLamp 3 "Unavailable / Do Not Flash" 2 "Reserved" 1 "Fast Flash" 0 "Slow Flash" ;
VAL_ 2566834826 MalfunctionIndicatorLampStatus 3 "Not available" 2 "Reserved" 1 "Lamp on" 0 "Lamp off" ;
VAL_ 2566834826 RedStopLampState 3 "Not available" 2 "Reserved" 1 "Lamp on" 0 "Lamp off" ;
VAL_ 2566834826 AmberWarningLampStatus 3 "Not available" 2 "Reserved" 1 "Lamp on" 0 "Lamp off" ;
VAL_ 2566834826 ProtectLampStatus 3 "Not available" 2 "Reserved" 1 "Lamp on" 0 "Lamp off" ;
VAL_ 2566909991 ParkBrakeWorkshopMode 3 "Not Available" 2 "Error" 1 "Active" 0 "Inactive" ;
VAL_ 2566909991 ParkBrakeWarningState 3 "Not Available" 2 "Error" 1 "Active" 0 "Inactive" ;
VAL_ 2566909991 ParkBrakeEmergencyMode 3 "Not Available" 2 "Error" 1 "Active" 0 "Inactive" ;
VAL_ 2566909991 LVBatteryChargingError 1 "On" 0 "Off" ;
VAL_ 2566909991 SpeedLimiterIndication 7 "Not available" 6 "Error" 5 "Downhill speed limiter" 4 "Veh speed limiter overruled ind" 3 "Veh speed limiter active ind" 2 "GEO speed limiter overruled ind" 1 "GEO speed limiter active ind" 0 "Inactive" ;
VAL_ 2566909991 CruiseControlActiveindication 3 "Not Available" 2 "Active" 1 "Inactive" 0 "Disabled" ;
VAL_ 2566834920 FailureModeIdentifier5 31 "Not available" 19 "Received network data in error" 18 "Below normal (moderatels severe)" 17 "Below normal (least severe)" 16 "Above normal (moderately severe)" 15 "Above normal (least severe)" 14 "Special intstructions" 13 "Out of calibration" 12 "Bad intelligent device" 11 "Root cause not known" 10 "Abnormal rate of change" 9 "Abnormal update rate" 8 "Abnormal frequency" 7 "Mechanical system not responding" 6 "Current above normal" 5 "Current below normal" 4 "Voltage below normal" 3 "Voltage above normal" 2 "Data erratic" 1 "Below normal (most severe)" 0 "Above normal (most severe)" ;
VAL_ 2566834920 FailureModeIdentifier4 31 "Not available" 19 "Received network data in error" 18 "Below normal (moderatels severe)" 17 "Below normal (least severe)" 16 "Above normal (moderately severe)" 15 "Above normal (least severe)" 14 "Special intstructions" 13 "Out of calibration" 12 "Bad intelligent device" 11 "Root cause not known" 10 "Abnormal rate of change" 9 "Abnormal update rate" 8 "Abnormal frequency" 7 "Mechanical system not responding" 6 "Current above normal" 5 "Current below normal" 4 "Voltage below normal" 3 "Voltage above normal" 2 "Data erratic" 1 "Below normal (most severe)" 0 "Above normal (most severe)" ;
VAL_ 2566834920 FailureModeIdentifier3 31 "Not available" 19 "Received network data in error" 18 "Below normal (moderatels severe)" 17 "Below normal (least severe)" 16 "Above normal (moderately severe)" 15 "Above normal (least severe)" 14 "Special intstructions" 13 "Out of calibration" 12 "Bad intelligent device" 11 "Root cause not known" 10 "Abnormal rate of change" 9 "Abnormal update rate" 8 "Abnormal frequency" 7 "Mechanical system not responding" 6 "Current above normal" 5 "Current below normal" 4 "Voltage below normal" 3 "Voltage above normal" 2 "Data erratic" 1 "Below normal (most severe)" 0 "Above normal (most severe)" ;
VAL_ 2566834920 FailureModeIdentifier2 31 "Not available" 19 "Received network data in error" 18 "Below normal (moderatels severe)" 17 "Below normal (least severe)" 16 "Above normal (moderately severe)" 15 "Above normal (least severe)" 14 "Special intstructions" 13 "Out of calibration" 12 "Bad intelligent device" 11 "Root cause not known" 10 "Abnormal rate of change" 9 "Abnormal update rate" 8 "Abnormal frequency" 7 "Mechanical system not responding" 6 "Current above normal" 5 "Current below normal" 4 "Voltage below normal" 3 "Voltage above normal" 2 "Data erratic" 1 "Below normal (most severe)" 0 "Above normal (most severe)" ;
VAL_ 2566834920 FailureModeIdentifier1 31 "Not available" 19 "Received network data in error" 18 "Below normal (moderatels severe)" 17 "Below normal (least severe)" 16 "Above normal (moderately severe)" 15 "Above normal (least severe)" 14 "Special intstructions" 13 "Out of calibration" 12 "Bad intelligent device" 11 "Root cause not known" 10 "Abnormal rate of change" 9 "Abnormal update rate" 8 "Abnormal frequency" 7 "Mechanical system not responding" 6 "Current above normal" 5 "Current below normal" 4 "Voltage below normal" 3 "Voltage above normal" 2 "Data erratic" 1 "Below normal (most severe)" 0 "Above normal (most severe)" ;
VAL_ 2566834920 FlashMalfuncIndicatorLamp 3 "Unavailable / Do Not Flash" 2 "Reserved" 1 "Fast Flash" 0 "Slow Flash" ;
VAL_ 2566834920 FlashRedStopLamp 3 "Unavailable / Do Not Flash" 2 "Reserved" 1 "Fast Flash" 0 "Slow Flash" ;
VAL_ 2566834920 FlashAmberWarningLamp 3 "Unavailable / Do Not Flash" 2 "Reserved" 1 "Fast Flash" 0 "Slow Flash" ;
VAL_ 2566834920 FlashProtectLamp 3 "Unavailable / Do Not Flash" 2 "Reserved" 1 "Fast Flash" 0 "Slow Flash" ;
VAL_ 2566834920 MalfunctionIndicatorLampStatus 3 "Not available" 2 "Reserved" 1 "Lamp on" 0 "Lamp off" ;
VAL_ 2566834920 RedStopLampState 3 "Not available" 2 "Reserved" 1 "Lamp on" 0 "Lamp off" ;
VAL_ 2566834920 AmberWarningLampStatus 3 "Not available" 2 "Reserved" 1 "Lamp on" 0 "Lamp off" ;
VAL_ 2566834920 ProtectLampStatus 3 "Not available" 2 "Reserved" 1 "Lamp on" 0 "Lamp off" ;
VAL_ 2566834752 FailureModeIdentifier5 31 "Not available" 19 "Received network data in error" 18 "Below normal (moderatels severe)" 17 "Below normal (least severe)" 16 "Above normal (moderately severe)" 15 "Above normal (least severe)" 14 "Special intstructions" 13 "Out of calibration" 12 "Bad intelligent device" 11 "Root cause not known" 10 "Abnormal rate of change" 9 "Abnormal update rate" 8 "Abnormal frequency" 7 "Mechanical system not responding" 6 "Current above normal" 5 "Current below normal" 4 "Voltage below normal" 3 "Voltage above normal" 2 "Data erratic" 1 "Below normal (most severe)" 0 "Above normal (most severe)" ;
VAL_ 2566834752 FailureModeIdentifier4 31 "Not available" 19 "Received network data in error" 18 "Below normal (moderatels severe)" 17 "Below normal (least severe)" 16 "Above normal (moderately severe)" 15 "Above normal (least severe)" 14 "Special intstructions" 13 "Out of calibration" 12 "Bad intelligent device" 11 "Root cause not known" 10 "Abnormal rate of change" 9 "Abnormal update rate" 8 "Abnormal frequency" 7 "Mechanical system not responding" 6 "Current above normal" 5 "Current below normal" 4 "Voltage below normal" 3 "Voltage above normal" 2 "Data erratic" 1 "Below normal (most severe)" 0 "Above normal (most severe)" ;
VAL_ 2566834752 FailureModeIdentifier3 31 "Not available" 19 "Received network data in error" 18 "Below normal (moderatels severe)" 17 "Below normal (least severe)" 16 "Above normal (moderately severe)" 15 "Above normal (least severe)" 14 "Special intstructions" 13 "Out of calibration" 12 "Bad intelligent device" 11 "Root cause not known" 10 "Abnormal rate of change" 9 "Abnormal update rate" 8 "Abnormal frequency" 7 "Mechanical system not responding" 6 "Current above normal" 5 "Current below normal" 4 "Voltage below normal" 3 "Voltage above normal" 2 "Data erratic" 1 "Below normal (most severe)" 0 "Above normal (most severe)" ;
VAL_ 2566834752 FailureModeIdentifier2 31 "Not available" 19 "Received network data in error" 18 "Below normal (moderatels severe)" 17 "Below normal (least severe)" 16 "Above normal (moderately severe)" 15 "Above normal (least severe)" 14 "Special intstructions" 13 "Out of calibration" 12 "Bad intelligent device" 11 "Root cause not known" 10 "Abnormal rate of change" 9 "Abnormal update rate" 8 "Abnormal frequency" 7 "Mechanical system not responding" 6 "Current above normal" 5 "Current below normal" 4 "Voltage below normal" 3 "Voltage above normal" 2 "Data erratic" 1 "Below normal (most severe)" 0 "Above normal (most severe)" ;
VAL_ 2566834752 FailureModeIdentifier1 31 "Not available" 19 "Received network data in error" 18 "Below normal (moderatels severe)" 17 "Below normal (least severe)" 16 "Above normal (moderately severe)" 15 "Above normal (least severe)" 14 "Special intstructions" 13 "Out of calibration" 12 "Bad intelligent device" 11 "Root cause not known" 10 "Abnormal rate of change" 9 "Abnormal update rate" 8 "Abnormal frequency" 7 "Mechanical system not responding" 6 "Current above normal" 5 "Current below normal" 4 "Voltage below normal" 3 "Voltage above normal" 2 "Data erratic" 1 "Below normal (most severe)" 0 "Above normal (most severe)" ;
VAL_ 2566834752 FlashMalfuncIndicatorLamp 3 "Unavailable / Do Not Flash" 2 "Reserved" 1 "Fast Flash" 0 "Slow Flash" ;
VAL_ 2566834752 FlashRedStopLamp 3 "Unavailable / Do Not Flash" 2 "Reserved" 1 "Fast Flash" 0 "Slow Flash" ;
VAL_ 2566834752 FlashAmberWarningLamp 3 "Unavailable / Do Not Flash" 2 "Reserved" 1 "Fast Flash" 0 "Slow Flash" ;
VAL_ 2566834752 FlashProtectLamp 3 "Unavailable / Do Not Flash" 2 "Reserved" 1 "Fast Flash" 0 "Slow Flash" ;
VAL_ 2566834752 MalfunctionIndicatorLampStatus 3 "Not available" 2 "Reserved" 1 "Lamp on" 0 "Lamp off" ;
VAL_ 2566834752 RedStopLampState 3 "Not available" 2 "Reserved" 1 "Lamp on" 0 "Lamp off" ;
VAL_ 2566834752 AmberWarningLampStatus 3 "Not available" 2 "Reserved" 1 "Lamp on" 0 "Lamp off" ;
VAL_ 2566834752 ProtectLampStatus 3 "Not available" 2 "Reserved" 1 "Lamp on" 0 "Lamp off" ;
VAL_ 2566834881 FailureModeIdentifier5 31 "Not available" 19 "Received network data in error" 18 "Below normal (moderatels severe)" 17 "Below normal (least severe)" 16 "Above normal (moderately severe)" 15 "Above normal (least severe)" 14 "Special intstructions" 13 "Out of calibration" 12 "Bad intelligent device" 11 "Root cause not known" 10 "Abnormal rate of change" 9 "Abnormal update rate" 8 "Abnormal frequency" 7 "Mechanical system not responding" 6 "Current above normal" 5 "Current below normal" 4 "Voltage below normal" 3 "Voltage above normal" 2 "Data erratic" 1 "Below normal (most severe)" 0 "Above normal (most severe)" ;
VAL_ 2566834881 FailureModeIdentifier4 31 "Not available" 19 "Received network data in error" 18 "Below normal (moderatels severe)" 17 "Below normal (least severe)" 16 "Above normal (moderately severe)" 15 "Above normal (least severe)" 14 "Special intstructions" 13 "Out of calibration" 12 "Bad intelligent device" 11 "Root cause not known" 10 "Abnormal rate of change" 9 "Abnormal update rate" 8 "Abnormal frequency" 7 "Mechanical system not responding" 6 "Current above normal" 5 "Current below normal" 4 "Voltage below normal" 3 "Voltage above normal" 2 "Data erratic" 1 "Below normal (most severe)" 0 "Above normal (most severe)" ;
VAL_ 2566834881 FailureModeIdentifier3 31 "Not available" 19 "Received network data in error" 18 "Below normal (moderatels severe)" 17 "Below normal (least severe)" 16 "Above normal (moderately severe)" 15 "Above normal (least severe)" 14 "Special intstructions" 13 "Out of calibration" 12 "Bad intelligent device" 11 "Root cause not known" 10 "Abnormal rate of change" 9 "Abnormal update rate" 8 "Abnormal frequency" 7 "Mechanical system not responding" 6 "Current above normal" 5 "Current below normal" 4 "Voltage below normal" 3 "Voltage above normal" 2 "Data erratic" 1 "Below normal (most severe)" 0 "Above normal (most severe)" ;
VAL_ 2566834881 FailureModeIdentifier2 31 "Not available" 19 "Received network data in error" 18 "Below normal (moderatels severe)" 17 "Below normal (least severe)" 16 "Above normal (moderately severe)" 15 "Above normal (least severe)" 14 "Special intstructions" 13 "Out of calibration" 12 "Bad intelligent device" 11 "Root cause not known" 10 "Abnormal rate of change" 9 "Abnormal update rate" 8 "Abnormal frequency" 7 "Mechanical system not responding" 6 "Current above normal" 5 "Current below normal" 4 "Voltage below normal" 3 "Voltage above normal" 2 "Data erratic" 1 "Below normal (most severe)" 0 "Above normal (most severe)" ;
VAL_ 2566834881 FailureModeIdentifier1 31 "Not available" 19 "Received network data in error" 18 "Below normal (moderatels severe)" 17 "Below normal (least severe)" 16 "Above normal (moderately severe)" 15 "Above normal (least severe)" 14 "Special intstructions" 13 "Out of calibration" 12 "Bad intelligent device" 11 "Root cause not known" 10 "Abnormal rate of change" 9 "Abnormal update rate" 8 "Abnormal frequency" 7 "Mechanical system not responding" 6 "Current above normal" 5 "Current below normal" 4 "Voltage below normal" 3 "Voltage above normal" 2 "Data erratic" 1 "Below normal (most severe)" 0 "Above normal (most severe)" ;
VAL_ 2566834881 FlashMalfuncIndicatorLamp 3 "Unavailable / Do Not Flash" 2 "Reserved" 1 "Fast Flash" 0 "Slow Flash" ;
VAL_ 2566834881 FlashRedStopLamp 3 "Unavailable / Do Not Flash" 2 "Reserved" 1 "Fast Flash" 0 "Slow Flash" ;
VAL_ 2566834881 FlashAmberWarningLamp 3 "Unavailable / Do Not Flash" 2 "Reserved" 1 "Fast Flash" 0 "Slow Flash" ;
VAL_ 2566834881 FlashProtectLamp 3 "Unavailable / Do Not Flash" 2 "Reserved" 1 "Fast Flash" 0 "Slow Flash" ;
VAL_ 2566834881 MalfunctionIndicatorLampStatus 3 "Not available" 2 "Reserved" 1 "Lamp on" 0 "Lamp off" ;
VAL_ 2566834881 RedStopLampState 3 "Not available" 2 "Reserved" 1 "Lamp on" 0 "Lamp off" ;
VAL_ 2566834881 AmberWarningLampStatus 3 "Not available" 2 "Reserved" 1 "Lamp on" 0 "Lamp off" ;
VAL_ 2566834881 ProtectLampStatus 3 "Not available" 2 "Reserved" 1 "Lamp on" 0 "Lamp off" ;
VAL_ 2566834880 FailureModeIdentifier5 31 "Not available" 19 "Received network data in error" 18 "Below normal (moderatels severe)" 17 "Below normal (least severe)" 16 "Above normal (moderately severe)" 15 "Above normal (least severe)" 14 "Special intstructions" 13 "Out of calibration" 12 "Bad intelligent device" 11 "Root cause not known" 10 "Abnormal rate of change" 9 "Abnormal update rate" 8 "Abnormal frequency" 7 "Mechanical system not responding" 6 "Current above normal" 5 "Current below normal" 4 "Voltage below normal" 3 "Voltage above normal" 2 "Data erratic" 1 "Below normal (most severe)" 0 "Above normal (most severe)" ;
VAL_ 2566834880 FailureModeIdentifier4 31 "Not available" 19 "Received network data in error" 18 "Below normal (moderatels severe)" 17 "Below normal (least severe)" 16 "Above normal (moderately severe)" 15 "Above normal (least severe)" 14 "Special intstructions" 13 "Out of calibration" 12 "Bad intelligent device" 11 "Root cause not known" 10 "Abnormal rate of change" 9 "Abnormal update rate" 8 "Abnormal frequency" 7 "Mechanical system not responding" 6 "Current above normal" 5 "Current below normal" 4 "Voltage below normal" 3 "Voltage above normal" 2 "Data erratic" 1 "Below normal (most severe)" 0 "Above normal (most severe)" ;
VAL_ 2566834880 FailureModeIdentifier3 31 "Not available" 19 "Received network data in error" 18 "Below normal (moderatels severe)" 17 "Below normal (least severe)" 16 "Above normal (moderately severe)" 15 "Above normal (least severe)" 14 "Special intstructions" 13 "Out of calibration" 12 "Bad intelligent device" 11 "Root cause not known" 10 "Abnormal rate of change" 9 "Abnormal update rate" 8 "Abnormal frequency" 7 "Mechanical system not responding" 6 "Current above normal" 5 "Current below normal" 4 "Voltage below normal" 3 "Voltage above normal" 2 "Data erratic" 1 "Below normal (most severe)" 0 "Above normal (most severe)" ;
VAL_ 2566834880 FailureModeIdentifier2 31 "Not available" 19 "Received network data in error" 18 "Below normal (moderatels severe)" 17 "Below normal (least severe)" 16 "Above normal (moderately severe)" 15 "Above normal (least severe)" 14 "Special intstructions" 13 "Out of calibration" 12 "Bad intelligent device" 11 "Root cause not known" 10 "Abnormal rate of change" 9 "Abnormal update rate" 8 "Abnormal frequency" 7 "Mechanical system not responding" 6 "Current above normal" 5 "Current below normal" 4 "Voltage below normal" 3 "Voltage above normal" 2 "Data erratic" 1 "Below normal (most severe)" 0 "Above normal (most severe)" ;
VAL_ 2566834880 FailureModeIdentifier1 31 "Not available" 19 "Received network data in error" 18 "Below normal (moderatels severe)" 17 "Below normal (least severe)" 16 "Above normal (moderately severe)" 15 "Above normal (least severe)" 14 "Special intstructions" 13 "Out of calibration" 12 "Bad intelligent device" 11 "Root cause not known" 10 "Abnormal rate of change" 9 "Abnormal update rate" 8 "Abnormal frequency" 7 "Mechanical system not responding" 6 "Current above normal" 5 "Current below normal" 4 "Voltage below normal" 3 "Voltage above normal" 2 "Data erratic" 1 "Below normal (most severe)" 0 "Above normal (most severe)" ;
VAL_ 2566834880 FlashMalfuncIndicatorLamp 3 "Unavailable / Do Not Flash" 2 "Reserved" 1 "Fast Flash" 0 "Slow Flash" ;
VAL_ 2566834880 FlashRedStopLamp 3 "Unavailable / Do Not Flash" 2 "Reserved" 1 "Fast Flash" 0 "Slow Flash" ;
VAL_ 2566834880 FlashAmberWarningLamp 3 "Unavailable / Do Not Flash" 2 "Reserved" 1 "Fast Flash" 0 "Slow Flash" ;
VAL_ 2566834880 FlashProtectLamp 3 "Unavailable / Do Not Flash" 2 "Reserved" 1 "Fast Flash" 0 "Slow Flash" ;
VAL_ 2566834880 MalfunctionIndicatorLampStatus 3 "Not available" 2 "Reserved" 1 "Lamp on" 0 "Lamp off" ;
VAL_ 2566834880 RedStopLampState 3 "Not available" 2 "Reserved" 1 "Lamp on" 0 "Lamp off" ;
VAL_ 2566834880 AmberWarningLampStatus 3 "Not available" 2 "Reserved" 1 "Lamp on" 0 "Lamp off" ;
VAL_ 2566834880 ProtectLampStatus 3 "Not available" 2 "Reserved" 1 "Lamp on" 0 "Lamp off" ;
VAL_ 2566834848 FailureModeIdentifier5 31 "Not available" 19 "Received network data in error" 18 "Below normal (moderatels severe)" 17 "Below normal (least severe)" 16 "Above normal (moderately severe)" 15 "Above normal (least severe)" 14 "Special intstructions" 13 "Out of calibration" 12 "Bad intelligent device" 11 "Root cause not known" 10 "Abnormal rate of change" 9 "Abnormal update rate" 8 "Abnormal frequency" 7 "Mechanical system not responding" 6 "Current above normal" 5 "Current below normal" 4 "Voltage below normal" 3 "Voltage above normal" 2 "Data erratic" 1 "Below normal (most severe)" 0 "Above normal (most severe)" ;
VAL_ 2566834848 FailureModeIdentifier4 31 "Not available" 19 "Received network data in error" 18 "Below normal (moderatels severe)" 17 "Below normal (least severe)" 16 "Above normal (moderately severe)" 15 "Above normal (least severe)" 14 "Special intstructions" 13 "Out of calibration" 12 "Bad intelligent device" 11 "Root cause not known" 10 "Abnormal rate of change" 9 "Abnormal update rate" 8 "Abnormal frequency" 7 "Mechanical system not responding" 6 "Current above normal" 5 "Current below normal" 4 "Voltage below normal" 3 "Voltage above normal" 2 "Data erratic" 1 "Below normal (most severe)" 0 "Above normal (most severe)" ;
VAL_ 2566834848 FailureModeIdentifier3 31 "Not available" 19 "Received network data in error" 18 "Below normal (moderatels severe)" 17 "Below normal (least severe)" 16 "Above normal (moderately severe)" 15 "Above normal (least severe)" 14 "Special intstructions" 13 "Out of calibration" 12 "Bad intelligent device" 11 "Root cause not known" 10 "Abnormal rate of change" 9 "Abnormal update rate" 8 "Abnormal frequency" 7 "Mechanical system not responding" 6 "Current above normal" 5 "Current below normal" 4 "Voltage below normal" 3 "Voltage above normal" 2 "Data erratic" 1 "Below normal (most severe)" 0 "Above normal (most severe)" ;
VAL_ 2566834848 FailureModeIdentifier2 31 "Not available" 19 "Received network data in error" 18 "Below normal (moderatels severe)" 17 "Below normal (least severe)" 16 "Above normal (moderately severe)" 15 "Above normal (least severe)" 14 "Special intstructions" 13 "Out of calibration" 12 "Bad intelligent device" 11 "Root cause not known" 10 "Abnormal rate of change" 9 "Abnormal update rate" 8 "Abnormal frequency" 7 "Mechanical system not responding" 6 "Current above normal" 5 "Current below normal" 4 "Voltage below normal" 3 "Voltage above normal" 2 "Data erratic" 1 "Below normal (most severe)" 0 "Above normal (most severe)" ;
VAL_ 2566834848 FailureModeIdentifier1 31 "Not available" 19 "Received network data in error" 18 "Below normal (moderatels severe)" 17 "Below normal (least severe)" 16 "Above normal (moderately severe)" 15 "Above normal (least severe)" 14 "Special intstructions" 13 "Out of calibration" 12 "Bad intelligent device" 11 "Root cause not known" 10 "Abnormal rate of change" 9 "Abnormal update rate" 8 "Abnormal frequency" 7 "Mechanical system not responding" 6 "Current above normal" 5 "Current below normal" 4 "Voltage below normal" 3 "Voltage above normal" 2 "Data erratic" 1 "Below normal (most severe)" 0 "Above normal (most severe)" ;
VAL_ 2566834848 FlashMalfuncIndicatorLamp 3 "Unavailable / Do Not Flash" 2 "Reserved" 1 "Fast Flash" 0 "Slow Flash" ;
VAL_ 2566834848 FlashRedStopLamp 3 "Unavailable / Do Not Flash" 2 "Reserved" 1 "Fast Flash" 0 "Slow Flash" ;
VAL_ 2566834848 FlashAmberWarningLamp 3 "Unavailable / Do Not Flash" 2 "Reserved" 1 "Fast Flash" 0 "Slow Flash" ;
VAL_ 2566834848 FlashProtectLamp 3 "Unavailable / Do Not Flash" 2 "Reserved" 1 "Fast Flash" 0 "Slow Flash" ;
VAL_ 2566834848 MalfunctionIndicatorLampStatus 3 "Not available" 2 "Reserved" 1 "Lamp on" 0 "Lamp off" ;
VAL_ 2566834848 RedStopLampState 3 "Not available" 2 "Reserved" 1 "Lamp on" 0 "Lamp off" ;
VAL_ 2566834848 AmberWarningLampStatus 3 "Not available" 2 "Reserved" 1 "Lamp on" 0 "Lamp off" ;
VAL_ 2566834848 ProtectLampStatus 3 "Not available" 2 "Reserved" 1 "Lamp on" 0 "Lamp off" ;
VAL_ 2348820455 ControlPurpose 5 "TemporaryPowerTrainControl" 4 "EngineProtection" 3 "RoadSpeedGovernor" 2 "PTOGovernor" 1 "CruiseControl" 0 "AcceleratorPedal" ;
VAL_ 2348820455 TransmissionRate 7 "UseStandardRate" 6 "25ms" 5 "50ms" 4 "100ms" 3 "250ms" 2 "500ms" 1 "750ms" 0 "1000ms" ;
VAL_ 2348820455 OverrideCtrlModePriority 3 "LowPriority" 2 "MdmPrrtyUsdFrPwrtrnCtrlOprtnsWh" 1 "HighPriority" 0 "HghstPrrtyUsdFrSttnsThtRqrImmdt" ;
VAL_ 2348820455 EngRqedSpeedCtrlConditions 2 "ThsCtrlCndtnHsBnOptmzdTMnmzRpmO" 3 "StbltyOptmzdFrDrvlnEnggdAnd_OrI" 1 "StbltyOptmzdFrDrvlnDsnggdAndNnl" 0 "ThsSpdGvrnrGnSlctnIsAdjstdTPrvd" ;
VAL_ 2348820455 EngOverrideCtrlMode 3 "Spd_TrqLmtCtrlLmtSpdAnd_OrTrqBs" 2 "TrqCtrlCntrlTrqTInclddDsrdTrqVl" 1 "SpdCtrlGvrnSpdTInclddDsrdSpdVle" 0 "OvrrdDsbldDsblAnyExstngCtrlCmdd" ;
VAL_ 2348875518 ControlPurpose 5 "TemporaryPowerTrainControl" 4 "EngineProtection" 3 "RoadSpeedGovernor" 2 "PTOGovernor" 1 "CruiseControl" 0 "AcceleratorPedal" ;
VAL_ 2348875518 TransmissionRate 7 "UseStandardRate" 6 "25ms" 5 "50ms" 4 "100ms" 3 "250ms" 2 "500ms" 1 "750ms" 0 "1000ms" ;
VAL_ 2348875518 OverrideCtrlModePriority 3 "LowPriority" 2 "MdmPrrtyUsdFrPwrtrnCtrlOprtnsWh" 1 "HighPriority" 0 "HghstPrrtyUsdFrSttnsThtRqrImmdt" ;
VAL_ 2348875518 EngRqedSpeedCtrlConditions 2 "ThsCtrlCndtnHsBnOptmzdTMnmzRpmO" 3 "StbltyOptmzdFrDrvlnEnggdAnd_OrI" 1 "StbltyOptmzdFrDrvlnDsnggdAndNnl" 0 "ThsSpdGvrnrGnSlctnIsAdjstdTPrvd" ;
VAL_ 2348875518 EngOverrideCtrlMode 3 "Spd_TrqLmtCtrlLmtSpdAnd_OrTrqBs" 2 "TrqCtrlCntrlTrqTInclddDsrdTrqVl" 1 "SpdCtrlGvrnSpdTInclddDsrdSpdVle" 0 "OvrrdDsbldDsblAnyExstngCtrlCmdd" ;
VAL_ 2566844711 ParkBrakeReleaseInhibitRq 3 "Unavailable" 2 "SAEReserved" 1 "ParkBrakeReleaseInhibitRqed" 0 "ParkBrakeReleaseInhibitNotRqed" ;
VAL_ 2566844711 EngShutdownOverrideSwitch 3 "NotAvailable" 2 "Error" 1 "On" 0 "Off" ;
VAL_ 2566844711 EngTestModeSwitch 3 "NotAvailable" 2 "Error" 1 "On" 0 "Off" ;
VAL_ 2566844711 EngIdleDecrementSwitch 3 "NotAvailable" 2 "Error" 1 "On" 0 "Off" ;
VAL_ 2566844711 EngIdleIncrementSwitch 3 "NotAvailable" 2 "Error" 1 "On" 0 "Off" ;
VAL_ 2566844711 CruiseCtrlAccelerateSwitch 3 "NotAvailable" 2 "Error" 1 "CrsCtrlActivatorInPosAccelerate" 0 "CrsCtrlActvtrNotInPosAccelerate" ;
VAL_ 2566844711 CruiseCtrlResumeSwitch 3 "NotAvailable" 2 "Error" 1 "CruiseCtrlActivatorInPosResume" 0 "CrseCtrlActivatorNotInPosResume" ;
VAL_ 2566844711 CruiseCtrlCoastSwitch 3 "NotAvailable" 2 "Error" 1 "CruiseCtrlActivatorInPosCoast" 0 "CriseCtrlActivatorNotInPosCoast" ;
VAL_ 2566844711 CruiseCtrlSetSwitch 3 "NotAvailable" 2 "Error" 1 "CruiseCtrlActivatorInPosSet" 0 "CruiseCtrlActivatorNotInPosSet" ;
VAL_ 2566844711 ClutchSwitch 3 "NotAvailable" 2 "Error" 1 "ClutchPedalDepressed" 0 "ClutchPedalReleased" ;
VAL_ 2566844711 BrakeSwitch 3 "NotAvailable" 2 "Error" 1 "BrakePedalDepressed" 0 "BrakePedalReleased" ;
VAL_ 2566844711 CruiseCtrlEnableSwitch 3 "NotAvailable" 2 "Error" 1 "CruiseCtrlEnabled" 0 "CruiseCtrlDisabled" ;
VAL_ 2566844711 CruiseCtrlActive 3 "NotAvailable" 2 "Error" 1 "CruiseCtrlSwitchedOn" 0 "CruiseCtrlSwitchedOff" ;
VAL_ 2566844711 CruiseCtrlPauseSwitch 3 "TakeNoAction" 2 "ErrorIndicator" 1 "On" 0 "Off" ;
VAL_ 2566844711 ParkingBrakeSwitch 3 "NotAvailable" 2 "Error" 1 "ParkingBrakeSet" 0 "ParkingBrakeNotSet" ;
VAL_ 2566844711 TwoSpeedAxleSwitch 3 "NotAvailable" 2 "Error" 1 "HighSpeedRange" 0 "LowSpeedRange" ;
VAL_ 2566844926 ParkBrakeReleaseInhibitRq 3 "Unavailable" 2 "SAEReserved" 1 "ParkBrakeReleaseInhibitRqed" 0 "ParkBrakeReleaseInhibitNotRqed" ;
VAL_ 2566844926 EngShutdownOverrideSwitch 3 "NotAvailable" 2 "Error" 1 "On" 0 "Off" ;
VAL_ 2566844926 EngTestModeSwitch 3 "NotAvailable" 2 "Error" 1 "On" 0 "Off" ;
VAL_ 2566844926 EngIdleDecrementSwitch 3 "NotAvailable" 2 "Error" 1 "On" 0 "Off" ;
VAL_ 2566844926 EngIdleIncrementSwitch 3 "NotAvailable" 2 "Error" 1 "On" 0 "Off" ;
VAL_ 2566844926 CruiseCtrlAccelerateSwitch 3 "NotAvailable" 2 "Error" 1 "CrsCtrlActivatorInPosAccelerate" 0 "CrsCtrlActvtrNotInPosAccelerate" ;
VAL_ 2566844926 CruiseCtrlResumeSwitch 3 "NotAvailable" 2 "Error" 1 "CruiseCtrlActivatorInPosResume" 0 "CrseCtrlActivatorNotInPosResume" ;
VAL_ 2566844926 CruiseCtrlCoastSwitch 3 "NotAvailable" 2 "Error" 1 "CruiseCtrlActivatorInPosCoast" 0 "CriseCtrlActivatorNotInPosCoast" ;
VAL_ 2566844926 CruiseCtrlSetSwitch 3 "NotAvailable" 2 "Error" 1 "CruiseCtrlActivatorInPosSet" 0 "CruiseCtrlActivatorNotInPosSet" ;
VAL_ 2566844926 ClutchSwitch 3 "NotAvailable" 2 "Error" 1 "ClutchPedalDepressed" 0 "ClutchPedalReleased" ;
VAL_ 2566844926 BrakeSwitch 3 "NotAvailable" 2 "Error" 1 "BrakePedalDepressed" 0 "BrakePedalReleased" ;
VAL_ 2566844926 CruiseCtrlEnableSwitch 3 "NotAvailable" 2 "Error" 1 "CruiseCtrlEnabled" 0 "CruiseCtrlDisabled" ;
VAL_ 2566844926 CruiseCtrlActive 3 "NotAvailable" 2 "Error" 1 "CruiseCtrlSwitchedOn" 0 "CruiseCtrlSwitchedOff" ;
VAL_ 2566844926 CruiseCtrlPauseSwitch 3 "TakeNoAction" 2 "ErrorIndicator" 1 "On" 0 "Off" ;
VAL_ 2566844926 ParkingBrakeSwitch 3 "NotAvailable" 2 "Error" 1 "ParkingBrakeSet" 0 "ParkingBrakeNotSet" ;
VAL_ 2566844926 TwoSpeedAxleSwitch 3 "NotAvailable" 2 "Error" 1 "HighSpeedRange" 0 "LowSpeedRange" ;
VAL_ 2566857470 VCVCCU_V2ICP_RequiredEnergyToPre 65535 "SNA" ;
VAL_ 2566857470 VCVCCU_V2ICP_RequiredEnergyToCha 65535 "SNA" ;
VAL_ 2566857470 VCVCCU_V2ICP_RequiredDurationToP 255 "SNA" ;
VAL_ 2566857470 VCVCCU_V2ICP_RequiredDurati_0000 255 "SNA" ;
VAL_ 2349572135 DriverActivDemandForAEBS 3 "Take no action" 2 "Reserved" 1 "Activation of AEBS" 0 "Deactivation of AEBS" ;
VAL_ 2566827568 AirCompressorStatus 3 "NotAvailable" 2 "ErrorIndicator" 1 "CompressorActive" 0 "CompressorNotActive" ;
VAL_ 2362589233 ProhibitAirSuspensionCtrl 3 "NotAvailable" 2 "ErrorIndicator" 1 "RqProhibitAirSuspensionCtrl" 0 "NoRq" ;
VAL_ 2362589233 KneelingCmdRearAxle 3 "DontCare_TakeNoAction" 2 "Reserved" 1 "ActivateKneeling" 0 "DeactivateKneeling" ;
VAL_ 2362589233 KneelingCmdFrontAxle 3 "DontCare_TakeNoAction" 2 "Reserved" 1 "ActivateKneeling" 0 "DeactivateKneeling" ;
VAL_ 2362589233 LevelCtrlModeRq 15 "DontCare_TakeNoAction" 14 "Reserved" 9 "1101NotDefined" 8 "ExhaustBellows" 7 "TractionHelpLoadReduce" 6 "OptmmTrctn2IPrssAtThDrvnAxlIsCt" 5 "OptmmTrctn1IPrssAtThDrvnAxlIsCt" 4 "PrssRt2IRtBtwnThPrssrsAtThDrvnA" 3 "PrssRt1IRtBtwnThPrssrsAtThDrvnA" 2 "LdFxngIDrvnAxlnIsLddTAVlDfndByT" 1 "TrctnHlpIDrvnAxlIsLddTAMxVlGvnB" 0 "NrmlOprtnISystmPrfrmsAPrCtrlOfT" ;
VAL_ 2362589233 NominalLevelRqRearAxle 15 "DontCare_TakeNoAction" 14 "Reserved" 9 "1101NotDefined" 8 "StopLevelChange" 7 "LowerLevel" 6 "UpperLevel" 5 "CustomerLevel" 4 "PresetLevel" 3 "NormalLevel3" 2 "NormalLevel2" 1 "NormalLevel1" 0 "NoLevelRq" ;
VAL_ 2362589233 NominalLevelRqFrontAxle 15 "DontCare_TakeNoAction" 14 "Reserved" 9 "1101NotDefined" 8 "StopLevelChange" 7 "LowerLevel" 6 "UpperLevel" 5 "CustomerLevel" 4 "PresetLevel" 3 "NormalLevel3" 2 "NormalLevel2" 1 "NormalLevel1" 0 "NoLevelRq" ;
VAL_ 2362589233 KneelingCtrlModeRq 3 "DontCare_TakeNoAction" 2 "Reserved" 1 "ManuallyActuated" 0 "AutomaticallyActuated" ;
VAL_ 2362589233 KneelingRqRightSide 3 "DontCare_TakeNoAction" 2 "Reserved" 1 "KneelingRq" 0 "NoKneelingRq" ;
VAL_ 2362589233 KneelingRqLeftSide 3 "DontCare_TakeNoAction" 2 "Reserved" 1 "KneelingRq" 0 "NoKneelingRq" ;
VAL_ 2362589233 AutomaticTractionHelp 3 "DontCare" 2 "Reserved" 1 "EnableAutomaticTractionHelp" 0 "DisableAutomaticTractionHelp" ;
VAL_ 2362589233 LiftAxle2PosCmd 3 "DontCare_TakeNoAction" 2 "Reserved" 1 "LiftAxlePosUp_TagAxleUnladen" 0 "LiftAxlePosDown_TagAxleLaden" ;
VAL_ 2362589233 LiftAxle1PosCmd 3 "DontCare_TakeNoAction" 2 "Reserved" 1 "LiftAxlePosUp_TagAxleUnladen" 0 "LiftAxlePosDown_TagAxleLaden" ;
VAL_ 2362584871 ProhibitAirSuspensionCtrl 3 "NotAvailable" 2 "ErrorIndicator" 1 "RqProhibitAirSuspensionCtrl" 0 "NoRq" ;
VAL_ 2362584871 KneelingCmdRearAxle 3 "DontCare_TakeNoAction" 2 "Reserved" 1 "ActivateKneeling" 0 "DeactivateKneeling" ;
VAL_ 2362584871 KneelingCmdFrontAxle 3 "DontCare_TakeNoAction" 2 "Reserved" 1 "ActivateKneeling" 0 "DeactivateKneeling" ;
VAL_ 2362584871 LevelCtrlModeRq 15 "DontCare_TakeNoAction" 14 "Reserved" 9 "1101NotDefined" 8 "ExhaustBellows" 7 "TractionHelpLoadReduce" 6 "OptmmTrctn2IPrssAtThDrvnAxlIsCt" 5 "OptmmTrctn1IPrssAtThDrvnAxlIsCt" 4 "PrssRt2IRtBtwnThPrssrsAtThDrvnA" 3 "PrssRt1IRtBtwnThPrssrsAtThDrvnA" 2 "LdFxngIDrvnAxlnIsLddTAVlDfndByT" 1 "TrctnHlpIDrvnAxlIsLddTAMxVlGvnB" 0 "NrmlOprtnISystmPrfrmsAPrCtrlOfT" ;
VAL_ 2362584871 NominalLevelRqRearAxle 15 "DontCare_TakeNoAction" 14 "Reserved" 9 "1101NotDefined" 8 "StopLevelChange" 7 "LowerLevel" 6 "UpperLevel" 5 "CustomerLevel" 4 "PresetLevel" 3 "NormalLevel3" 2 "NormalLevel2" 1 "NormalLevel1" 0 "NoLevelRq" ;
VAL_ 2362584871 NominalLevelRqFrontAxle 15 "DontCare_TakeNoAction" 14 "Reserved" 9 "1101NotDefined" 8 "StopLevelChange" 7 "LowerLevel" 6 "UpperLevel" 5 "CustomerLevel" 4 "PresetLevel" 3 "NormalLevel3" 2 "NormalLevel2" 1 "NormalLevel1" 0 "NoLevelRq" ;
VAL_ 2362584871 KneelingCtrlModeRq 3 "DontCare_TakeNoAction" 2 "Reserved" 1 "ManuallyActuated" 0 "AutomaticallyActuated" ;
VAL_ 2362584871 KneelingRqRightSide 3 "DontCare_TakeNoAction" 2 "Reserved" 1 "KneelingRq" 0 "NoKneelingRq" ;
VAL_ 2362584871 KneelingRqLeftSide 3 "DontCare_TakeNoAction" 2 "Reserved" 1 "KneelingRq" 0 "NoKneelingRq" ;
VAL_ 2362584871 AutomaticTractionHelp 3 "DontCare" 2 "Reserved" 1 "EnableAutomaticTractionHelp" 0 "DisableAutomaticTractionHelp" ;
VAL_ 2362584871 LiftAxle2PosCmd 3 "DontCare_TakeNoAction" 2 "Reserved" 1 "LiftAxlePosUp_TagAxleUnladen" 0 "LiftAxlePosDown_TagAxleLaden" ;
VAL_ 2362584871 LiftAxle1PosCmd 3 "DontCare_TakeNoAction" 2 "Reserved" 1 "LiftAxlePosUp_TagAxleUnladen" 0 "LiftAxlePosDown_TagAxleLaden" ;
VAL_ 2566854961 TractionHelpRequest 3 "Na" 2 "Error" 1 "Traction help" 0 "No traction help" ;
VAL_ 2566854961 AVBS_LIN_SwitchState 3 "Not Available" 2 "Error" 1 "Active" 0 "Inactive" ;
VAL_ 2566854961 CityModeSPeedLimit 3 "Not Available" 2 "Error" 1 "Speed Limit Request" 0 "No Speed Limit Request" ;
VAL_ 2566854961 ParkBrakeRequest 1 "Active" 0 "Inactive" ;
VAL_ 2566854961 ParkBrakeInhibitRequest 1 "Active" 0 "Inactive" ;
VAL_ 2566854961 HaltBrakeOverruleRequest 1 "Active" 0 "Inactive" ;
VAL_ 2566854961 ArticulateEmergencyReleaseReq 1 "Active" 0 "Inactive" ;
VAL_ 2566854961 DriverLowVoltageOverrule 3 "Error" 2 "NA" 1 "OverRule" 0 "NoOverrule" ;
VAL_ 2566854961 CreepingDisableRequest 1 "Active" 0 "Inactive" ;
VAL_ 2566854961 VehicleMotionInhibit 1 "Active" 0 "Inactive" ;
VAL_ 2566854961 DriveLineDisengageReq 1 "Active" 0 "Inactive" ;
VAL_ 2566854961 ECASSpeedLimiterReq 1 "Speed Limited" 0 "No SpeedLimit" ;
VAL_ 2566854961 StartInhibitRequest 1 "Active" 0 "Inactive" ;
VAL_ 2566854961 StopStartActive 1 "Active" 0 "Inactive" ;
VAL_ 2566854961 PowerHoldVFC 1 "PowerHold VFC Active" 0 "No PowerHold VFC" ;
VAL_ 2566855552 VCVCCU_V2ICP_ScheduledDepartureT 65535 "SNA" ;
VAL_ 2566855552 VCVCCU_V2ICP_PreconDesiredHVAC 3 "SNA" 2 "no warmwater/cooling/ventilation" 1 "hot water and heating" 0 "only warm water and ventilation" ;
VAL_ 2566855552 VCVCCU_V2ICP_PreconDesired 255 "SNA" 1 "Yes" 0 "No" ;
VAL_ 2566855552 VCVCCU_V2ICP_AmbientTemperature 127 "SNA" ;
VAL_ 2566850535 AmberLampArticulation 3 "Don't Care" 2 "Reserved" 1 "Amber Lamp On" 0 "Amber Lamp Off" ;
VAL_ 2566850535 RedLampArticulation 3 "Don't Care" 2 "Reserved" 1 "Red lamp On" 0 "Red Lamp Off" ;
VAL_ 2566850535 BuzzerArticulation 21 "Don't Care" 3 "Buzzer High Frequency" 2 "Buzzer Low Frequency" 1 "Continues Buzzer" 0 "Buzzer Off" ;
VAL_ 2566850535 HaltbrakeRequestArticulation 3 "Don't Care" 2 "Reserved" 1 "Haltbrake Request On" 0 "Haltbrake Request Off" ;
VAL_ 2365479488 SspensionCtrlRefusalInformation 7 "1101NotDefined" 15 "NotAvailable" 14 "Error" 6 "GnrlRjctINSpcifiedReasonApplies" 5 "BelowSpeedLimit" 4 "AboveSpeedLimit" 3 "BogieDiffNotLocked" 2 "WouldExceedAxleLoadLimit" 1 "AxleLoadLimitReached" 0 "ActualRqNotRefused" ;
VAL_ 2365479488 SuspensionRemoteCtrl2 3 "NotAvailable" 2 "Error" 1 "Active" 0 "NotActive" ;
VAL_ 2365479488 SuspensionRemoteCtrl1 3 "NotAvailable" 2 "Error" 1 "Active" 0 "NotActive" ;
VAL_ 2365479488 RearAxleInBumperRange 3 "NotAvailable" 2 "Error" 1 "ActualLevelWithinBumperRange" 0 "ActualLevelOutOfBumperRange" ;
VAL_ 2365479488 FrontAxleInBumperRange 3 "NotAvailable" 2 "Error" 1 "ActualLevelWithinBumperRange" 0 "ActualLevelOutOfBumperRange" ;
VAL_ 2365479488 DoorRelease 3 "NotAvailable" 2 "Error" 1 "DoorsMayBeOpened" 0 "DoorsMayNotBeOpened" ;
VAL_ 2365479488 VehicleMotionInhibit 3 "NotAvailable" 2 "Error" 1 "VehicleMotionIsInhibited" 0 "VehicleMayBeMoved" ;
VAL_ 2365479488 SecurityDevice 3 "NotAvailable" 2 "Error" 1 "Active" 0 "NotActive" ;
VAL_ 2365479488 LevelCtrlMode 10 "1101NotDefined" 15 "NotAvailable" 14 "Error" 9 "AirSuspensionCtrlProhibited" 8 "ExhstngBllwFnctnIBllwsArExhstdT" 7 "TractionHelpLoadReduce" 6 "OptmmTrctn2IPrssAtThDrvnAxlIsCt" 5 "OptmmTrctn1IPrssAtThDrvnAxlIsCt" 4 "PrssRt2IRtBtwnThPrssrsAtThDrvnA" 3 "PrssRt1IRtBtwnThPrssrsAtThDrvnA" 2 "LdFxngIDrvnAxlnIsLddTAVlDfndByT" 1 "TrctnHlpIDrvnAxlIsLddTAMxVlGvnB" 0 "NrmlOprtnISystmPrfrmsAPrCtrlOfT" ;
VAL_ 2365479488 KneelingInformation 15 "NotAvailable" 14 "Error" 5 "1101NotDefined" 4 "KneelingAborted" 3 "LiftingActive" 2 "KneelingLevelReached" 0 "NotActive" ;
VAL_ 2365479488 LiftingCtrlModeRearAxle 3 "NotAvailable" 2 "Error" 1 "LiftingActive" 0 "LiftingNotActive" ;
VAL_ 2365479488 LiftingCtrlModeFrontAxle 3 "NotAvailable" 2 "Error" 1 "LiftingActive" 0 "LiftingNotActive" ;
VAL_ 2365479488 LoweringCtrlModeRearAxle 3 "NotAvailable" 2 "Error" 1 "LoweringActive" 0 "LoweringNotActive" ;
VAL_ 2365479488 LoweringCtrlModeFrontAxle 3 "NotAvailable" 2 "Error" 1 "LoweringActive" 0 "LoweringNotActive" ;
VAL_ 2365479488 AboveNominalLevelRearAxle 3 "NotAvailable" 2 "Error" 1 "Above" 0 "NotAbove" ;
VAL_ 2365479488 AboveNominalLevelFrontAxle 3 "NotAvailable" 2 "Error" 1 "Above" 0 "NotAbove" ;
VAL_ 2365479488 BelowNominalLevelRearAxle 3 "NotAvailable" 2 "Error" 1 "Below" 0 "NotBelow" ;
VAL_ 2365479488 BelowNominalLevelFrontAxle 3 "NotAvailable" 2 "Error" 1 "Below" 0 "NotBelow" ;
VAL_ 2365479488 NominalLevelRearAxle 15 "NotAvailable" 14 "Error" 8 "1101NotDefined" 7 "LowerLevel" 6 "UpperLevel" 5 "CustomerLevel" 4 "PresetLevel" 3 "NormalLevel3" 2 "NormalLevel2" 1 "NormalLevel1" 0 "LevelNotSpecified" ;
VAL_ 2365479488 NominalLevelFrontAxle 15 "NotAvailable" 14 "Error" 8 "1101NotDefined" 7 "LowerLevel" 6 "UpperLevel" 5 "CustomerLevel" 4 "PresetLevel" 3 "NormalLevel3" 2 "NormalLevel2" 1 "NormalLevel1" 0 "LevelNotSpecified" ;
VAL_ 2365479488 LiftAxle2Pos 3 "NotAvailable" 2 "Error" 1 "LiftAxlePosUp_TagAxleUnladen" 0 "LiftAxlePosDown_TagAxleLaden" ;
VAL_ 2365479488 LiftAxle1Pos 3 "NotAvailable" 2 "Error" 1 "LiftAxlePosUp_TagAxleUnladen" 0 "LiftAxlePosDown_TagAxleLaden" ;
VAL_ 2565865967 TrctrMntdTrilerABSWarningSignal 3 "TakeNoAction" 2 "Reserved" 1 "On" 0 "Off" ;
VAL_ 2565865967 TrailerABSStatus 3 "TrlrABSSttsInfrmtnNtAvlblPrmtrN" 2 "Reserved" 1 "TrailerABSActive" 0 "TrlrABSSttsInfrmtnAvlblBtNtActv" ;
VAL_ 2565865967 HaltBrakeSwitch 3 "NotAvailable" 2 "Error" 1 "HaltBrakeSwitchActive" 0 "HaltBrakeSwitchPassive" ;
VAL_ 2565865967 ATC_ASRInformationSignal 3 "TakeNoAction" 2 "Reserved" 1 "On" 0 "Off" ;
VAL_ 2565865967 ABS_EBSAmberWarningSignal 3 "TakeNoAction" 2 "Reserved" 1 "On" 0 "Off" ;
VAL_ 2565865967 EBSRedWarningSignal 3 "TakeNoAction" 2 "Reserved" 1 "On" 0 "Off" ;
VAL_ 2565865967 ABSFullyOperational 3 "NotAvailable" 2 "Reserved" 1 "FullyOperational" 0 "NotFullyOperational" ;
VAL_ 2565865967 RemoteAccelEnableSwitch 3 "NotAvailable" 2 "Error" 1 "On" 0 "Off" ;
VAL_ 2565865967 EngAuxEngShutdownSwitch 3 "NotAvailable" 2 "Error" 1 "On" 0 "Off" ;
VAL_ 2565865967 EngDerateSwitch 3 "NotAvailable" 2 "Error" 1 "On" 0 "Off" ;
VAL_ 2565865967 AccelInterlockSwitch 3 "NotAvailable" 2 "Error" 1 "On" 0 "Off" ;
VAL_ 2565865967 TractionCtrlOverrideSwitch 3 "NotAvailableNotInstalled" 2 "Error" 1 "On" 0 "Off" ;
VAL_ 2565865967 ASRHillHolderSwitch 3 "NotAvailable" 2 "Error" 1 "ASRHillHolderSwitchActive" 0 "ASRHillHolderSwitchPassive" ;
VAL_ 2565865967 ASROffroadSwitch 2 "Error" 1 "ASROffroadSwitchActive" 0 "ASROffroadSwitchPassive" 3 "NotAvailable" ;
VAL_ 2565865967 ABSOffroadSwitch 3 "NotAvailable" 2 "Error" 1 "ABSOffroadSwitchActive" 0 "ABSOffroadSwitchPassive" ;
VAL_ 2565865967 EBSBrakeSwitch 3 "NotAvailable" 2 "Error" 1 "BrakePedalIsBeingPressed" 0 "BrakePedalIsNotBeingPressed" ;
VAL_ 2565865967 AntiLockBrakingActive 3 "NotAvailable" 2 "Reserved" 1 "ABSActive" 0 "ABSPassiveButInstalled" ;
VAL_ 2565865967 ASRBrakeCtrlActive 3 "NotAvailable" 2 "Reserved" 1 "ASRBrakeCtrlActive" 0 "ASRBrakeCtrlPassiveButInstalled" ;
VAL_ 2565865967 ASREngCtrlActive 3 "NotAvailable" 2 "Reserved" 1 "ASREngCtrlActive" 0 "ASREngCtrlPassiveButInstalled" ;
